VERSION "HNNBNNNYNNNNNNNNNNNNNNNNNNNNNNNNNNNNNNNNNN/4/%%%/4/'%**4NNN///"

NS_ :

BS_:

BU_: BAP_Tester BedienDisp_vo BedienSG_hi CGS DDA Gateway Gateway_PAG GurtMikrofon OTA_FC ZR_High ZR_LIMU ZR_MIB_TOP_ab_Gen3 ZR_Standard

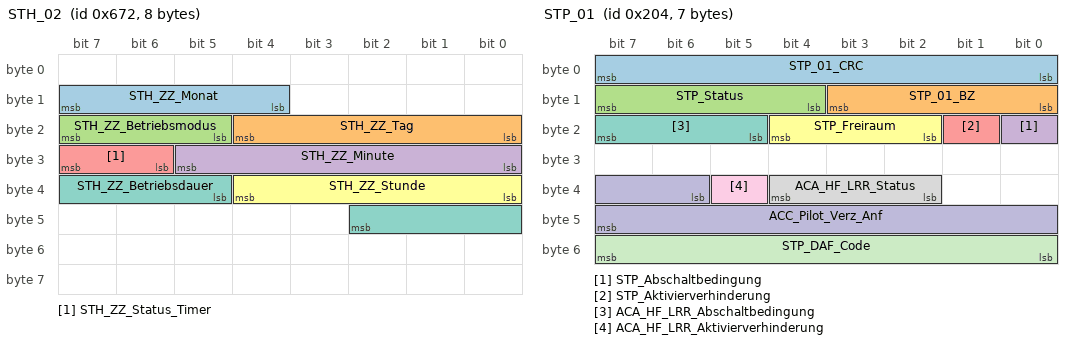
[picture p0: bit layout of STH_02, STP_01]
BO_ 1650 STH_02: 8 Gateway
 SG_ STH_ZZ_Monat : 12|4@1+ (1,0) [1|12] ""  ZR_High
 SG_ STH_ZZ_Tag : 16|5@1+ (1,0) [1|31] "Unit_Day"  ZR_High
 SG_ STH_ZZ_Betriebsmodus : 21|3@1+ (1.0,0.0) [0.0|7] ""  ZR_High
 SG_ STH_ZZ_Minute : 24|6@1+ (1,0) [0|59] ""  ZR_High
 SG_ STH_ZZ_Status_Timer : 30|2@1+ (1.0,0.0) [0.0|3] ""  ZR_High
 SG_ STH_ZZ_Stunde : 32|5@1+ (1,0) [0|23] ""  ZR_High
 SG_ STH_ZZ_Betriebsdauer : 37|6@1+ (1,0) [0|63] "Unit_Minut"  ZR_High

BO_ 516 STP_01: 7 Gateway
 SG_ STP_01_CRC : 0|8@1+ (1,0) [0|255] ""  Vector__XXX
 SG_ STP_01_BZ : 8|4@1+ (1,0) [0|15] ""  Vector__XXX
 SG_ STP_Status : 12|4@1+ (1.0,0.0) [0.0|15] ""  ZR_High,ZR_LIMU,ZR_MIB_TOP_ab_Gen3,ZR_Standard
 SG_ STP_Abschaltbedingung : 16|1@1+ (1.0,0.0) [0.0|1] ""  ZR_High
 SG_ STP_Aktivierverhinderung : 17|1@1+ (1.0,0.0) [0.0|1] ""  Vector__XXX
 SG_ STP_Freiraum : 18|3@1+ (1.0,0.0) [0.0|7] ""  ZR_High
 SG_ ACA_HF_LRR_Abschaltbedingung : 21|3@1+ (1.0,0.0) [0.0|7] ""  Vector__XXX
 SG_ ACA_HF_LRR_Status : 34|3@1+ (1.0,0.0) [0.0|7] ""  Vector__XXX
 SG_ ACA_HF_LRR_Aktivierverhinderung : 37|1@1+ (1.0,0.0) [0.0|1] ""  Vector__XXX
 SG_ ACC_Pilot_Verz_Anf : 38|10@1+ (0.024,-24.528) [-24.528|-0.024] "Unit_MeterPerSeconSquar"  Vector__XXX
 SG_ STP_DAF_Code : 48|8@1+ (1,0) [1|255] ""  Vector__XXX

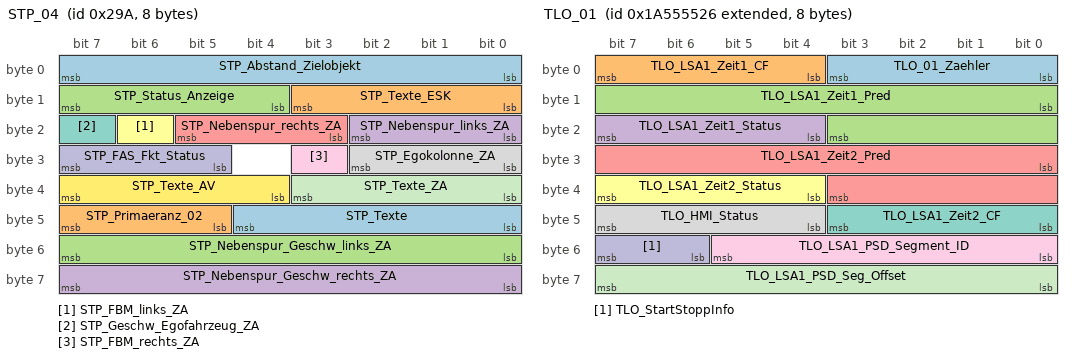
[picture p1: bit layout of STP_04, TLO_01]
BO_ 666 STP_04: 8 Gateway
 SG_ STP_Abstand_Zielobjekt : 0|8@1+ (1,0) [1|250] ""  Vector__XXX
 SG_ STP_Texte_ESK : 8|4@1+ (1.0,0.0) [0.0|15] ""  ZR_High,ZR_LIMU,ZR_MIB_TOP_ab_Gen3
 SG_ STP_Status_Anzeige : 12|4@1+ (1.0,0.0) [0.0|15] ""  ZR_High
 SG_ STP_Nebenspur_links_ZA : 16|3@1+ (1.0,0.0) [0.0|7] ""  ZR_High
 SG_ STP_Nebenspur_rechts_ZA : 19|3@1+ (1.0,0.0) [0.0|7] ""  ZR_High
 SG_ STP_FBM_links_ZA : 22|1@1+ (1.0,0.0) [0.0|1] ""  ZR_High
 SG_ STP_Geschw_Egofahrzeug_ZA : 23|1@1+ (1.0,0.0) [0.0|1] ""  Vector__XXX
 SG_ STP_Egokolonne_ZA : 24|3@1+ (1.0,0.0) [0.0|7] ""  ZR_High
 SG_ STP_FBM_rechts_ZA : 27|1@1+ (1.0,0.0) [0.0|1] ""  ZR_High
 SG_ STP_FAS_Fkt_Status : 29|3@1+ (1.0,0.0) [0.0|7] ""  ZR_High
 SG_ STP_Texte_ZA : 32|4@1+ (1.0,0.0) [0.0|15] ""  ZR_High
 SG_ STP_Texte_AV : 36|4@1+ (1.0,0.0) [0.0|15] ""  ZR_High,ZR_LIMU,ZR_MIB_TOP_ab_Gen3
 SG_ STP_Texte : 40|5@1+ (1.0,0.0) [0.0|31] ""  ZR_High,ZR_LIMU,ZR_MIB_TOP_ab_Gen3
 SG_ STP_Primaeranz_02 : 45|3@1+ (1.0,0.0) [0.0|7] ""  Vector__XXX
 SG_ STP_Nebenspur_Geschw_links_ZA : 48|8@1+ (1,0) [0|250] "Unit_KiloMeterPerHour"  Vector__XXX
 SG_ STP_Nebenspur_Geschw_rechts_ZA : 56|8@1+ (1,0) [0|250] "Unit_KiloMeterPerHour"  Vector__XXX

BO_ 1172 STS_01: 8 Gateway
 SG_ STS_01_CRC : 0|8@1+ (1,0) [0|255] ""  Vector__XXX
 SG_ STS_01_BZ : 8|4@1+ (1,0) [0|15] ""  Vector__XXX
 SG_ STS_Car_not_under_theft : 12|1@1+ (1.0,0.0) [0.0|1] ""  Vector__XXX
 SG_ STS_Car_under_theft : 13|1@1+ (1.0,0.0) [0.0|1] ""  Vector__XXX
 SG_ STS_Door_Lock : 14|1@1+ (1.0,0.0) [0.0|1] ""  ZR_High
 SG_ STS_Anlassersperre : 15|1@1+ (1.0,0.0) [0.0|1] ""  ZR_High
 SG_ STS_Typencodierung : 16|5@1+ (1.0,0.0) [0.0|31] ""  ZR_High
 SG_ STS_Spiegel_Anklappen : 21|1@1+ (1.0,0.0) [0.0|1] ""  ZR_High
 SG_ GW_STS2_Privatsphaere : 22|1@1+ (1.0,0.0) [0.0|1] ""  Vector__XXX
 SG_ STS_LIN_aktiv : 23|1@1+ (1.0,0.0) [0.0|1] ""  Vector__XXX
 SG_ STS_Standlicht : 24|1@1+ (1.0,0.0) [0.0|1] ""  Vector__XXX
 SG_ STS_Fahrlicht : 25|1@1+ (1.0,0.0) [0.0|1] ""  Vector__XXX
 SG_ STS_Alarm_still : 26|1@1+ (1.0,0.0) [0.0|1] ""  Vector__XXX
 SG_ STS_Texte : 27|4@1+ (1.0,0.0) [0.0|15] ""  Vector__XXX
 SG_ STS_Laderelais : 38|1@1+ (1.0,0.0) [0.0|1] ""  Vector__XXX
 SG_ STS_Summer : 48|1@1+ (1.0,0.0) [0.0|1] ""  Vector__XXX
 SG_ STS_Alarm_Blinker : 50|1@1+ (1.0,0.0) [0.0|1] ""  Vector__XXX
 SG_ STS_Notstart : 51|1@1+ (1.0,0.0) [0.0|1] ""  Vector__XXX
 SG_ STS_Signalhorn : 55|1@1+ (1.0,0.0) [0.0|1] ""  Vector__XXX
 SG_ STS_Leerlaufschaltung : 56|1@1+ (1.0,0.0) [0.0|1] ""  Vector__XXX

BO_ 783 SWA_01: 8 Gateway
 SG_ SWA_01_CRC : 0|8@1+ (1,0) [0|255] ""  Vector__XXX
 SG_ SWA_01_BZ : 8|4@1+ (1,0) [0|15] ""  Vector__XXX
 SG_ SWA_Anzeigen : 12|4@1+ (1.0,0.0) [0.0|15] ""  ZR_High
 SG_ SWA_Blindheit_erkannt : 16|1@1+ (1.0,0.0) [0.0|1] ""  Vector__XXX
 SG_ SWA_rel_Nichtverf : 17|1@1+ (1.0,0.0) [0.0|1] ""  Vector__XXX
 SG_ SWA_rel_Fehler : 18|1@1+ (1.0,0.0) [0.0|1] ""  ZR_High
 SG_ SWA_Sta_aktiv : 19|1@1+ (1.0,0.0) [0.0|1] ""  ZR_High
 SG_ SWA_Sta_passiv : 20|1@1+ (1.0,0.0) [0.0|1] ""  ZR_High
 SG_ SWA_FT_RueckLED : 21|1@1+ (1.0,0.0) [0.0|1] ""  ZR_High
 SG_ ASW_Status : 22|2@1+ (1.0,0.0) [0.0|3] ""  ZR_High
 SG_ SWA_Standziele_li : 24|1@1+ (1.0,0.0) [0.0|1] ""  ZR_High
 SG_ SWA_Kolonne_li : 25|1@1+ (1.0,0.0) [0.0|1] ""  Vector__XXX
 SG_ SWA_Infostufe_SWA_li : 26|1@1+ (1.0,0.0) [0.0|1] ""  ZR_High
 SG_ SWA_Warnung_SWA_li : 27|1@1+ (1.0,0.0) [0.0|1] ""  ZR_High
 SG_ ASW_Warnung_FS : 28|1@1+ (1.0,0.0) [0.0|1] ""  ZR_High
 SG_ ASW_Warnung_BFS : 29|1@1+ (1.0,0.0) [0.0|1] ""  ZR_High
 SG_ ASW_Kombitexte : 30|3@1+ (1.0,0.0) [0.0|7] ""  ZR_High
 SG_ SWA_Kolonne_mi : 33|1@1+ (1.0,0.0) [0.0|1] ""  Vector__XXX
 SG_ ASW_Modus : 34|3@1+ (1.0,0.0) [0.0|7] ""  ZR_High
 SG_ SWA_Modus : 37|3@1+ (1.0,0.0) [0.0|7] ""  ZR_High
 SG_ SWA_Standziele_re : 40|1@1+ (1.0,0.0) [0.0|1] ""  Vector__XXX
 SG_ SWA_Kolonne_re : 41|1@1+ (1.0,0.0) [0.0|1] ""  Vector__XXX
 SG_ SWA_Infostufe_SWA_re : 42|1@1+ (1.0,0.0) [0.0|1] ""  ZR_High
 SG_ SWA_Warnung_SWA_re : 43|1@1+ (1.0,0.0) [0.0|1] ""  ZR_High
 SG_ HRE_Anzeigetexte : 44|4@1+ (1.0,0.0) [0.0|15] ""  Vector__XXX
 SG_ SWA_Status_02 : 48|2@1+ (1.0,0.0) [0.0|3] ""  Vector__XXX
 SG_ Heckradar_Kombitexte : 56|5@1+ (1.0,0.0) [0.0|31] ""  ZR_High
 SG_ RCTA_Kombitexte : 61|3@1+ (1.0,0.0) [0.0|7] ""  ZR_High

BO_ 1413 Systeminfo_01: 8 Gateway
 SG_ SI_Sammel_SG_Fehler : 0|6@1+ (1,0) [0|60] ""  ZR_High,ZR_LIMU,ZR_MIB_TOP_ab_Gen3,ZR_Standard
 SG_ SI_Diagnose_Aktiv : 7|1@1+ (1.0,0.0) [0.0|1] ""  ZR_High,ZR_LIMU,ZR_MIB_TOP_ab_Gen3,ZR_Standard
 SG_ SI_QRS_Mode : 8|1@1+ (1.0,0.0) [0.0|1] ""  BedienSG_hi,ZR_High,ZR_LIMU,ZR_MIB_TOP_ab_Gen3,ZR_Standard
 SG_ SI_T_Mode : 9|1@1+ (1.0,0.0) [0.0|1] ""  BedienDisp_vo,BedienSG_hi,DDA,ZR_High,ZR_LIMU,ZR_MIB_TOP_ab_Gen3,ZR_Standard
 SG_ SI_NWDF : 10|1@1+ (1.0,0.0) [0.0|1] ""  BedienDisp_vo,BedienSG_hi,DDA,ZR_High,ZR_LIMU,ZR_MIB_TOP_ab_Gen3,ZR_Standard
 SG_ SI_NWDF_gueltig : 11|1@1+ (1.0,0.0) [0.0|1] ""  BedienDisp_vo,BedienSG_hi,DDA,ZR_High,ZR_LIMU,ZR_MIB_TOP_ab_Gen3,ZR_Standard
 SG_ SI_Sammelfehler : 12|1@1+ (1.0,0.0) [0.0|1] ""  ZR_High,ZR_LIMU,ZR_MIB_TOP_ab_Gen3,ZR_Standard
 SG_ GW_KD_Fehler : 13|1@1+ (1.0,0.0) [0.0|1] ""  ZR_High,ZR_MIB_TOP_ab_Gen3,ZR_Standard
 SG_ SI_T_Schutz : 14|1@1+ (1.0,0.0) [0.0|1] ""  BedienSG_hi,ZR_High,ZR_LIMU,ZR_MIB_TOP_ab_Gen3,ZR_Standard
 SG_ SI_BUS_01 : 16|1@1+ (1.0,0.0) [0.0|1] ""  ZR_High,ZR_LIMU,ZR_MIB_TOP_ab_Gen3,ZR_Standard
 SG_ SI_BUS_02 : 17|1@1+ (1.0,0.0) [0.0|1] ""  ZR_High,ZR_LIMU,ZR_MIB_TOP_ab_Gen3,ZR_Standard
 SG_ SI_BUS_03 : 18|1@1+ (1.0,0.0) [0.0|1] ""  BedienSG_hi,DDA,ZR_High,ZR_LIMU,ZR_MIB_TOP_ab_Gen3,ZR_Standard
 SG_ SI_BUS_04 : 19|1@1+ (1.0,0.0) [0.0|1] ""  BedienSG_hi,ZR_High,ZR_LIMU,ZR_MIB_TOP_ab_Gen3,ZR_Standard
 SG_ SI_BUS_05 : 20|1@1+ (1.0,0.0) [0.0|1] ""  ZR_High,ZR_LIMU,ZR_MIB_TOP_ab_Gen3,ZR_Standard
 SG_ SI_BUS_06 : 21|1@1+ (1.0,0.0) [0.0|1] ""  ZR_High,ZR_LIMU,ZR_MIB_TOP_ab_Gen3,ZR_Standard
 SG_ SI_BUS_07 : 22|1@1+ (1.0,0.0) [0.0|1] ""  ZR_High,ZR_LIMU,ZR_MIB_TOP_ab_Gen3,ZR_Standard
 SG_ SI_BUS_08 : 23|1@1+ (1.0,0.0) [0.0|1] ""  ZR_High,ZR_LIMU,ZR_MIB_TOP_ab_Gen3,ZR_Standard
 SG_ SI_BUS_09 : 24|1@1+ (1.0,0.0) [0.0|1] ""  ZR_High,ZR_LIMU,ZR_MIB_TOP_ab_Gen3,ZR_Standard
 SG_ SI_BUS_10 : 25|1@1+ (1.0,0.0) [0.0|1] ""  BedienSG_hi,DDA,ZR_High,ZR_LIMU,ZR_MIB_TOP_ab_Gen3,ZR_Standard
 SG_ SI_BUS_11 : 26|1@1+ (1.0,0.0) [0.0|1] ""  ZR_High,ZR_LIMU,ZR_MIB_TOP_ab_Gen3,ZR_Standard
 SG_ SI_BUS_12 : 27|1@1+ (1.0,0.0) [0.0|1] ""  DDA,ZR_High,ZR_LIMU,ZR_MIB_TOP_ab_Gen3,ZR_Standard
 SG_ SI_BUS_13 : 28|1@1+ (1.0,0.0) [0.0|1] ""  ZR_High,ZR_LIMU,ZR_MIB_TOP_ab_Gen3,ZR_Standard
 SG_ SI_BUS_14 : 29|1@1+ (1.0,0.0) [0.0|1] ""  ZR_High,ZR_LIMU,ZR_MIB_TOP_ab_Gen3,ZR_Standard
 SG_ SI_BUS_15 : 30|1@1+ (1.0,0.0) [0.0|1] ""  ZR_High,ZR_LIMU,ZR_MIB_TOP_ab_Gen3,ZR_Standard
 SG_ SI_Bus_Identifikation : 32|8@1+ (1.0,0.0) [0.0|255] ""  OTA_FC,ZR_High,ZR_LIMU,ZR_MIB_TOP_ab_Gen3,ZR_Standard
 SG_ SI_CAB : 40|24@1+ (1.0,0.0) [0.0|16777215] ""  BedienSG_hi,OTA_FC,ZR_High,ZR_LIMU,ZR_MIB_TOP_ab_Gen3,ZR_Standard

BO_ 2589283622 TLO_01: 8 ZR_High
 SG_ TLO_01_Zaehler : 0|4@1+ (1,0) [0|15] ""  Gateway,Gateway_PAG
 SG_ TLO_LSA1_Zeit1_CF : 4|4@1+ (1,0) [0|15] "Unit_None"  Gateway,Gateway_PAG
 SG_ TLO_LSA1_Zeit1_Pred : 8|12@1+ (0.1,-0.1) [0.0|409.4] "Unit_Secon"  Gateway,Gateway_PAG
 SG_ TLO_LSA1_Zeit1_Status : 20|4@1+ (1.0,0.0) [0.0|15] ""  Gateway,Gateway_PAG
 SG_ TLO_LSA1_Zeit2_Pred : 24|12@1+ (0.1,-0.1) [0.0|409.4] "Unit_Secon"  Gateway,Gateway_PAG
 SG_ TLO_LSA1_Zeit2_Status : 36|4@1+ (1.0,0.0) [0.0|15] ""  Gateway,Gateway_PAG
 SG_ TLO_LSA1_Zeit2_CF : 40|4@1+ (1,0) [0|15] "Unit_None"  Gateway,Gateway_PAG
 SG_ TLO_HMI_Status : 44|4@1+ (1.0,0.0) [0.0|15] ""  Gateway,Gateway_PAG
 SG_ TLO_LSA1_PSD_Segment_ID : 48|6@1+ (1,0) [2|63] "Unit_None"  Gateway,Gateway_PAG
 SG_ TLO_StartStoppInfo : 54|2@1+ (1.0,0.0) [0.0|3] ""  Gateway,Gateway_PAG
 SG_ TLO_LSA1_PSD_Seg_Offset : 56|8@1+ (1,0) [0|254] "Unit_Meter"  Gateway,Gateway_PAG

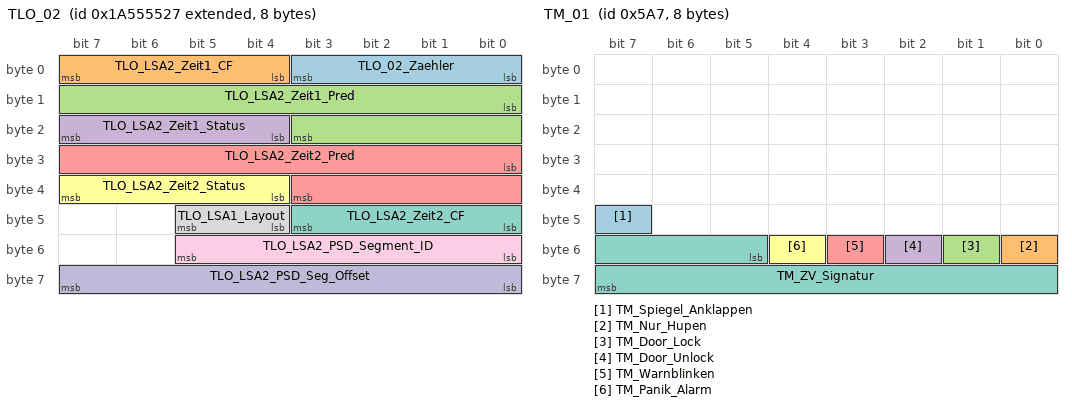
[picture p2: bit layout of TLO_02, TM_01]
BO_ 2589283623 TLO_02: 8 ZR_High
 SG_ TLO_02_Zaehler : 0|4@1+ (1,0) [0|15] ""  Gateway,Gateway_PAG
 SG_ TLO_LSA2_Zeit1_CF : 4|4@1+ (1,0) [0|15] "Unit_None"  Gateway,Gateway_PAG
 SG_ TLO_LSA2_Zeit1_Pred : 8|12@1+ (0.1,-0.1) [0.0|409.4] "Unit_Secon"  Gateway,Gateway_PAG
 SG_ TLO_LSA2_Zeit1_Status : 20|4@1+ (1.0,0.0) [0.0|15] ""  Gateway,Gateway_PAG
 SG_ TLO_LSA2_Zeit2_Pred : 24|12@1+ (0.1,-0.1) [0.0|409.4] "Unit_Secon"  Gateway,Gateway_PAG
 SG_ TLO_LSA2_Zeit2_Status : 36|4@1+ (1.0,0.0) [0.0|15] ""  Gateway,Gateway_PAG
 SG_ TLO_LSA2_Zeit2_CF : 40|4@1+ (1,0) [0|15] "Unit_None"  Gateway,Gateway_PAG
 SG_ TLO_LSA1_Layout : 44|2@1+ (1.0,0.0) [0.0|3] ""  Gateway,Gateway_PAG
 SG_ TLO_LSA2_PSD_Segment_ID : 48|6@1+ (1,0) [2|63] "Unit_None"  Gateway,Gateway_PAG
 SG_ TLO_LSA2_PSD_Seg_Offset : 56|8@1+ (1,0) [0|254] "Unit_Meter"  Gateway,Gateway_PAG

BO_ 1447 TM_01: 8 Gateway
 SG_ TM_Spiegel_Anklappen : 47|1@1+ (1.0,0.0) [0.0|1] ""  ZR_High
 SG_ TM_Nur_Hupen : 48|1@1+ (1.0,0.0) [0.0|1] ""  ZR_High
 SG_ TM_Door_Lock : 49|1@1+ (1.0,0.0) [0.0|1] ""  Vector__XXX
 SG_ TM_Door_Unlock : 50|1@1+ (1.0,0.0) [0.0|1] ""  Vector__XXX
 SG_ TM_Warnblinken : 51|1@1+ (1.0,0.0) [0.0|1] ""  ZR_High
 SG_ TM_Panik_Alarm : 52|1@1+ (1.0,0.0) [0.0|1] ""  ZR_High
 SG_ TM_ZV_Signatur : 53|11@1+ (1,0) [1|2047] "Unit_None"  Vector__XXX

BO_ 977 TSG_BT_01: 8 Gateway
 SG_ BT_Tuer_geoeffnet : 0|1@1+ (1.0,0.0) [0.0|1] ""  OTA_FC,ZR_High,ZR_LIMU,ZR_MIB_TOP_ab_Gen3,ZR_Standard
 SG_ BT_verriegelt : 1|1@1+ (1.0,0.0) [0.0|1] ""  OTA_FC,ZR_High
 SG_ BT_gesafet : 2|1@1+ (1.0,0.0) [0.0|1] ""  ZR_High
 SG_ BT_Schluesselschalter_auf : 3|1@1+ (1.0,0.0) [0.0|1] ""  ZR_High
 SG_ BT_Schluesselschalter_zu : 4|1@1+ (1.0,0.0) [0.0|1] ""  ZR_High
 SG_ BT_Unlock_Taster : 5|1@1+ (1.0,0.0) [0.0|1] ""  ZR_High
 SG_ BT_Lock_Taster : 6|1@1+ (1.0,0.0) [0.0|1] ""  ZR_High
 SG_ BT_Sperrklinke : 7|1@1+ (1.0,0.0) [0.0|1] ""  Vector__XXX
 SG_ BT_TAG_betaetigt : 8|1@1+ (1.0,0.0) [0.0|1] ""  ZR_High
 SG_ BT_TIG_betaetigt : 9|1@1+ (1.0,0.0) [0.0|1] ""  ZR_High
 SG_ BT_EC_Spiegel_Helligkeit : 10|5@1+ (3.125,0) [0.000|96.875] "Unit_PerCent"  OTA_FC,ZR_High
 SG_ BT_Sp_Heizung_Anf : 15|1@1+ (100,0) [0|100] "Unit_PerCent"  ZR_High
 SG_ BT_Tuer_Status : 16|2@1+ (1.0,0.0) [0.0|3] ""  OTA_FC,ZR_High
 SG_ BT_TSG_hinten_verbaut : 18|1@1+ (1.0,0.0) [0.0|1] ""  ZR_High
 SG_ BT_Sp_Blk_def : 19|1@1+ (1.0,0.0) [0.0|1] ""  ZR_High
 SG_ BT_FH_S_ManHoch : 20|1@1+ (1.0,0.0) [0.0|1] ""  ZR_High
 SG_ BT_FH_S_AutoHoch : 21|1@1+ (1.0,0.0) [0.0|1] ""  ZR_High
 SG_ BT_FH_S_ManTief : 22|1@1+ (1.0,0.0) [0.0|1] ""  ZR_High
 SG_ BT_FH_S_AutoTief : 23|1@1+ (1.0,0.0) [0.0|1] ""  ZR_High
 SG_ BT_FH_Oeffnung : 24|8@1+ (0.5,0) [0.0|100.0] "Unit_PerCent"  DDA,OTA_FC,ZR_High,ZR_LIMU,ZR_MIB_TOP_ab_Gen3,ZR_Standard
 SG_ BT_FH_Bew_hoch : 32|1@1+ (1.0,0.0) [0.0|1] ""  ZR_High
 SG_ BT_FH_Bew_tief : 33|1@1+ (1.0,0.0) [0.0|1] ""  ZR_High
 SG_ BT_FH_Fang : 34|1@1+ (1.0,0.0) [0.0|1] ""  ZR_High
 SG_ BT_FH_Block : 35|1@1+ (1.0,0.0) [0.0|1] ""  ZR_High
 SG_ BT_FH_Thermo : 36|1@1+ (1.0,0.0) [0.0|1] ""  ZR_High
 SG_ BT_UEKB_aktiviert : 37|1@1+ (1.0,0.0) [0.0|1] ""  Vector__XXX
 SG_ BT_Kisi_Fehler : 38|1@1+ (1.0,0.0) [0.0|1] ""  ZR_High
 SG_ BT_FH_normiert : 39|1@1+ (1.0,0.0) [0.0|1] ""  Vector__XXX
 SG_ BT_Schliesstaster : 40|1@1+ (1.0,0.0) [0.0|1] ""  ZR_High
 SG_ BT_Zuziehhilfe_aktiv : 41|1@1+ (1.0,0.0) [0.0|1] ""  OTA_FC,ZR_High
 SG_ BT_SP_ausgerastet : 42|1@1+ (1.0,0.0) [0.0|1] ""  ZR_High
 SG_ BT_SP_lr_aktiv : 43|1@1+ (1.0,0.0) [0.0|1] ""  ZR_High
 SG_ BT_SP_ht_aktiv : 44|1@1+ (1.0,0.0) [0.0|1] ""  ZR_High
 SG_ BT_SP_Heizung_aktiv : 45|1@1+ (1.0,0.0) [0.0|1] ""  Vector__XXX
 SG_ BT_Oben_Block_erw : 46|1@1+ (1.0,0.0) [0.0|1] ""  ZR_High
 SG_ BT_Unten_Block_erw : 47|1@1+ (1.0,0.0) [0.0|1] ""  ZR_High
 SG_ BT_Tuer_Status_QBit : 48|1@1+ (1.0,0.0) [0.0|1] ""  Vector__XXX
 SG_ BFS_Status_eTAG : 49|2@1+ (1.0,0.0) [0.0|3] ""  Vector__XXX
 SG_ BT_TCR_Mode_aktiv : 51|1@1+ (1.0,0.0) [0.0|1] ""  Vector__XXX
 SG_ BT_SP_Heizung_Status : 55|1@1+ (1.0,0.0) [0.0|1] ""  OTA_FC,ZR_High
 SG_ ASW_Warnung_aktiv_BFS : 56|1@1+ (1.0,0.0) [0.0|1] ""  ZR_High
 SG_ BT_FH_Pos_oben : 57|1@1+ (1.0,0.0) [0.0|1] ""  OTA_FC,ZR_High
 SG_ BT_Tuerschloss_defekt : 58|1@1+ (1.0,0.0) [0.0|1] ""  ZR_High
 SG_ BT_Tueroeffnen_Warnung : 59|1@1+ (1.0,0.0) [0.0|1] ""  Vector__XXX
 SG_ BT_Lock_Taster_inv : 60|1@1+ (1.0,0.0) [0.0|1] ""  ZR_High
 SG_ BT_Schluesselschalter_zu_inv : 61|1@1+ (1.0,0.0) [0.0|1] ""  ZR_High
 SG_ BT_SWA_HMI_defekt : 62|1@1+ (1.0,0.0) [0.0|1] ""  ZR_High
 SG_ BT_ASW_HMI_defekt : 63|1@1+ (1.0,0.0) [0.0|1] ""  ZR_High

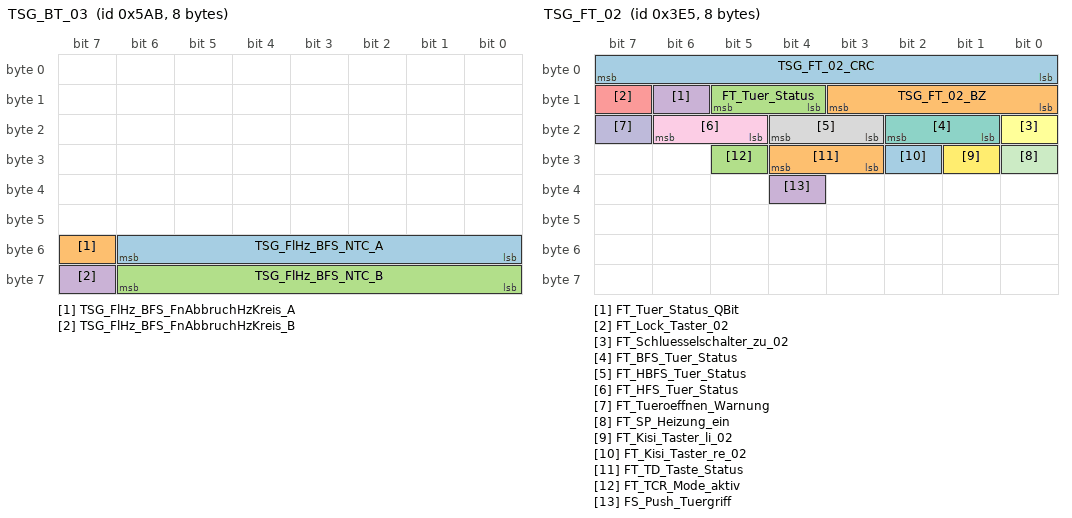
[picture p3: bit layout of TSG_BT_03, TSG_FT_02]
BO_ 1451 TSG_BT_03: 8 Gateway
 SG_ TSG_FlHz_BFS_NTC_A : 48|7@1+ (1,-40) [-40|80] "Unit_DegreCelsi"  ZR_High
 SG_ TSG_FlHz_BFS_FnAbbruchHzKreis_A : 55|1@1+ (1.0,0.0) [0.0|1] ""  ZR_High
 SG_ TSG_FlHz_BFS_NTC_B : 56|7@1+ (1,-40) [-40|80] "Unit_DegreCelsi"  ZR_High
 SG_ TSG_FlHz_BFS_FnAbbruchHzKreis_B : 63|1@1+ (1.0,0.0) [0.0|1] ""  ZR_High

BO_ 976 TSG_FT_01: 8 Gateway
 SG_ FT_Tuer_geoeffnet : 0|1@1+ (1.0,0.0) [0.0|1] ""  BedienDisp_vo,OTA_FC,ZR_High,ZR_LIMU,ZR_MIB_TOP_ab_Gen3,ZR_Standard
 SG_ FT_verriegelt : 1|1@1+ (1.0,0.0) [0.0|1] ""  OTA_FC,ZR_High
 SG_ FT_gesafet : 2|1@1+ (1.0,0.0) [0.0|1] ""  ZR_High
 SG_ FT_Schluesselschalter_auf : 3|1@1+ (1.0,0.0) [0.0|1] ""  ZR_High
 SG_ FT_Schluesselschalter_zu : 4|1@1+ (1.0,0.0) [0.0|1] ""  ZR_High
 SG_ FT_Unlock_Taster : 5|1@1+ (1.0,0.0) [0.0|1] ""  ZR_High
 SG_ FT_Lock_Taster : 6|1@1+ (1.0,0.0) [0.0|1] ""  ZR_High
 SG_ FT_Sperrklinke : 7|1@1+ (1.0,0.0) [0.0|1] ""  ZR_High
 SG_ FT_TAG_betaetigt : 8|1@1+ (1.0,0.0) [0.0|1] ""  ZR_High
 SG_ FT_TIG_betaetigt : 9|1@1+ (1.0,0.0) [0.0|1] ""  ZR_High
 SG_ FT_IRUE_Taste : 10|1@1+ (1.0,0.0) [0.0|1] ""  ZR_High
 SG_ FT_HD_Taste : 11|1@1+ (1.0,0.0) [0.0|1] ""  OTA_FC,ZR_High
 SG_ FT_TD_Taste_Fehler : 12|1@1+ (1.0,0.0) [0.0|1] ""  ZR_High
 SG_ FT_TD_Taste : 13|1@1+ (1.0,0.0) [0.0|1] ""  OTA_FC,ZR_High
 SG_ SSR_Temp_Freigabe : 14|1@1+ (1.0,0.0) [0.0|1] ""  Vector__XXX
 SG_ FT_Sp_Heizung_Anf : 15|1@1+ (100,0) [0|100] "Unit_PerCent"  OTA_FC,ZR_High
 SG_ FT_HD_Taste_2 : 16|1@1+ (1.0,0.0) [0.0|1] ""  ZR_High
 SG_ FT_TSG_hinten_verbaut : 18|1@1+ (1.0,0.0) [0.0|1] ""  ZR_High
 SG_ FT_Sp_Blk_def : 19|1@1+ (1.0,0.0) [0.0|1] ""  ZR_High
 SG_ FT_FH_S_ManHoch : 20|1@1+ (1.0,0.0) [0.0|1] ""  ZR_High
 SG_ FT_FH_S_AutoHoch : 21|1@1+ (1.0,0.0) [0.0|1] ""  ZR_High
 SG_ FT_FH_S_ManTief : 22|1@1+ (1.0,0.0) [0.0|1] ""  ZR_High
 SG_ FT_FH_S_AutoTief : 23|1@1+ (1.0,0.0) [0.0|1] ""  ZR_High
 SG_ FT_FH_Oeffnung : 24|8@1+ (0.5,0) [0.0|100.0] "Unit_PerCent"  DDA,OTA_FC,ZR_High,ZR_LIMU,ZR_MIB_TOP_ab_Gen3,ZR_Standard
 SG_ FT_FH_Bew_hoch : 32|1@1+ (1.0,0.0) [0.0|1] ""  ZR_High
 SG_ FT_FH_Bew_tief : 33|1@1+ (1.0,0.0) [0.0|1] ""  ZR_High
 SG_ FT_FH_Fang : 34|1@1+ (1.0,0.0) [0.0|1] ""  ZR_High
 SG_ FT_FH_Block : 35|1@1+ (1.0,0.0) [0.0|1] ""  ZR_High
 SG_ FT_FH_Thermo : 36|1@1+ (1.0,0.0) [0.0|1] ""  ZR_High
 SG_ FT_UEKB_aktiviert : 37|1@1+ (1.0,0.0) [0.0|1] ""  ZR_High
 SG_ ASW_HMI_defekt : 38|1@1+ (1.0,0.0) [0.0|1] ""  ZR_High
 SG_ FT_FH_normiert : 39|1@1+ (1.0,0.0) [0.0|1] ""  Vector__XXX
 SG_ FT_Schliesstaster : 40|1@1+ (1.0,0.0) [0.0|1] ""  ZR_High
 SG_ FT_Zuziehhilfe_aktiv : 41|1@1+ (1.0,0.0) [0.0|1] ""  OTA_FC,ZR_High
 SG_ FT_SP_ausgerastet : 42|1@1+ (1.0,0.0) [0.0|1] ""  ZR_High
 SG_ FT_SP_lr_aktiv : 43|1@1+ (1.0,0.0) [0.0|1] ""  OTA_FC,ZR_High
 SG_ FT_SP_ht_aktiv : 44|1@1+ (1.0,0.0) [0.0|1] ""  OTA_FC,ZR_High
 SG_ ASW_wakeup : 45|1@1+ (1.0,0.0) [0.0|1] ""  Vector__XXX
 SG_ FT_Oben_Block_erw : 46|1@1+ (1.0,0.0) [0.0|1] ""  ZR_High
 SG_ FT_Unten_Block_erw : 47|1@1+ (1.0,0.0) [0.0|1] ""  ZR_High
 SG_ FT_Kisi_li_aktiv : 48|1@1+ (1.0,0.0) [0.0|1] ""  BedienDisp_vo,BedienSG_hi,ZR_High,ZR_LIMU,ZR_MIB_TOP_ab_Gen3,ZR_Standard
 SG_ FT_Kisi_re_aktiv : 49|1@1+ (1.0,0.0) [0.0|1] ""  BedienDisp_vo,BedienSG_hi,ZR_High,ZR_LIMU,ZR_MIB_TOP_ab_Gen3,ZR_Standard
 SG_ FT_Kisi_Taster_li : 50|1@1+ (1.0,0.0) [0.0|1] ""  ZR_High
 SG_ FT_Kisi_Taster_re : 51|1@1+ (1.0,0.0) [0.0|1] ""  ZR_High
 SG_ FT_BFS_Fond_Freigabe : 52|1@1+ (1.0,0.0) [0.0|1] ""  ZR_High
 SG_ FT_Kisi_Fehler : 53|1@1+ (1.0,0.0) [0.0|1] ""  BedienSG_hi,ZR_High
 SG_ FT_Daemmglas : 54|1@1+ (1.0,0.0) [0.0|1] ""  ZR_High
 SG_ FT_SP_Heizung_Status : 55|1@1+ (1.0,0.0) [0.0|1] ""  OTA_FC,ZR_High
 SG_ ASW_Warnung_aktiv_FS : 56|1@1+ (1.0,0.0) [0.0|1] ""  ZR_High
 SG_ FT_FH_Pos_oben : 57|1@1+ (1.0,0.0) [0.0|1] ""  OTA_FC,ZR_High
 SG_ FT_Tuerschloss_defekt : 58|1@1+ (1.0,0.0) [0.0|1] ""  ZR_High
 SG_ FT_SWA_Taster : 59|1@1+ (1.0,0.0) [0.0|1] ""  ZR_High
 SG_ SWA_HMI_Diagnose : 60|2@1+ (1.0,0.0) [0.0|3] ""  ZR_High
 SG_ FS_Status_eTAG : 62|2@1+ (1.0,0.0) [0.0|3] ""  Vector__XXX

BO_ 997 TSG_FT_02: 8 Gateway
 SG_ TSG_FT_02_CRC : 0|8@1+ (1,0) [0|255] ""  Vector__XXX
 SG_ TSG_FT_02_BZ : 8|4@1+ (1,0) [0|15] ""  Vector__XXX
 SG_ FT_Tuer_Status : 12|2@1+ (1.0,0.0) [0.0|3] ""  OTA_FC,ZR_High
 SG_ FT_Tuer_Status_QBit : 14|1@1+ (1.0,0.0) [0.0|1] ""  ZR_High
 SG_ FT_Lock_Taster_02 : 15|1@1+ (1.0,0.0) [0.0|1] ""  ZR_High
 SG_ FT_Schluesselschalter_zu_02 : 16|1@1+ (1.0,0.0) [0.0|1] ""  ZR_High
 SG_ FT_BFS_Tuer_Status : 17|2@1+ (1.0,0.0) [0.0|3] ""  ZR_High
 SG_ FT_HBFS_Tuer_Status : 19|2@1+ (1.0,0.0) [0.0|3] ""  ZR_High
 SG_ FT_HFS_Tuer_Status : 21|2@1+ (1.0,0.0) [0.0|3] ""  ZR_High
 SG_ FT_Tueroeffnen_Warnung : 23|1@1+ (1.0,0.0) [0.0|1] ""  Vector__XXX
 SG_ FT_SP_Heizung_ein : 24|1@1+ (1.0,0.0) [0.0|1] ""  Vector__XXX
 SG_ FT_Kisi_Taster_li_02 : 25|1@1+ (1.0,0.0) [0.0|1] ""  ZR_High
 SG_ FT_Kisi_Taster_re_02 : 26|1@1+ (1.0,0.0) [0.0|1] ""  ZR_High
 SG_ FT_TD_Taste_Status : 27|2@1+ (1.0,0.0) [0.0|3] ""  ZR_High
 SG_ FT_TCR_Mode_aktiv : 29|1@1+ (1.0,0.0) [0.0|1] ""  Vector__XXX
 SG_ FS_Push_Tuergriff : 36|1@1+ (1.0,0.0) [0.0|1] ""  Vector__XXX

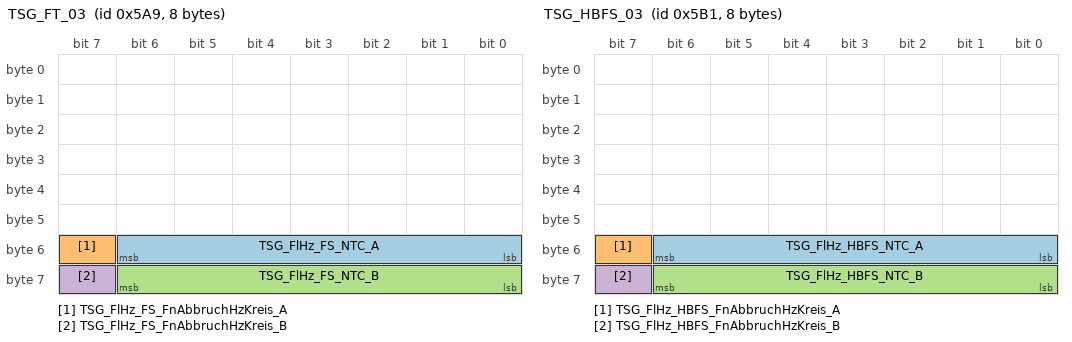
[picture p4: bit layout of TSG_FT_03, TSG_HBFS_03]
BO_ 1449 TSG_FT_03: 8 Gateway
 SG_ TSG_FlHz_FS_NTC_A : 48|7@1+ (1,-40) [-40|80] "Unit_DegreCelsi"  ZR_High
 SG_ TSG_FlHz_FS_FnAbbruchHzKreis_A : 55|1@1+ (1.0,0.0) [0.0|1] ""  ZR_High
 SG_ TSG_FlHz_FS_NTC_B : 56|7@1+ (1,-40) [-40|80] "Unit_DegreCelsi"  ZR_High
 SG_ TSG_FlHz_FS_FnAbbruchHzKreis_B : 63|1@1+ (1.0,0.0) [0.0|1] ""  ZR_High

BO_ 975 TSG_HBFS_01: 8 Gateway
 SG_ HBFS_Tuer_geoeffnet : 0|1@1+ (1.0,0.0) [0.0|1] ""  OTA_FC,ZR_High,ZR_LIMU,ZR_MIB_TOP_ab_Gen3,ZR_Standard
 SG_ HBFS_verriegelt : 1|1@1+ (1.0,0.0) [0.0|1] ""  ZR_High
 SG_ HBFS_gesafet : 2|1@1+ (1.0,0.0) [0.0|1] ""  ZR_High
 SG_ HBFS_Heckrollotaster_betaetigt : 3|1@1+ (1.0,0.0) [0.0|1] ""  ZR_High
 SG_ HBFS_Tuerschloss_defekt : 4|1@1+ (1.0,0.0) [0.0|1] ""  ZR_High
 SG_ HBFS_Unlock_Taster : 5|1@1+ (1.0,0.0) [0.0|1] ""  ZR_High
 SG_ HBFS_Lock_Taster : 6|1@1+ (1.0,0.0) [0.0|1] ""  ZR_High
 SG_ HBFS_Sperrklinke : 7|1@1+ (1.0,0.0) [0.0|1] ""  ZR_High
 SG_ HBFS_TAG_betaetigt : 8|1@1+ (1.0,0.0) [0.0|1] ""  ZR_High
 SG_ HBFS_TIG_betaetigt : 9|1@1+ (1.0,0.0) [0.0|1] ""  ZR_High
 SG_ HBFS_FH_S_HFS_AutoHoch : 10|1@1+ (1.0,0.0) [0.0|1] ""  ZR_High
 SG_ HBFS_FH_S_HFS_AutoTief : 11|1@1+ (1.0,0.0) [0.0|1] ""  ZR_High
 SG_ HBFS_FH_S_HFS_ManHoch : 12|1@1+ (1.0,0.0) [0.0|1] ""  ZR_High
 SG_ HBFS_FH_S_HFS_ManTief : 13|1@1+ (1.0,0.0) [0.0|1] ""  ZR_High
 SG_ HBFS_Tuer_Status : 14|2@1+ (1.0,0.0) [0.0|3] ""  OTA_FC,ZR_High
 SG_ HBFS_SAD_Schalter : 16|4@1+ (1.0,0.0) [0.0|15] ""  ZR_High
 SG_ HBFS_FH_S_ManHoch : 20|1@1+ (1.0,0.0) [0.0|1] ""  ZR_High
 SG_ HBFS_FH_S_AutoHoch : 21|1@1+ (1.0,0.0) [0.0|1] ""  ZR_High
 SG_ HBFS_FH_S_ManTief : 22|1@1+ (1.0,0.0) [0.0|1] ""  ZR_High
 SG_ HBFS_FH_S_AutoTief : 23|1@1+ (1.0,0.0) [0.0|1] ""  ZR_High
 SG_ HBFS_FH_Oeffnung : 24|8@1+ (0.5,0) [0.0|100.0] "Unit_PerCent"  DDA,OTA_FC,ZR_High,ZR_LIMU,ZR_MIB_TOP_ab_Gen3,ZR_Standard
 SG_ HBFS_FH_Bew_hoch : 32|1@1+ (1.0,0.0) [0.0|1] ""  ZR_High
 SG_ HBFS_FH_Bew_tief : 33|1@1+ (1.0,0.0) [0.0|1] ""  ZR_High
 SG_ HBFS_FH_Fang : 34|1@1+ (1.0,0.0) [0.0|1] ""  Vector__XXX
 SG_ HBFS_FH_Block : 35|1@1+ (1.0,0.0) [0.0|1] ""  ZR_High
 SG_ HBFS_FH_Thermo : 36|1@1+ (1.0,0.0) [0.0|1] ""  ZR_High
 SG_ HBFS_UEKB_aktiviert : 37|1@1+ (1.0,0.0) [0.0|1] ""  ZR_High
 SG_ HBFS_Tueroeffnen_Warnung : 38|1@1+ (1.0,0.0) [0.0|1] ""  Vector__XXX
 SG_ HBFS_FH_normiert : 39|1@1+ (1.0,0.0) [0.0|1] ""  BedienSG_hi,ZR_High
 SG_ ASW_Warnung_aktiv_HBFS : 40|1@1+ (1.0,0.0) [0.0|1] ""  ZR_High
 SG_ HBFS_Zuziehhilfe_aktiv : 41|1@1+ (1.0,0.0) [0.0|1] ""  OTA_FC,ZR_High
 SG_ HBFS_Seitenrollo_hoch : 42|1@1+ (1.0,0.0) [0.0|1] ""  BedienSG_hi,ZR_High
 SG_ HBFS_Seitenrollo_tief : 43|1@1+ (1.0,0.0) [0.0|1] ""  BedienSG_hi,ZR_High
 SG_ HBFS_Status_KiSi : 44|1@1+ (1.0,0.0) [0.0|1] ""  BedienSG_hi,ZR_High
 SG_ SSR_HBFS_Pos_Unten : 45|1@1+ (1.0,0.0) [0.0|1] ""  ZR_High
 SG_ HBFS_Oben_Block_erw : 46|1@1+ (1.0,0.0) [0.0|1] ""  ZR_High
 SG_ HBFS_Unten_Block_erw : 47|1@1+ (1.0,0.0) [0.0|1] ""  ZR_High
 SG_ MTHBFS_M_Taste : 48|1@1+ (1.0,0.0) [0.0|1] ""  ZR_High
 SG_ MTHBFS_Pos1 : 49|1@1+ (1.0,0.0) [0.0|1] ""  ZR_High
 SG_ MTHBFS_Pos2 : 50|1@1+ (1.0,0.0) [0.0|1] ""  ZR_High
 SG_ MTHBFS_Pos3 : 51|1@1+ (1.0,0.0) [0.0|1] ""  ZR_High
 SG_ HBFS_MRollo_Schalter : 52|3@1+ (1.0,0.0) [0.0|7] ""  ZR_High
 SG_ HBFS_Lock_Taster_inv : 55|1@1+ (1.0,0.0) [0.0|1] ""  ZR_High
 SG_ HBFS_Status_KiSi_inv : 56|1@1+ (1.0,0.0) [0.0|1] ""  ZR_High
 SG_ HBFS_Status_eTAG : 57|2@1+ (1.0,0.0) [0.0|3] ""  Vector__XXX
 SG_ HBFS_Tuer_Status_QBit : 59|1@1+ (1.0,0.0) [0.0|1] ""  Vector__XXX
 SG_ HBFS_TIG_betaetigt_schliessen : 60|1@1+ (1.0,0.0) [0.0|1] ""  Vector__XXX

BO_ 1457 TSG_HBFS_03: 8 Gateway
 SG_ TSG_FlHz_HBFS_NTC_A : 48|7@1+ (1,-40) [-40|80] "Unit_DegreCelsi"  ZR_High
 SG_ TSG_FlHz_HBFS_FnAbbruchHzKreis_A : 55|1@1+ (1.0,0.0) [0.0|1] ""  ZR_High
 SG_ TSG_FlHz_HBFS_NTC_B : 56|7@1+ (1,-40) [-40|80] "Unit_DegreCelsi"  ZR_High
 SG_ TSG_FlHz_HBFS_FnAbbruchHzKreis_B : 63|1@1+ (1.0,0.0) [0.0|1] ""  ZR_High

BO_ 974 TSG_HFS_01: 8 Gateway
 SG_ HFS_Tuer_geoeffnet : 0|1@1+ (1.0,0.0) [0.0|1] ""  OTA_FC,ZR_High,ZR_LIMU,ZR_MIB_TOP_ab_Gen3,ZR_Standard
 SG_ HFS_verriegelt : 1|1@1+ (1.0,0.0) [0.0|1] ""  ZR_High
 SG_ HFS_gesafet : 2|1@1+ (1.0,0.0) [0.0|1] ""  ZR_High
 SG_ HFS_Heckrollotaster_betaetigt : 3|1@1+ (1.0,0.0) [0.0|1] ""  ZR_High
 SG_ HFS_Tuerschloss_defekt : 4|1@1+ (1.0,0.0) [0.0|1] ""  ZR_High
 SG_ HFS_Unlock_Taster : 5|1@1+ (1.0,0.0) [0.0|1] ""  ZR_High
 SG_ HFS_Lock_Taster : 6|1@1+ (1.0,0.0) [0.0|1] ""  ZR_High
 SG_ HFS_Sperrklinke : 7|1@1+ (1.0,0.0) [0.0|1] ""  ZR_High
 SG_ HFS_TAG_betaetigt : 8|1@1+ (1.0,0.0) [0.0|1] ""  ZR_High
 SG_ HFS_TIG_betaetigt : 9|1@1+ (1.0,0.0) [0.0|1] ""  ZR_High
 SG_ HFS_FH_S_HBFS_AutoHoch : 10|1@1+ (1.0,0.0) [0.0|1] ""  ZR_High
 SG_ HFS_FH_S_HBFS_AutoTief : 11|1@1+ (1.0,0.0) [0.0|1] ""  ZR_High
 SG_ HFS_FH_S_HBFS_ManHoch : 12|1@1+ (1.0,0.0) [0.0|1] ""  ZR_High
 SG_ HFS_FH_S_HBFS_ManTief : 13|1@1+ (1.0,0.0) [0.0|1] ""  ZR_High
 SG_ HFS_Tuer_Status : 14|2@1+ (1.0,0.0) [0.0|3] ""  OTA_FC,ZR_High
 SG_ HFS_SAD_Schalter : 16|4@1+ (1.0,0.0) [0.0|15] ""  ZR_High
 SG_ HFS_FH_S_ManHoch : 20|1@1+ (1.0,0.0) [0.0|1] ""  ZR_High
 SG_ HFS_FH_S_AutoHoch : 21|1@1+ (1.0,0.0) [0.0|1] ""  ZR_High
 SG_ HFS_FH_S_ManTief : 22|1@1+ (1.0,0.0) [0.0|1] ""  ZR_High
 SG_ HFS_FH_S_AutoTief : 23|1@1+ (1.0,0.0) [0.0|1] ""  ZR_High
 SG_ HFS_FH_Oeffnung : 24|8@1+ (0.5,0) [0.0|100.0] "Unit_PerCent"  DDA,OTA_FC,ZR_High,ZR_LIMU,ZR_MIB_TOP_ab_Gen3,ZR_Standard
 SG_ HFS_FH_Bew_hoch : 32|1@1+ (1.0,0.0) [0.0|1] ""  ZR_High
 SG_ HFS_FH_Bew_tief : 33|1@1+ (1.0,0.0) [0.0|1] ""  ZR_High
 SG_ HFS_FH_Fang : 34|1@1+ (1.0,0.0) [0.0|1] ""  ZR_High
 SG_ HFS_FH_Block : 35|1@1+ (1.0,0.0) [0.0|1] ""  ZR_High
 SG_ HFS_FH_Thermo : 36|1@1+ (1.0,0.0) [0.0|1] ""  ZR_High
 SG_ HFS_UEKB_aktiviert : 37|1@1+ (1.0,0.0) [0.0|1] ""  ZR_High
 SG_ HFS_Tueroeffnen_Warnung : 38|1@1+ (1.0,0.0) [0.0|1] ""  Vector__XXX
 SG_ HFS_FH_normiert : 39|1@1+ (1.0,0.0) [0.0|1] ""  BedienSG_hi,ZR_High
 SG_ ASW_Warnung_aktiv_HFS : 40|1@1+ (1.0,0.0) [0.0|1] ""  ZR_High
 SG_ HFS_Zuziehhilfe_aktiv : 41|1@1+ (1.0,0.0) [0.0|1] ""  OTA_FC,ZR_High
 SG_ HFS_Seitenrollo_hoch : 42|1@1+ (1.0,0.0) [0.0|1] ""  BedienSG_hi,ZR_High
 SG_ HFS_Seitenrollo_tief : 43|1@1+ (1.0,0.0) [0.0|1] ""  BedienSG_hi,ZR_High
 SG_ HFS_Status_KiSi : 44|1@1+ (1.0,0.0) [0.0|1] ""  BedienSG_hi,ZR_High
 SG_ SSR_HFS_Pos_Unten : 45|1@1+ (1.0,0.0) [0.0|1] ""  ZR_High
 SG_ HFS_Oben_Block_erw : 46|1@1+ (1.0,0.0) [0.0|1] ""  ZR_High
 SG_ HFS_Unten_Block_erw : 47|1@1+ (1.0,0.0) [0.0|1] ""  ZR_High
 SG_ MTHFS_M_Taste : 48|1@1+ (1.0,0.0) [0.0|1] ""  ZR_High
 SG_ MTHFS_Pos1 : 49|1@1+ (1.0,0.0) [0.0|1] ""  ZR_High
 SG_ MTHFS_Pos2 : 50|1@1+ (1.0,0.0) [0.0|1] ""  ZR_High
 SG_ MTHFS_Pos3 : 51|1@1+ (1.0,0.0) [0.0|1] ""  ZR_High
 SG_ HFS_MRollo_Schalter : 52|3@1+ (1.0,0.0) [0.0|7] ""  ZR_High
 SG_ HFS_Lock_Taster_inv : 55|1@1+ (1.0,0.0) [0.0|1] ""  ZR_High
 SG_ HFS_Status_eTAG : 56|2@1+ (1.0,0.0) [0.0|3] ""  Vector__XXX
 SG_ HFS_Tuer_Status_QBit : 58|1@1+ (1.0,0.0) [0.0|1] ""  Vector__XXX
 SG_ HFS_TCR_Mode_aktiv : 59|1@1+ (1.0,0.0) [0.0|1] ""  Vector__XXX

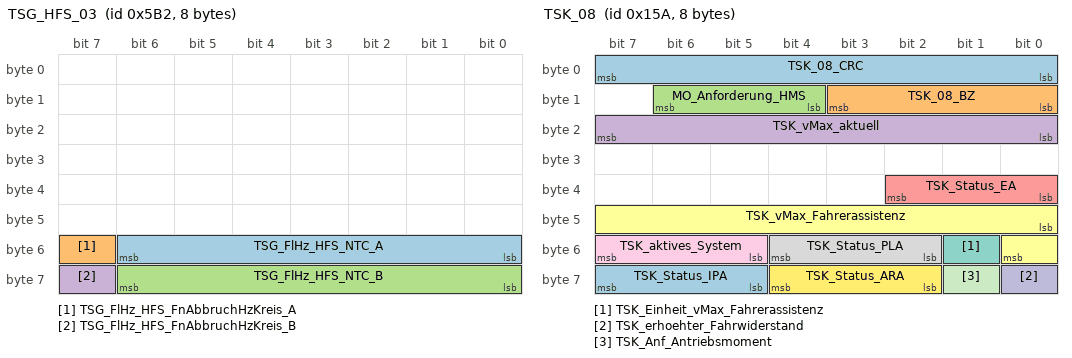
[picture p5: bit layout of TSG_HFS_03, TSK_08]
BO_ 1458 TSG_HFS_03: 8 Gateway
 SG_ TSG_FlHz_HFS_NTC_A : 48|7@1+ (1,-40) [-40|80] "Unit_DegreCelsi"  ZR_High
 SG_ TSG_FlHz_HFS_FnAbbruchHzKreis_A : 55|1@1+ (1.0,0.0) [0.0|1] ""  ZR_High
 SG_ TSG_FlHz_HFS_NTC_B : 56|7@1+ (1,-40) [-40|80] "Unit_DegreCelsi"  ZR_High
 SG_ TSG_FlHz_HFS_FnAbbruchHzKreis_B : 63|1@1+ (1.0,0.0) [0.0|1] ""  ZR_High

BO_ 346 TSK_08: 8 Gateway
 SG_ TSK_08_CRC : 0|8@1+ (1,0) [0|255] ""  Vector__XXX
 SG_ TSK_08_BZ : 8|4@1+ (1,0) [0|15] ""  Vector__XXX
 SG_ MO_Anforderung_HMS : 12|3@1+ (1.0,0.0) [0.0|7] ""  ZR_High
 SG_ TSK_vMax_aktuell : 16|8@1+ (1,0) [0|253] "Unit_KiloMeterPerHour"  OTA_FC
 SG_ TSK_Status_EA : 32|3@1+ (1.0,0.0) [0.0|7] ""  ZR_High
 SG_ TSK_vMax_Fahrerassistenz : 40|9@1+ (1,0) [0|510] ""  ZR_High
 SG_ TSK_Einheit_vMax_Fahrerassistenz : 49|1@1+ (1.0,0.0) [0.0|1] ""  ZR_High
 SG_ TSK_Status_PLA : 50|3@1+ (1.0,0.0) [0.0|7] ""  ZR_High
 SG_ TSK_aktives_System : 53|3@1+ (1.0,0.0) [0.0|7] ""  ZR_High
 SG_ TSK_erhoehter_Fahrwiderstand : 56|1@1+ (1.0,0.0) [0.0|1] ""  ZR_High
 SG_ TSK_Anf_Antriebsmoment : 57|1@1+ (1.0,0.0) [0.0|1] ""  ZR_High
 SG_ TSK_Status_ARA : 58|3@1+ (1.0,0.0) [0.0|7] ""  ZR_High
 SG_ TSK_Status_IPA : 61|3@1+ (1.0,0.0) [0.0|7] ""  ZR_High

BO_ 2589283609 UGDO_02: 8 Gateway
 SG_ UGDO_LED_Code_01 : 0|5@1+ (1.0,0.0) [0.0|31] ""  Vector__XXX
 SG_ UGDO_Function_01 : 5|3@1+ (1.0,0.0) [0.0|7] ""  Vector__XXX
 SG_ UGDO_Failure_Antenne : 8|1@1+ (1.0,0.0) [0.0|1] ""  Vector__XXX
 SG_ UGDO_Failure_Codierung : 9|1@1+ (1.0,0.0) [0.0|1] ""  Vector__XXX
 SG_ UGDO_Failure_Hardware : 10|1@1+ (1.0,0.0) [0.0|1] ""  Vector__XXX
 SG_ UGDO_ResponseError : 16|1@1+ (1.0,0.0) [0.0|1] ""  Vector__XXX
 SG_ UGDO_Channel_1 : 24|1@1+ (1.0,0.0) [0.0|1] ""  DDA
 SG_ UGDO_Channel_2 : 25|1@1+ (1.0,0.0) [0.0|1] ""  DDA
 SG_ UGDO_Channel_3 : 26|1@1+ (1.0,0.0) [0.0|1] ""  DDA
 SG_ UGDO_Channel_4 : 27|1@1+ (1.0,0.0) [0.0|1] ""  DDA
 SG_ UGDO_Channel_5 : 28|1@1+ (1.0,0.0) [0.0|1] ""  DDA
 SG_ UGDO_Channel_6 : 29|1@1+ (1.0,0.0) [0.0|1] ""  DDA
 SG_ UGDO_Channel_7 : 30|1@1+ (1.0,0.0) [0.0|1] ""  DDA
 SG_ UGDO_Channel_8 : 31|1@1+ (1.0,0.0) [0.0|1] ""  DDA
 SG_ UGDO_Channel_9 : 32|1@1+ (1.0,0.0) [0.0|1] ""  DDA
 SG_ UGDO_Channel_10 : 33|1@1+ (1.0,0.0) [0.0|1] ""  DDA
 SG_ UGDO_Channel_11 : 34|1@1+ (1.0,0.0) [0.0|1] ""  DDA
 SG_ UGDO_Channel_12 : 35|1@1+ (1.0,0.0) [0.0|1] ""  DDA
 SG_ UGDO_Channel_13 : 36|1@1+ (1.0,0.0) [0.0|1] ""  DDA
 SG_ UGDO_Channel_14 : 37|1@1+ (1.0,0.0) [0.0|1] ""  DDA
 SG_ UGDO_Channel_15 : 38|1@1+ (1.0,0.0) [0.0|1] ""  DDA
 SG_ UGDO_DoorState : 40|4@1+ (1.0,0.0) [0.0|15] ""  DDA,ZR_High

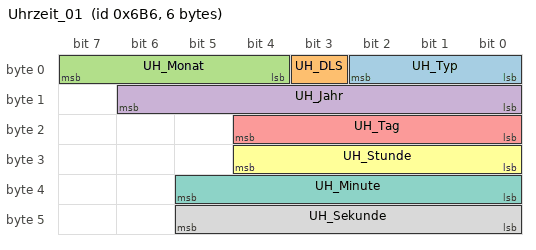
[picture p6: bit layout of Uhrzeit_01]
BO_ 1718 Uhrzeit_01: 6 Gateway
 SG_ UH_Typ : 0|3@1+ (1.0,0.0) [0.0|7] ""  BedienSG_hi,ZR_High
 SG_ UH_DLS : 3|1@1+ (1.0,0.0) [0.0|1] ""  BedienSG_hi,ZR_High
 SG_ UH_Monat : 4|4@1+ (1,0) [1|12] "Unit_Month"  Vector__XXX
 SG_ UH_Jahr : 8|7@1+ (1,2000) [2000|2127] "Unit_Year"  Vector__XXX
 SG_ UH_Tag : 16|5@1+ (1,0) [1|31] "Unit_Day"  Vector__XXX
 SG_ UH_Stunde : 24|5@1+ (1,0) [0|23] "Unit_Hours"  Vector__XXX
 SG_ UH_Minute : 32|6@1+ (1,0) [0|59] "Unit_Minut"  Vector__XXX
 SG_ UH_Sekunde : 40|6@1+ (1,0) [0|59] "Unit_Secon"  Vector__XXX

BO_TX_BU_ 1650 :Gateway,Gateway_PAG;
BO_TX_BU_ 516 :Gateway,Gateway_PAG;
BO_TX_BU_ 666 :Gateway,Gateway_PAG;
BO_TX_BU_ 1172 :Gateway,Gateway_PAG;
BO_TX_BU_ 783 :Gateway,Gateway_PAG;
BO_TX_BU_ 1413 :Gateway,Gateway_PAG;
BO_TX_BU_ 2589283622 :ZR_High,ZR_MIB_TOP_ab_Gen3;
BO_TX_BU_ 2589283623 :ZR_High,ZR_MIB_TOP_ab_Gen3;
BO_TX_BU_ 1447 :Gateway,Gateway_PAG;
BO_TX_BU_ 977 :Gateway,Gateway_PAG;
BO_TX_BU_ 1451 :Gateway,Gateway_PAG;
BO_TX_BU_ 976 :Gateway,Gateway_PAG;
BO_TX_BU_ 997 :Gateway,Gateway_PAG;
BO_TX_BU_ 1449 :Gateway,Gateway_PAG;
BO_TX_BU_ 975 :Gateway,Gateway_PAG;
BO_TX_BU_ 1457 :Gateway,Gateway_PAG;
BO_TX_BU_ 974 :Gateway,Gateway_PAG;
BO_TX_BU_ 1458 :Gateway,Gateway_PAG;
BO_TX_BU_ 346 :Gateway,Gateway_PAG;
BO_TX_BU_ 2589283609 :Gateway,Gateway_PAG;
BO_TX_BU_ 1718 :Gateway,Gateway_PAG;
CM_ BO_ 1650 "Zielzeittimeranzeige im Display des MMI";
CM_ BO_ 783 "ab MQB mit CRC-8";
CM_ BO_ 1413 "MQB, MLBevo";
CM_ BO_ 977 "ab MQB 7.05";
CM_ BO_ 976 "ab MQB 7.05";

CM_ SG_ 1650 STH_ZZ_Betriebsdauer "Betriebsdauer der Standheizung, die über die Funkfernbedienung verändert wurde";
CM_ SG_ 1650 STH_ZZ_Betriebsmodus "Betriebsdauerberechnung anhand Aussentemperaturauswertung mit Faktor 'ZZ_Betriebsmodus'";
CM_ SG_ 1650 STH_ZZ_Minute "Zielzeittimeranzeige im Display des MMI (Minute); Initwert ist der zuletzt gültige Wert";
CM_ SG_ 1650 STH_ZZ_Monat "Zielzeittimeranzeige im Display des MMI (Datum, Monat); Initwert ist der zuletzt gültige Wert";
CM_ SG_ 1650 STH_ZZ_Status_Timer "Zielzeittimeranzeige im Display des MMI (Timer aktiv/n.aktiv)";
CM_ SG_ 1650 STH_ZZ_Stunde "Zielzeittimeranzeige im Display des MMI (Stunde); Initwert ist der zuletzt gültige Wert";
CM_ SG_ 1650 STH_ZZ_Tag "Zielzeittimeranzeige im Display des MMI (Datum, Tag); Initwert ist der zuletzt gültige Wert";

CM_ SG_ 516 ACA_HF_LRR_Abschaltbedingung "Abschaltbedingung des Radar-Steuergeraetes für die ACA HandsFree Funktion";
CM_ SG_ 516 ACA_HF_LRR_Aktivierverhinderung "Aktivierverhinderung des Radar-Steuergeraetes für die ACA HandsFree Funktion";
CM_ SG_ 516 ACA_HF_LRR_Status "Bereitschaftsstatus des Radar-Steuergeraetes für die Umsetzung der ACA HandsFree Funktion";
CM_ SG_ 516 ACC_Pilot_Verz_Anf "Verzögerungsanforderung von STP an VZM";
CM_ SG_ 516 STP_01_BZ "Botschaftszähler
Botschaft asynchron geroutet. Zählerwert kann springen.";
CM_ SG_ 516 STP_01_CRC "End-to-End Absicherung";
CM_ SG_ 516 STP_Abschaltbedingung "Funktionsabschaltbedingungen von der Hauptfunktion";
CM_ SG_ 516 STP_Aktivierverhinderung "Funktionsaktivierverhinderungen von der Hauptfunktion";
CM_ SG_ 516 STP_DAF_Code "Codierter Abschaltgrund der Funktion Staupilot";
CM_ SG_ 516 STP_Freiraum "Aufzeichnung und Trigger für DAF";
CM_ SG_ 516 STP_Status "Zustandsbeschreibung für STP-Master-State-Machine";

CM_ SG_ 666 STP_Abstand_Zielobjekt "Signal dient zur Anzeige des Abstands des STP Zielobjekts im Kombi";
CM_ SG_ 666 STP_Egokolonne_ZA "Ansteuerung einer Anzeige der Fahrzeugkolonne auf der Egospur in der Zusatzanzeige";
CM_ SG_ 666 STP_FAS_Fkt_Status "Dient zur Interaktion mit dem FAS-Profilemaster. ";
CM_ SG_ 666 STP_FBM_links_ZA "Ansteuerung einer Anzeige der linken Fahrbahnmarkierung in der Zusatzanzeige";
CM_ SG_ 666 STP_FBM_rechts_ZA "Ansteuerung einer Anzeige der rechten Fahrbahnmarkierung in der Zusatzanzeige";
CM_ SG_ 666 STP_Geschw_Egofahrzeug_ZA "Zusatzinformation zur Anzeige des Fahrzeugs auf der Egospur in der Zusatzanzeige";
CM_ SG_ 666 STP_Nebenspur_Geschw_links_ZA "Anzeige von Seitenanimationen in der Kombi-Zusatzanzeige";
CM_ SG_ 666 STP_Nebenspur_Geschw_rechts_ZA "Anzeige von Seitenanimationen in der Kombi-Zusatzanzeige";
CM_ SG_ 666 STP_Nebenspur_links_ZA "Ansteuerung einer Anzeige von Objekten auf der linken Nebenspur in der Zusatzanzeige";
CM_ SG_ 666 STP_Nebenspur_rechts_ZA "Ansteuerung einer Anzeige von Objekten auf der rechten Nebenspur in der Zusatzanzeige";
CM_ SG_ 666 STP_Primaeranz_02 "Primaeranzeige des Staupiloten";
CM_ SG_ 666 STP_Status_Anzeige "Status nur zur Defintion von Anzeige im Kombi.";
CM_ SG_ 666 STP_Texte "Signal zur Ansteuerung von Warnungen und Fahrerhinweisen bzgl. des STP im Mitteldisplay";
CM_ SG_ 666 STP_Texte_AV "Grund der Aktivierverhinderung";
CM_ SG_ 666 STP_Texte_ESK "Grund der Eskalation";
CM_ SG_ 666 STP_Texte_ZA "Signal zur Ansteuerung eines Textes für Fahrerhinweise und bzgl. des STP-Systemzustands in der Zusatzanzeige";

CM_ SG_ 1172 GW_STS2_Privatsphaere "Übertraegt den Status der Privatsphaere vom ZR/MIB an das Steuergeraet VTS (STS2).";
CM_ SG_ 1172 STS_01_BZ "4bit Botschaftszähler, wird in jeder Sendebotschaft inkrementiert
";
CM_ SG_ 1172 STS_01_CRC "Für MLB:
'Berechnung siehe Lastenheft 'Kommunikationsabsicherung für FlexRay und CAN''

Ab MQB und MLBevo:
'Berechnung siehe Lastenheft 'End-to-End Kommunikationsabsicherung''

Endwerte siehe Begleitdokument 'S-PDU Kennungsfolgen'";
CM_ SG_ 1172 STS_Alarm_Blinker "Taxialarmblinken, wie DWA ohne Fanfare";
CM_ SG_ 1172 STS_Alarm_still "VTS hat einen Alarm erkannt. Alarm ist aber noch nicht bestätigt.";
CM_ SG_ 1172 STS_Anlassersperre "Wiederstartverhinderung (Anlassersperre)";
CM_ SG_ 1172 STS_Door_Lock "Remote Door lock angefordert: ZV zu/verriegeln";
CM_ SG_ 1172 STS_Fahrlicht "statisch oder auch mit Blink_modi für interm. Fahrlicht";
CM_ SG_ 1172 STS_Laderelais "Signal für die Auswertung zur Anzeige der Batterie-Schwach-Anzeige im Kombi ";
CM_ SG_ 1172 STS_Leerlaufschaltung "Versetzt das Fahrzeug in einen Zustand in dem es nicht mehr auf EGas-Anforderungen reagiert";
CM_ SG_ 1172 STS_LIN_aktiv "Tracking System über LIN";
CM_ SG_ 1172 STS_Notstart "Signal zeigt an, dass ein Notstart erfolgte.";
CM_ SG_ 1172 STS_Signalhorn "Versehrte, Fahrschule oder Taxi (bei Alarm)";
CM_ SG_ 1172 STS_Spiegel_Anklappen "Anklappen der Außenspiegel über Remote MOD Anforderung";
CM_ SG_ 1172 STS_Standlicht "statisch oder auch mit Blink_modi für Taxialarm";
CM_ SG_ 1172 STS_Summer "Warnsummer für Funkhauptschalter und Fahrschulpedal";
CM_ SG_ 1172 STS_Texte "Nummer des Textes die im Kombi angezeigt werden soll.

Signalwert ---- Meldungstext Audi ---- Meldungstext PAG:
0x0, kein_Text ---- kein Text ---- kein Text
0x1, Text_01 ---- kein Text ---- Driver Card nicht erkannt
0x2, Text_02 ---- Ortungsassistent";
CM_ SG_ 1172 STS_Typencodierung "Typcodierung Schnittstelle für Tracking Systeme
";

CM_ SG_ 783 ASW_Kombitexte "ASW_Kombitexte bestimmt welcher Text im Kombi angezeigt wird. Darüber hinaus werden auch Kombi-Akkustik durch dieses Signal ausgelöst.

Dieses Signal ersetzt SWA_Anzeigen für den ASW-Anteil. Der SWA-Anteil des alten Signals findet sich in SWA-Kombitexte";
CM_ SG_ 783 ASW_Modus "gibt die Verfügbarkeit der ASW Modus an";
CM_ SG_ 783 ASW_Status "Funktionsstatus Ausstiegswarnung (ASW)";
CM_ SG_ 783 ASW_Warnung_BFS "Modus Beifahrerseite der Funktion Ausstiegswarnung (ASW)";
CM_ SG_ 783 ASW_Warnung_FS "Modus Beifahrerseite der Funktion Ausstiegswarnung (ASW)";
CM_ SG_ 783 Heckradar_Kombitexte "Heckradar_Kombitexte bestimmt welcher Text im Kombi angezeigt wird. Darüber hinaus werden auch Kombi-Akkustik durch dieses Signal ausgelöst.

Dieses Signal ersetzt SWA_Anzeigen und deckt alle Kombinationsmöglichkeiten der Heckradarfunktionen ab. Die Fun";
CM_ SG_ 783 HRE_Anzeigetexte "HRE-Texte und -Akustik zur Anzeige im Kombiinstrument";
CM_ SG_ 783 RCTA_Kombitexte "RCTA_Kombitexte bestimmt welcher Text im Kombi angezeigt wird. Darüber hinaus werden auch Kombi-Akkustik durch dieses Signal ausgelöst.";
CM_ SG_ 783 SWA_01_BZ "Fehlende Beschreibung (Import)
Botschaft asynchron geroutet. Zählerwert kann springen.";
CM_ SG_ 783 SWA_01_CRC "Für MLB:
'Berechnung siehe Lastenheft 'Kommunikationsabsicherung für FlexRay und CAN''

Ab MQB und MLBevo:
'Berechnung siehe Lastenheft 'End-to-End Kommunikationsabsicherung''

Endwerte siehe Begleitdokument 'S-PDU Kennungsfolgen'";
CM_ SG_ 783 SWA_Anzeigen "SWA- Texte und -Akustik zur Anzeige im Kombiinstrument
0x5-0xF = reserviert
";
CM_ SG_ 783 SWA_Blindheit_erkannt "SWA erkennt selbständig eigene Blindheit durch äußere Einflüsse.";
CM_ SG_ 783 SWA_FT_RueckLED "SWA/ASW Rückmelde-LED. Zeigt den Aktivierungszustand der Funktionen SWA/ASW";
CM_ SG_ 783 SWA_Infostufe_SWA_li "Aktion der SWA-Funktion auf der entsprechenden Fahrzeugseite";
CM_ SG_ 783 SWA_Infostufe_SWA_re "Aktion der SWA-Funktion auf der entsprechenden Fahrzeugseite";
CM_ SG_ 783 SWA_Kolonne_li "Info, dass auf der entspr. Spur mehr als zwei Fahrzeuge zu finden sind. ";
CM_ SG_ 783 SWA_Kolonne_mi "Info, dass auf der entspr. Spur mehr als zwei Fahrzeuge zu finden sind. ";
CM_ SG_ 783 SWA_Kolonne_re "Info, dass auf der entspr. Spur mehr als zwei Fahrzeuge zu finden sind. ";
CM_ SG_ 783 SWA_Modus "gibt die Verfügbarkeit der SWA Modus an";
CM_ SG_ 783 SWA_rel_Fehler "Hinweis: In Zukunft das Signal SWA_Modus anstatt SWA_rel_Fehler verwenden!

SWA erkennt einen Fehler, die Objektdetektion betreffend, mit FSP-Eintrag.";
CM_ SG_ 783 SWA_rel_Nichtverf "Hinweis: In Zukunft das Signal SWA_Modus anstatt SWA_rel_Nichtverf verwenden!

SWA erkennt eine Nichtverfuegbarkeit, die Objektdetektion betreffend, ohne FSP-Eintrag";
CM_ SG_ 783 SWA_Sta_aktiv "SWA Status aktiv; Lampenansteuerung im Kombi";
CM_ SG_ 783 SWA_Sta_passiv "Hinweis: In Zukunft das Signal SWA_Status anstatt SWA_Sta_passiv verwenden!

SWA Status passiv; Lampenansteuerung im Kombi";
CM_ SG_ 783 SWA_Standziele_li "Hinweis: In Zukunft das Signal SWA_StrukturLinks_querAbstand anstatt SWA_Standziele_li verwenden!

Abstand zwischen Fahrzeug und Standziele links geringer als ein applizierbarer Wert.";
CM_ SG_ 783 SWA_Standziele_re "Hinweis: In Zukunft das Signal SWA_StrukturRechts_querAbstand anstatt SWA_Standziele_re verwenden!

Abstand zwischen Fahrzeug und Standziele links geringer als ein applizierbarer Wert.";
CM_ SG_ 783 SWA_Status_02 "gibt die Verfügbarkeit der SWA_Status an";
CM_ SG_ 783 SWA_Warnung_SWA_li "Aktion der SWA-Funktion auf der entsprechenden Fahrzeugseite";
CM_ SG_ 783 SWA_Warnung_SWA_re "Aktion der SWA-Funktion auf der entsprechenden Fahrzeugseite";

CM_ SG_ 1413 GW_KD_Fehler "Kundendienstfehlerbit Gateway zur Anzeige eines im Gateway abgelegten Fehlerspeichereintrages.";
CM_ SG_ 1413 SI_BUS_01 "MQB/MQB_A0/PQ26: ACAN
MQB2020: ACAN(FD)
MLBevo: HCAN
MEB: ACAN(FD)";
CM_ SG_ 1413 SI_BUS_02 "MQB/MQB A0 Standard+, High: FCAN
MQB2020: FCAN(FD)
MLBevo: Frei
MEB: FCAN(FD)";
CM_ SG_ 1413 SI_BUS_03 "MQB/MQB A0/PQ26: KCAN
MQB2020: KCAN
MLBevo: KCAN
MEB: KCAN";
CM_ SG_ 1413 SI_BUS_04 "MQB/MQB A0 Standard+, High: ICAN
MQB2020: ICAN
MLBevo: ICAN
MEB: ABCAN(FD)";
CM_ SG_ 1413 SI_BUS_05 "MQB/MQB A0/PQ26: DiagCAN
MQB2020: DiagCAN(FD)
MLBevo: DiagCAN
MEB: DiagCAN(FD)";
CM_ SG_ 1413 SI_BUS_06 "MQB/MQB A0/PQ26: ECAN
MQB2020: FASCAN(FD)
MLBevo: ECAN
MEB: FASCAN(FD)";
CM_ SG_ 1413 SI_BUS_07 "MQB: LIN1 (Energie)
MQB2020: LIN1 (Energie)
MLBevo: LIN1 (Energie)
MEB: LIN 1";
CM_ SG_ 1413 SI_BUS_08 "MQB: LIN2 (MFL)
MQB2020: LIN2 (MFL)
MLBevo: LIN2 (MFL)
MEB: LIN2";
CM_ SG_ 1413 SI_BUS_09 "MQB: LIN3 (unbelegt)
MQB2020: LIN3 (Uhr/FES)
MLBevo: LIN3 (Energie2)
MEB: LIN3";
CM_ SG_ 1413 SI_BUS_10 "MLBevo: Flexray

MQB2020: MCAN";
CM_ SG_ 1413 SI_BUS_11 "MLBevo: Ethernet
MEB: LIN4";
CM_ SG_ 1413 SI_BUS_12 "MQB: unbelegt
MLBevo: K2CAN
MEB: MFLCAN";
CM_ SG_ 1413 SI_BUS_13 "MQB: unbelegt
MLBevo: DCAN
MEB: CCAN";
CM_ SG_ 1413 SI_BUS_14 "MQB/MQB A0: unbelegt
MQB2020: HCAN
MLBevo: CCAN
MEB: EVCAN(FD)";
CM_ SG_ 1413 SI_BUS_15 "MQB: frei
MQB2020: frei
MLBevo: frei
MEB: AFSCAN";
CM_ SG_ 1413 SI_Bus_Identifikation "Das Signal identifiziert den Bus eindeutig. Das Signal ist konstant auf jedem Bus.
Der Signalwert entspricht dem Wert 'Busnummer' aus der VW80127 Gateway_component_list_databus_identification (0x2A2D) 'Bus-Identifier'.";
CM_ SG_ 1413 SI_CAB "CAB = Clusteraktivbits 
(Verwendung nur für Empfänger die nicht den AutoSar-SSW Stack implementiert haben)";
CM_ SG_ 1413 SI_Diagnose_Aktiv "Gibt an ob Diagnose-Botschaften empfangen werden und somit eine Diagnose aktiv ist.
MQB: Gibt an ob Diagnose-Bus Botschaften empfangen werden und somit eine Diagnose aktiv ist.";
CM_ SG_ 1413 SI_NWDF "Netzwerk-Diagnose Freigebe zur zentralen Aktivierung der Netzwerkdiagnose";
CM_ SG_ 1413 SI_NWDF_gueltig "Gültigkeitsbit zu SI_NWDF gemäß Lastenheft: Zentrale Aktivierung Netzwerkdiagnose";
CM_ SG_ 1413 SI_Sammel_SG_Fehler "Anzahl der gesetzten KD-Fehler direkt angeschlossener Steuergeräte der DK3 und DK4 gemäß 80127.
Hinweis: Ein Subbusmaster stellt nur die gesammelte Information der an ihn angeschlossenen Steuergeräte der DK3 und DK4 zur Verfügung.

Für ServiceKey Auswe";
CM_ SG_ 1413 SI_Sammelfehler "Sammelfehlermeldung zur Anzeige im Kombi - siehe Spez. Sammelfehlermeldung
Hinweis: Einzelne Steuergeräte können zur Anpassung an den Produktionsprozess im Gateway auskodiert werden!";
CM_ SG_ 1413 SI_T_Mode "0x0: Transportmodus nicht aktiv
0x1: Transportmodus aktiv";
CM_ SG_ 1413 SI_T_Schutz "Transportschutz-Signal, das bei Transportmodus und Motorlauf aktiv bleibt
0x0: Transportschutz nicht aktiv
0x1: Transportschutz aktiv";

CM_ SG_ 2589283622 TLO_01_Zaehler "Zaehler wird inkrementiert, wenn sich die Zuordnung zu den Signalgruppen aendert.
z.B. Neuer MPP, Kreuzungsueberfahrt, neuer AIO Pfad";
CM_ SG_ 2589283622 TLO_HMI_Status "Aktueller Anzeigestatus";
CM_ SG_ 2589283622 TLO_LSA1_PSD_Seg_Offset "Offset auf PSD Segment";
CM_ SG_ 2589283622 TLO_LSA1_PSD_Segment_ID "PSD Segment ID auf den die Haltelinie verortet wurde";
CM_ SG_ 2589283622 TLO_LSA1_Zeit1_CF "Güte der prädizierten LSA1 Zeit1";
CM_ SG_ 2589283622 TLO_LSA1_Zeit1_Pred "Prädizierte LSA1 Zeit1";
CM_ SG_ 2589283622 TLO_LSA1_Zeit1_Status "Status der aktuellen LSA1 Zeit1";
CM_ SG_ 2589283622 TLO_LSA1_Zeit2_CF "Güte der prädizierten LSA1 Zeit2";
CM_ SG_ 2589283622 TLO_LSA1_Zeit2_Pred "Prädizierte LSA1 Zeit2";
CM_ SG_ 2589283622 TLO_LSA1_Zeit2_Status "Status der aktuellen LSA1 Zeit2";
CM_ SG_ 2589283622 TLO_StartStoppInfo "Stopp-Freigabe und Start-Anforderung an den Start-Stopp-Koordinator";

CM_ SG_ 2589283623 TLO_02_Zaehler "Zaehler wird inkrementiert, wenn sich die Zuordnung zu den Signalgruppen aendert.
z.B. Neuer MPP, Kreuzungsueberfahrt, neuer AIO Pfad";
CM_ SG_ 2589283623 TLO_LSA1_Layout "Ampelausrichtung für die Ampel, auf die man zufährt (Schaltzeiten in TLO_01).";
CM_ SG_ 2589283623 TLO_LSA2_PSD_Seg_Offset "Offset auf PSD Segment";
CM_ SG_ 2589283623 TLO_LSA2_PSD_Segment_ID "PSD Segment ID auf den die Haltelinie verortet wurde";
CM_ SG_ 2589283623 TLO_LSA2_Zeit1_CF "Güte der prädizierten LSA2 Zeit1";
CM_ SG_ 2589283623 TLO_LSA2_Zeit1_Pred "Prädizierte LSA2 Zeit1";
CM_ SG_ 2589283623 TLO_LSA2_Zeit1_Status "Status der aktuellen LSA2 Zeit1";
CM_ SG_ 2589283623 TLO_LSA2_Zeit2_CF "Güte der prädizierten LSA2 Zeit2";
CM_ SG_ 2589283623 TLO_LSA2_Zeit2_Pred "Prädizierte LSA2 Zeit2";
CM_ SG_ 2589283623 TLO_LSA2_Zeit2_Status "Status der aktuellen LSA2 Zeit2";

CM_ SG_ 1447 TM_Door_Lock "Remote Door lock angefordert: ZV zu/verriegeln";
CM_ SG_ 1447 TM_Door_Unlock "Remote Door unlock angefordert: ZV auf/entriegeln";
CM_ SG_ 1447 TM_Nur_Hupen "Remote Hupen (ohne Blinken) aktiviert";
CM_ SG_ 1447 TM_Panik_Alarm "Remote Hupen und Blinken aktiv";
CM_ SG_ 1447 TM_Spiegel_Anklappen "Anklappen der Außenspiegel über Remote MOD Anforderung";
CM_ SG_ 1447 TM_Warnblinken "Remote Blinken aktiviert";
CM_ SG_ 1447 TM_ZV_Signatur "Gespeicherte Signatur der ZV für Authentifizierung";

CM_ SG_ 977 ASW_Warnung_aktiv_BFS "Abschaltung der Ambientefunktion Beifahrertür bei aktiver ASW Warnung an der Fahrertür";
CM_ SG_ 977 BFS_Status_eTAG "Status des elektrischen Tueraussengriffes Beifahrertuer";
CM_ SG_ 977 BT_ASW_HMI_defekt "Zeigt an, ob die ASW-Anzeige defekt ist.";
CM_ SG_ 977 BT_EC_Spiegel_Helligkeit "Dimmung für den Aussenspiegel in %";
CM_ SG_ 977 BT_FH_Bew_hoch "Fehlende Beschreibung (Import)";
CM_ SG_ 977 BT_FH_Bew_tief "Fehlende Beschreibung (Import)";
CM_ SG_ 977 BT_FH_Block "Fensterscheibe befindet sich im mechanischen Block (oben oder unten)";
CM_ SG_ 977 BT_FH_Fang "Fangbereich ist 4mm von oberer Lippendichtung";
CM_ SG_ 977 BT_FH_Oeffnung "Gibt den Fensteröffnungswert in % an.";
CM_ SG_ 977 BT_FH_S_AutoHoch "Fehlende Beschreibung (Import)";
CM_ SG_ 977 BT_FH_S_AutoTief "Fehlende Beschreibung (Import)";
CM_ SG_ 977 BT_FH_S_ManHoch "Fehlende Beschreibung (Import)";
CM_ SG_ 977 BT_FH_S_ManTief "Fehlende Beschreibung (Import)";
CM_ SG_ 977 BT_FH_Thermo "gibt an ob Fensterheber im Thermoschutz ist";
CM_ SG_ 977 BT_gesafet "Im Zustand Safe wird auch das Signal BT_verriegelt = 1 gesendet";
CM_ SG_ 977 BT_Kisi_Fehler "Fehlerstatus Kindersicherungsfunktion";
CM_ SG_ 977 BT_Lock_Taster "Verriegelungstaster";
CM_ SG_ 977 BT_Lock_Taster_inv "Lock Taster nicht betätigt";
CM_ SG_ 977 BT_Oben_Block_erw "Fehlende Beschreibung (Import)";
CM_ SG_ 977 BT_Schluesselschalter_auf "Fehlende Beschreibung (Import)";
CM_ SG_ 977 BT_Schluesselschalter_zu "Schluesselschalter Richtung zu betaetigt";
CM_ SG_ 977 BT_Schluesselschalter_zu_inv "Schluesselschalter zu nicht betaetigt";
CM_ SG_ 977 BT_SP_ausgerastet "Fehlende Beschreibung (Import)";
CM_ SG_ 977 BT_Sp_Blk_def "Fehlende Beschreibung (Import)";
CM_ SG_ 977 BT_Sp_Heizung_Anf "Kundenanforderung der Außenspiegelheizung Beifahrertür";
CM_ SG_ 977 BT_SP_Heizung_Status "Status der Spiegelheizung";
CM_ SG_ 977 BT_SP_ht_aktiv "Fehlende Beschreibung (Import)";
CM_ SG_ 977 BT_SP_lr_aktiv "Fehlende Beschreibung (Import)";
CM_ SG_ 977 BT_Sperrklinke "Vorraste für Schloß

zwischen Vor- und Hauptraste Signal kurz auf 1, danach wieder auf 0 wenn Tür in Hauptraste (Tür ist sicher zu wenn Sperrklinke und Türkontakt auf 0 sind)";
CM_ SG_ 977 BT_SWA_HMI_defekt "Zeigt an, ob die SWA-Anzeige defekt ist.";
CM_ SG_ 977 BT_TAG_betaetigt "Türaussengriff";
CM_ SG_ 977 BT_TCR_Mode_aktiv "Signal zeigt eine aktive mechanische Redundanz am Türschloss an.";
CM_ SG_ 977 BT_TIG_betaetigt "Türinnengriff";
CM_ SG_ 977 BT_Tuer_geoeffnet "
";
CM_ SG_ 977 BT_Tuer_Status "Türstatus mit Fehler und Initwert";
CM_ SG_ 977 BT_Tuer_Status_QBit "Dieses Bit gibt die Zuverlässigkeit des Türkontakts an.";
CM_ SG_ 977 BT_Tueroeffnen_Warnung "Bit wird gesetzt, wenn Tür während der Fahrt geoeffnet werden soll.";
CM_ SG_ 977 BT_Tuerschloss_defekt "Das Beifahrertürschloss ist nicht mehr funktionsfähig.";
CM_ SG_ 977 BT_UEKB_aktiviert "Überschutzbegrenzungskraft bei Reversieren";
CM_ SG_ 977 BT_Unlock_Taster "Fehlende Beschreibung (Import)";
CM_ SG_ 977 BT_Unten_Block_erw "Fehlende Beschreibung (Import)";
CM_ SG_ 977 BT_verriegelt "Fehlende Beschreibung (Import)";

CM_ SG_ 1451 TSG_FlHz_BFS_FnAbbruchHzKreis_A "Flächenheizung: Status";
CM_ SG_ 1451 TSG_FlHz_BFS_FnAbbruchHzKreis_B "Flächenheizung: Status";
CM_ SG_ 1451 TSG_FlHz_BFS_NTC_A "Flächenheizung: Temperatur und Fehlerwert des Heizaktors";
CM_ SG_ 1451 TSG_FlHz_BFS_NTC_B "Flächenheizung: Temperatur und Fehlerwert des Heizaktors";

CM_ SG_ 976 ASW_HMI_defekt "HMI Status der Funktion AusstiegsWarnung (ASW). HMI wird durch das TSG angesteuert.";
CM_ SG_ 976 ASW_wakeup "Trigger Start Nachlaufzeit t_1 für die Funktion Ausstieswarnung (ASW)";
CM_ SG_ 976 ASW_Warnung_aktiv_FS "Abschaltung der Ambientefunktion Fahrertür bei aktiver ASW Warnung an der Fahrertür";
CM_ SG_ 976 FS_Status_eTAG "Status des elektrischen Tueraussengriffes Fahrertuer";
CM_ SG_ 976 FT_Daemmglas "Fehlende Beschreibung (Import)";
CM_ SG_ 976 FT_FH_Bew_hoch "Fehlende Beschreibung (Import)";
CM_ SG_ 976 FT_FH_Bew_tief "Fehlende Beschreibung (Import)";
CM_ SG_ 976 FT_FH_Block "Fensterscheibe befindet sich im mechanischen Block (oben oder unten)";
CM_ SG_ 976 FT_FH_Fang "Fangbereich ist 4mm von oberer Lippendichtung";
CM_ SG_ 976 FT_FH_Oeffnung "Gibt den Fensteröffnungswert in % an.";
CM_ SG_ 976 FT_FH_S_AutoHoch "Fehlende Beschreibung (Import)";
CM_ SG_ 976 FT_FH_S_AutoTief "Fehlende Beschreibung (Import)";
CM_ SG_ 976 FT_FH_S_ManHoch "Fehlende Beschreibung (Import)";
CM_ SG_ 976 FT_FH_S_ManTief "Fehlende Beschreibung (Import)";
CM_ SG_ 976 FT_FH_Thermo "gibt an ob Fensterheber im Thermoschutz ist";
CM_ SG_ 976 FT_gesafet "Im Zustand Safe wird auch das Signal FT_verriegelt = 1 gesendet";
CM_ SG_ 976 FT_HD_Taste "Fehlende Beschreibung (Import)";
CM_ SG_ 976 FT_HD_Taste_2 "2. HD-Taste im Bedienfeld 
Funktion: Heckdeckel schließen";
CM_ SG_ 976 FT_IRUE_Taste "Betätigung IRUE-Taster (Innenraumüberwachung)
MQB: Bei Verbau eines einzelnen Taster zur Deaktivierung von IRUE und NGS wird dieses Signal als Deaktivierungsanforderung beider DWA-Alarmquellen gesendet.";
CM_ SG_ 976 FT_Kisi_Fehler "Fehlerstatus Kindersicherungsfunktion";
CM_ SG_ 976 FT_Kisi_li_aktiv "Aktivierungsstatus der Kindersicherung links";
CM_ SG_ 976 FT_Kisi_re_aktiv "Aktivierungsstatus der Kindersicherung rechts";
CM_ SG_ 976 FT_Kisi_Taster_li "Linker Kisi Taster betaetigt";
CM_ SG_ 976 FT_Kisi_Taster_re "Rechter Kisi Taster betaetigt";
CM_ SG_ 976 FT_Lock_Taster "Fehlende Beschreibung (Import)";
CM_ SG_ 976 FT_Oben_Block_erw "Fehlende Beschreibung (Import)";
CM_ SG_ 976 FT_Schliesstaster "Vorhalt";
CM_ SG_ 976 FT_Schluesselschalter_auf "Fehlende Beschreibung (Import)";
CM_ SG_ 976 FT_SP_ausgerastet "Fehlende Beschreibung (Import)";
CM_ SG_ 976 FT_Sp_Heizung_Anf "Kundenanforderung der Außenspiegelheizung Fahrertür";
CM_ SG_ 976 FT_SP_Heizung_Status "Status der Spiegelheizung";
CM_ SG_ 976 FT_SP_ht_aktiv "Fehlende Beschreibung (Import)";
CM_ SG_ 976 FT_SP_lr_aktiv "Fehlende Beschreibung (Import)";
CM_ SG_ 976 FT_Sperrklinke "Vorraste für Schloß

zwischen Vor- und Hauptraste Signal kurz auf 1, danach wieder auf 0 wenn Tür in Hauptraste (Tür ist sicher zu wenn Sperrklinke und Türkontakt auf 0 sind)";
CM_ SG_ 976 FT_SWA_Taster "SWA/ASW Taster Fahrertür";
CM_ SG_ 976 FT_TAG_betaetigt "Türaussengriff

wird nicht im MLB-B8 verwendet";
CM_ SG_ 976 FT_TD_Taste_Fehler "Fehlerstatus des Tankdeckelentriegelungstasters. Wird bei Drucktankkonzepten vom MSG zusammen mit dem Signal FT_TD_Taste ausgewertet, um Tankbereitschaft herzustellen.
Der Fehler beschreibt einen hängenden TD_Taster. Ein Kurzschluss oder Leitungsunterbre";
CM_ SG_ 976 FT_TIG_betaetigt "Türinnengriff

wird nicht im MLB-B8 verwendet";
CM_ SG_ 976 FT_Tuer_geoeffnet "Fehlende Beschreibung (Import)";
CM_ SG_ 976 FT_Tuerschloss_defekt "Das Fahrertürschloss ist nicht mehr funktionsfähig.";
CM_ SG_ 976 FT_UEKB_aktiviert "Überschutzbegrenzungskraft bei Reversieren";
CM_ SG_ 976 FT_Unlock_Taster "Fehlende Beschreibung (Import)";
CM_ SG_ 976 FT_Unten_Block_erw "Fehlende Beschreibung (Import)";
CM_ SG_ 976 FT_verriegelt "Fehlende Beschreibung (Import)";
CM_ SG_ 976 FT_Zuziehhilfe_aktiv "Fehlende Beschreibung (Import)";
CM_ SG_ 976 SSR_Temp_Freigabe "Freigabe des Seitenscheibenrollos. Bit wird  für die Deaktivierung des SSR bei Innenraumtemperaturen kleiner -10 Grad verwendet.";
CM_ SG_ 976 SWA_HMI_Diagnose "SWA HMI Diagnose beim TSG";

CM_ SG_ 997 FS_Push_Tuergriff "Push zum Ausfahren der Flush-Tuergriffe";
CM_ SG_ 997 FT_BFS_Tuer_Status "Gesammelte Türstatusbotschaft";
CM_ SG_ 997 FT_HBFS_Tuer_Status "Türstatus mit Fehler und Initwert";
CM_ SG_ 997 FT_HFS_Tuer_Status "Türstatus mit Fehler und Initwert";
CM_ SG_ 997 FT_Kisi_Taster_li_02 "Der Kindersicherungstaster hinten links aktiv.";
CM_ SG_ 997 FT_Kisi_Taster_re_02 "Der Kindersicherungstaster hinten rechts aktiv.";
CM_ SG_ 997 FT_Lock_Taster_02 "Lock-Taster betätigt";
CM_ SG_ 997 FT_Schluesselschalter_zu_02 "Schlüsselschalter für Schließen betätigt";
CM_ SG_ 997 FT_SP_Heizung_ein "Dieses Signal zeigt die tatsächliche Ansteuerung der  Spiegelheizung incl. PWM an. 
Zudem wird aufgrund des Teilnetzbetriebs das Signal zur Ansteuerung der Beifahrer-Spiegelheizung benutzt.

";
CM_ SG_ 997 FT_TCR_Mode_aktiv "Signal zeigt eine aktive mechanische Redundanz am Türschloss an.";
CM_ SG_ 997 FT_TD_Taste_Status "Status Taste für Tankdeckel";
CM_ SG_ 997 FT_Tuer_Status "Tür geöffnet oder Tür geschlossen";
CM_ SG_ 997 FT_Tuer_Status_QBit "Dieses Bit gibt die Zuverlässigkeit des Türkontakts an.";
CM_ SG_ 997 FT_Tueroeffnen_Warnung "Bit wird gesetzt, wenn Tür während der Fahrt geoeffnet werden soll.";
CM_ SG_ 997 TSG_FT_02_BZ "4bit Botschaftszaehler, wird mit jeder Sendebotschaft inkrementiert";
CM_ SG_ 997 TSG_FT_02_CRC "Für MLB:
'Berechnung siehe Lastenheft 'Kommunikationsabsicherung für FlexRay und CAN''

Ab MQB und MLBevo:
'Berechnung siehe Lastenheft 'End-to-End Kommunikationsabsicherung''

Endwerte siehe Begleitdokument 'S-PDU Kennungsfolgen'";

CM_ SG_ 1449 TSG_FlHz_FS_FnAbbruchHzKreis_A "Flächenheizung: Status";
CM_ SG_ 1449 TSG_FlHz_FS_FnAbbruchHzKreis_B "Flächenheizung: Status";
CM_ SG_ 1449 TSG_FlHz_FS_NTC_A "Flächenheizung: Temperatur und Fehlerwert des Heizaktors";
CM_ SG_ 1449 TSG_FlHz_FS_NTC_B "Flächenheizung: Temperatur und Fehlerwert des Heizaktors";

CM_ SG_ 975 ASW_Warnung_aktiv_HBFS "Abschaltung der Ambientefunktion Tür hinten der Beifahrerseite bei aktiver ASW Warnung an der Fahrertür";
CM_ SG_ 975 HBFS_FH_Bew_hoch "HBFS Fenster bewegt sich in Richtung hoch";
CM_ SG_ 975 HBFS_FH_Bew_tief "HFS Fenster bewegt sich in Richtung tief";
CM_ SG_ 975 HBFS_FH_Block "Fensterscheibe befindet sich im mechanischen Block (oben oder unten)";
CM_ SG_ 975 HBFS_FH_Fang "Fangbereich ist 4mm von oberer Lippendichtung";
CM_ SG_ 975 HBFS_FH_Oeffnung "Gibt den Fensteröffnungswert in % an.";
CM_ SG_ 975 HBFS_FH_S_AutoHoch "Betaetigung FH Schalter auto tief ";
CM_ SG_ 975 HBFS_FH_S_AutoTief "Betaetigung FH Schalter auto hoch";
CM_ SG_ 975 HBFS_FH_S_HFS_AutoHoch "Automatisches Hochfahren der Seitenscheibe HFS";
CM_ SG_ 975 HBFS_FH_S_HFS_AutoTief "Automatisches Absenken der Seitenscheibe HFS";
CM_ SG_ 975 HBFS_FH_S_HFS_ManHoch "Manuelles Hochfahren der Seitenscheibe HFS";
CM_ SG_ 975 HBFS_FH_S_HFS_ManTief "Manuelles Absenken der Seitenscheibe HFS";
CM_ SG_ 975 HBFS_FH_S_ManHoch "Betaetigung FH Schalter man hoch ";
CM_ SG_ 975 HBFS_FH_S_ManTief "Betaetigung FH Schalter man tief";
CM_ SG_ 975 HBFS_FH_Thermo "gibt an ob Fensterheber im Thermoschutz ist";
CM_ SG_ 975 HBFS_gesafet "HBFS Tuer gesafet.
Im Zustand Safe wird auch das Signal HBFS_verriegelt = 1 gesendet.";
CM_ SG_ 975 HBFS_Heckrollotaster_betaetigt "Verfahren des Heckrollos in Richtung Hoch

Bei Einfachtaster wird Bit als Togglebit verwendet (Heckrollo hoch, tief)";
CM_ SG_ 975 HBFS_Lock_Taster "Betaetigung Lock-Taster";
CM_ SG_ 975 HBFS_Lock_Taster_inv "Lock Taster nicht betätigt";
CM_ SG_ 975 HBFS_MRollo_Schalter "  | MRollo2
-----------------------------
0 | nicht_betaetigt
1 | (m) Zu
2 | (a) Zu
3 | (m) Auf
4 | (a) Auf
5 | Schalter nicht verfuegbar
6 | Init
7 | Fehlerfall";
CM_ SG_ 975 HBFS_Oben_Block_erw "Fensterheber in Blockerwartung oben";
CM_ SG_ 975 HBFS_SAD_Schalter "  |   Ausstelldach MD3
-----------------------------
0 | nicht_betaetigt
1 |
2 |
3 |
4 |
5 | (m) Auf
6 | (a) Auf
7 | (m) Zu
8 | (a) Zu
13| Schalter nicht verfuegbar
14| Init
15| Fehlerfall";
CM_ SG_ 975 HBFS_Sperrklinke "Vorraste für Schloß

zwischen Vor- und Hauptraste Signal kurz auf 1, danach wieder auf 0 wenn Tür in Hauptraste (Tür ist sicher zu wenn Sperrklinke und Türkontakt auf 0 sind)";
CM_ SG_ 975 HBFS_Status_eTAG "Status des elektrischen Tueraussengriffes Tuer Beifahrerseite hinten";
CM_ SG_ 975 HBFS_Status_KiSi "Status Kindersicherung HBFS
";
CM_ SG_ 975 HBFS_Status_KiSi_inv "Inverser Status der elektrischen Kindersicherung Beifahrerseite hinten";
CM_ SG_ 975 HBFS_TAG_betaetigt "Betaetigung Türaussengriff";
CM_ SG_ 975 HBFS_TIG_betaetigt "Betaetigung Tuerinnengriff";
CM_ SG_ 975 HBFS_TIG_betaetigt_schliessen "Türinnenbetätigung, Taster Tür schließen.";
CM_ SG_ 975 HBFS_Tuer_geoeffnet "HBFS Tuer geoeffnet";
CM_ SG_ 975 HBFS_Tuer_Status "Türstatus mit Fehler und Initwert";
CM_ SG_ 975 HBFS_Tuer_Status_QBit "Dieses Bit gibt die Zuverlässigkeit des Türkontakts an.";
CM_ SG_ 975 HBFS_Tueroeffnen_Warnung "Bit wird gesetzt, wenn Tür während der Fahrt geoeffnet werden soll.";
CM_ SG_ 975 HBFS_Tuerschloss_defekt "Das hintere Tuerschloss auf der Beifahrerseite ist nicht mehr funktionsfähig.";
CM_ SG_ 975 HBFS_UEKB_aktiviert "Überschutzbegrenzungskraft bei Reversieren";
CM_ SG_ 975 HBFS_Unlock_Taster "Betaetigung Unlock Taster";
CM_ SG_ 975 HBFS_Unten_Block_erw "Fensterheber in Blockerwartung unten";
CM_ SG_ 975 HBFS_verriegelt "Verriegelungsstatus Tür";
CM_ SG_ 975 HBFS_Zuziehhilfe_aktiv "Fehlende Beschreibung (Import)";
CM_ SG_ 975 MTHBFS_M_Taste "Betätigung M-Taste HBFS";
CM_ SG_ 975 MTHBFS_Pos1 "Betätigung Postionstaste 1 HBFS";
CM_ SG_ 975 MTHBFS_Pos2 "Betätigung Postionstaste 2 HBFS
";
CM_ SG_ 975 MTHBFS_Pos3 "Betätigung Postionstaste 3 HBFS";
CM_ SG_ 975 SSR_HBFS_Pos_Unten "Signal für die 'Global Close'. Über dieses Bit wissen die anderen TSGs, ob der SSR oder der FH verfahren werden darf.";

CM_ SG_ 1457 TSG_FlHz_HBFS_FnAbbruchHzKreis_A "Flächenheizung: Status";
CM_ SG_ 1457 TSG_FlHz_HBFS_FnAbbruchHzKreis_B "Flächenheizung: Status";
CM_ SG_ 1457 TSG_FlHz_HBFS_NTC_A "Flächenheizung: Temperatur und Fehlerwert des Heizaktors";
CM_ SG_ 1457 TSG_FlHz_HBFS_NTC_B "Flächenheizung: Temperatur und Fehlerwert des Heizaktors";

CM_ SG_ 974 ASW_Warnung_aktiv_HFS "Abschaltung der Ambientefunktion Tür hinten der Fahrerseite bei aktiver ASW Warnung an der Fahrertür";
CM_ SG_ 974 HFS_FH_Bew_hoch "HFS Fenster bewegt sich in Richtung hoch";
CM_ SG_ 974 HFS_FH_Bew_tief "HFS Fenster bewegt sich in Richtung tief";
CM_ SG_ 974 HFS_FH_Block "Fensterscheibe befindet sich im mechanischen Block (oben oder unten)";
CM_ SG_ 974 HFS_FH_Fang "Fangbereich ist 4mm von oberer Lippendichtung";
CM_ SG_ 974 HFS_FH_Oeffnung "Gibt den Fensteröffnungswert in % an.";
CM_ SG_ 974 HFS_FH_S_AutoHoch "Betaetigung FH Schalter auto hoch";
CM_ SG_ 974 HFS_FH_S_AutoTief "Betaetigung FH Schalter auto tief ";
CM_ SG_ 974 HFS_FH_S_HBFS_AutoHoch "Automatisches Hochfahren der Seitenscheibe HBFS";
CM_ SG_ 974 HFS_FH_S_HBFS_AutoTief "Automatisches Absenken der Seitenscheibe HBFS";
CM_ SG_ 974 HFS_FH_S_HBFS_ManHoch "Manuelles Hochfahren der Seitenscheibe HBFS";
CM_ SG_ 974 HFS_FH_S_HBFS_ManTief "Manuelles Absenken der Seitenscheibe HBFS";
CM_ SG_ 974 HFS_FH_S_ManHoch "Betaetigung FH Schalter man hoch ";
CM_ SG_ 974 HFS_FH_S_ManTief "Betaetigung FH Schalter man tief";
CM_ SG_ 974 HFS_FH_Thermo "gibt an ob Fensterheber im Thermoschutz ist";
CM_ SG_ 974 HFS_gesafet "HFS Tuer gesafet.
Im Zustand Safe wird auch das Signal HFS_verriegelt = 1 gesendet.";
CM_ SG_ 974 HFS_Heckrollotaster_betaetigt "Verfahren des Heckrollos in Richtung Hoch

Bei Einfachtaster wird Bit als Togglebit verwendet (Heckrollo hoch, tief)";
CM_ SG_ 974 HFS_Lock_Taster "Betätigung Lock-Taster";
CM_ SG_ 974 HFS_Lock_Taster_inv "Lock Taster nicht betätigt";
CM_ SG_ 974 HFS_MRollo_Schalter "  | MRollo2
-----------------------------
0 | nicht_betaetigt
1 | (m) Zu
2 | (a) Zu
3 | (m) Auf
4 | (a) Auf
5 | Schalter nicht verfuegbar
6 | Init
7 | Fehlerfall";
CM_ SG_ 974 HFS_Oben_Block_erw "Fensterheber in Blockerwartung oben";
CM_ SG_ 974 HFS_SAD_Schalter "  |   Ausstelldach MD3
-----------------------------
0 | nicht_betaetigt
1 |
2 |
3 |
4 |
5 | (m) Auf
6 | (a) Auf
7 | (m) Zu
8 | (a) Zu
13| Schalter nicht verfuegbar
14| Init
15| Fehlerfall";
CM_ SG_ 974 HFS_Sperrklinke "Vorraste für Schloß

zwischen Vor- und Hauptraste Signal kurz auf 1, danach wieder auf 0 wenn Tür in Hauptraste (Tür ist sicher zu wenn Sperrklinke und Türkontakt auf 0 sind)";
CM_ SG_ 974 HFS_Status_eTAG "Status des elektrischen Tueraussengriffes Tuer Fahrerseite hinten";
CM_ SG_ 974 HFS_Status_KiSi "Status Kindersicherung hinten Fahrerseite";
CM_ SG_ 974 HFS_TAG_betaetigt "Betaetigung Türaussengriff";
CM_ SG_ 974 HFS_TCR_Mode_aktiv "Signal zeigt eine aktive mechanische Redundanz am Türschloss an.";
CM_ SG_ 974 HFS_TIG_betaetigt "Betaetigung Türinnengriff";
CM_ SG_ 974 HFS_Tuer_geoeffnet "HFS Tuer geoeffnet";
CM_ SG_ 974 HFS_Tuer_Status "Türstatus mit Fehler und Initwert";
CM_ SG_ 974 HFS_Tuer_Status_QBit "Dieses Bit gibt die Zuverlässigkeit des Türkontakts an.";
CM_ SG_ 974 HFS_Tueroeffnen_Warnung "Bit wird gesetzt, wenn Tür während der Fahrt geoeffnet werden soll.";
CM_ SG_ 974 HFS_Tuerschloss_defekt "Das hintere Tuerschloss auf der Fahrerseite ist nicht mehr funktionsfähig.";
CM_ SG_ 974 HFS_UEKB_aktiviert "Überschutzbegrenzungskraft bei Reversieren";
CM_ SG_ 974 HFS_Unlock_Taster "Betaetigung Unlock Taster";
CM_ SG_ 974 HFS_Unten_Block_erw "Fensterheber in Blockerwartung unten";
CM_ SG_ 974 HFS_verriegelt "HFS Tuer verriegelt";
CM_ SG_ 974 HFS_Zuziehhilfe_aktiv "Fehlende Beschreibung (Import)";
CM_ SG_ 974 MTHFS_M_Taste "Betätigung M-Taste HFS";
CM_ SG_ 974 MTHFS_Pos1 "Betätigung Postionstaste 1 HFS";
CM_ SG_ 974 MTHFS_Pos2 "Betätigung Postionstaste 2 HFS
";
CM_ SG_ 974 MTHFS_Pos3 "Betätigung Postionstaste 3 HFS";
CM_ SG_ 974 SSR_HFS_Pos_Unten "Signal für die 'Global Close'. Über dieses Bit wissen die anderen TSGs, ob der SSR oder der FH verfahren werden darf.";

CM_ SG_ 1458 TSG_FlHz_HFS_FnAbbruchHzKreis_A "Flächenheizung: Status";
CM_ SG_ 1458 TSG_FlHz_HFS_FnAbbruchHzKreis_B "Flächenheizung: Status";
CM_ SG_ 1458 TSG_FlHz_HFS_NTC_A "Flächenheizung: Temperatur und Fehlerwert des Heizaktors";
CM_ SG_ 1458 TSG_FlHz_HFS_NTC_B "Flächenheizung: Temperatur und Fehlerwert des Heizaktors";

CM_ SG_ 346 MO_Anforderung_HMS "Halteanforderung vom Motor an HMS";
CM_ SG_ 346 TSK_08_CRC "Für MLB:
'Berechnung siehe Lastenheft 'Kommunikationsabsicherung für FlexRay und CAN''

Ab MQB und MLBevo:
'Berechnung siehe Lastenheft 'End-to-End Kommunikationsabsicherung''

Endwerte siehe Begleitdokument 'S-PDU Kennungsfolgen'";
CM_ SG_ 346 TSK_aktives_System "Anzeige der in der TSK-Längsführung aktiven Funktion";
CM_ SG_ 346 TSK_Anf_Antriebsmoment "Das Signal zeigt an, ob die TSK-Laengsregelung aktuell Antriebsmoment anfordert, zur Verwendung in der ASR/EDS-Funktion";
CM_ SG_ 346 TSK_Einheit_vMax_Fahrerassistenz "Einheit zu Signal TSK_vMax_Fahrerassistenz";
CM_ SG_ 346 TSK_erhoehter_Fahrwiderstand "Rueckmeldung vom Triebstrangkoordinator, dass eine große Reglerdifferenz detektiert wurde. Soll ermoeglichen, einen ggfs. unbekannten Fahrwiderstand am Boden zu erkennen.";
CM_ SG_ 346 TSK_Status_ARA "Funktionsstatus des Triebstrangkoordinators für den Anhängerrangierassistenten";
CM_ SG_ 346 TSK_Status_EA "Funktionsstatus des Triebstrangkoordinators für den Anforderer Emergency Assist";
CM_ SG_ 346 TSK_Status_IPA "Funktionsstatus des Triebstrangkoordinators für die Längsführung des Einparkassistenten";
CM_ SG_ 346 TSK_Status_PLA "Funktionsstatus des Triebstrangkoordinators für den Speedlimiter des Parkassistenten";
CM_ SG_ 346 TSK_vMax_aktuell "Im aktuellen Betriebszustand global gültige Geschwindigkeitslimitierung.";
CM_ SG_ 346 TSK_vMax_Fahrerassistenz "maximale Sollgeschwindigkeit für GRA/ACC/Limiter
Hinweis: Signal ist mit Signal TSK_Einheit_vMax_Fahrerassistenz zu interpretieren.  Das Signal wird abwechselnd in km/h und mph gesendet.";

CM_ SG_ 2589283609 UGDO_Channel_1 "Anlernstatus Kanal X für pilotiertes Parken.";
CM_ SG_ 2589283609 UGDO_Channel_10 "Anlernstatus Kanal X für pilotiertes Parken.";
CM_ SG_ 2589283609 UGDO_Channel_11 "Anlernstatus Kanal X für pilotiertes Parken.";
CM_ SG_ 2589283609 UGDO_Channel_12 "Anlernstatus Kanal X für pilotiertes Parken.";
CM_ SG_ 2589283609 UGDO_Channel_13 "Anlernstatus Kanal X für pilotiertes Parken.";
CM_ SG_ 2589283609 UGDO_Channel_14 "Anlernstatus Kanal X für pilotiertes Parken.";
CM_ SG_ 2589283609 UGDO_Channel_15 "Anlernstatus Kanal X für pilotiertes Parken.";
CM_ SG_ 2589283609 UGDO_Channel_2 "Anlernstatus Kanal X für pilotiertes Parken.";
CM_ SG_ 2589283609 UGDO_Channel_3 "Anlernstatus Kanal X für pilotiertes Parken.";
CM_ SG_ 2589283609 UGDO_Channel_4 "Anlernstatus Kanal X für pilotiertes Parken.";
CM_ SG_ 2589283609 UGDO_Channel_5 "Anlernstatus Kanal X für pilotiertes Parken.";
CM_ SG_ 2589283609 UGDO_Channel_6 "Anlernstatus Kanal X für pilotiertes Parken.";
CM_ SG_ 2589283609 UGDO_Channel_7 "Anlernstatus Kanal X für pilotiertes Parken.";
CM_ SG_ 2589283609 UGDO_Channel_8 "Anlernstatus Kanal X für pilotiertes Parken.";
CM_ SG_ 2589283609 UGDO_Channel_9 "Anlernstatus Kanal X für pilotiertes Parken.";
CM_ SG_ 2589283609 UGDO_DoorState "Ausgabe des Garagentorstatus für pilotiertes Parken.";
CM_ SG_ 2589283609 UGDO_Failure_Antenne "UGDO = LIN-Slave am BCM1.
UGDO-Sender meldet Fehlerstatus ans BCM1.";
CM_ SG_ 2589283609 UGDO_Failure_Codierung "UGDO = LIN-Slave am BCM1.
UGDO-Sender meldet Fehlerstatus ans BCM1.";
CM_ SG_ 2589283609 UGDO_Failure_Hardware "UGDO = LIN-Slave am BCM1.
UGDO-Sender meldet Fehlerstatus ans BCM1.";
CM_ SG_ 2589283609 UGDO_Function_01 "UGDO_Sender = LIN-Slave BCM1
bei Kl.15 AUS wird für 4s noch der letzte Wert gesendet, danach wird der Wert 7 (= Fehler gesendet)";
CM_ SG_ 2589283609 UGDO_LED_Code_01 "UGDO_Sender = LIN-Slave BCM1
Signal wird bei Kl.15 AUS mit dem letzten empfangenen Wert gesendet";
CM_ SG_ 2589283609 UGDO_ResponseError "siehe LIN2.0-Specification
(Darf nicht über ein Fehlergueltigkeitsbit abgesichtert werden!)";

CM_ SG_ 1718 UH_Minute "0x3C- 0x3f = Werte ungültig";
CM_ SG_ 1718 UH_Monat "0x0D, 0xF =  Werte ungültig
0x0E = Relatives Datum (nur VW)";
CM_ SG_ 1718 UH_Sekunde "0x3C- 0x3f = Werte ungültig";
CM_ SG_ 1718 UH_Stunde "0x18 - 0x1F = Werte ungültig";
CM_ SG_ 1718 UH_Tag "0x0: reserviert bei VW";
CM_ SG_ 1718 UH_Typ "0x4 - 0x7 = tbd. ";
BA_DEF_REL_ BU_SG_REL_  "GenSigTimeoutTime" INT 0 65535;
BA_DEF_ BO_  "DiagRequest" ENUM "No", "Yes";
BA_DEF_ BO_  "DiagResponse" ENUM "No", "Yes";
BA_DEF_ BO_  "DiagState" ENUM "No", "Yes";
BA_DEF_ BO_  "GenMsgChkConstant" HEX 0 4095;
BA_DEF_ BO_  "GenMsgCycleTime" INT 0 65535;
BA_DEF_ BO_  "GenMsgCycleTimeFast" INT 0 65535;
BA_DEF_ BO_  "GenMsgDelayTime" INT 0 100000;
BA_DEF_ BO_  "GenMsgILSupport" ENUM "No", "Yes";
BA_DEF_ BO_  "GenMsgNrOfRepetition" INT 0 100;
BA_DEF_ BO_  "GenMsgPDUConstants" STRING;
BA_DEF_ BO_  "GenMsgSendType" ENUM "Cyclic", "not_used", "not_used", "not_used", "not_used", "not_used", "not_used", "IfActive", "NoMsgSendType";
BA_DEF_ BO_  "GenMsgStartDelayTime" INT 0 100000;
BA_DEF_ BO_  "NmMessage" ENUM "No", "Yes";
BA_DEF_ BO_  "NmhMessage" ENUM "No", "Yes";
BA_DEF_ BO_  "MsgType" ENUM "Application", "NM ", "NMH", "TP2.0", "ISO-TP ", "BAP", "EID", "KS", "XCP_PRE_CONFIGURED", "XCP_RUNTIME_CONFIGURED";
BA_DEF_ BO_  "VAGTP20_API" HEX 0 255;
BA_DEF_ BO_  "VAGTP20_DynConnection" ENUM "No", "Yes";
BA_DEF_ BO_  "VAGTP20_DynSetup" ENUM "No", "Yes";
BA_DEF_ BO_  "VAGTP20_StatConnection" ENUM "No", "Yes";
BA_DEF_ SG_  "GenSigActiveRepetitions" INT -2147483648 2147483647;
BA_DEF_ SG_  "GenSigInactiveValue" INT -2147483648 2147483647;
BA_DEF_ SG_  "GenSigSendType" ENUM "Cyclic", "OnWrite", "OnWriteWithRepetition", "OnChange", "OnChangeWithRepetition", "IfActive", "IfActiveWithRepetition", "NoSigSendType", "OnChangeAndIfActive", "OnChangeAndIfActiveWithRepetition";
BA_DEF_ SG_  "GenSigStartValue" INT -2147483648 2147483647;
BA_DEF_ SG_  "NWM-WakeupAllowed" ENUM "No", "Yes";
BA_DEF_ SG_  "GenSigFuncType" ENUM "NoFunction", "MsgCounter", "CRC-8", "XOR", "XOR-2", "DatedBit", "SW-Kl15", "CHK", "Constant", "Protocol", "CRC-8-SAE_J1850", "CRC-32", "DataLength", "DataID", "MsgCounter16", "SOK-Signatur", "Cluster";
BA_DEF_ SG_  "GenSigSwitchedByIgnition" ENUM "No", "Yes";
BA_DEF_ SG_  "Fehlerwert" HEX 0 2147483647;
BA_DEF_ SG_  "GenSigMissingSourceValue" HEX 0 2147483647;
BA_DEF_DEF_REL_  "GenSigTimeoutTime" 0;
BA_DEF_DEF_  "DiagRequest" "No";
BA_DEF_DEF_  "DiagResponse" "No";
BA_DEF_DEF_  "DiagState" "No";
BA_DEF_DEF_  "GenMsgChkConstant" 0;
BA_DEF_DEF_  "GenMsgCycleTime" 0;
BA_DEF_DEF_  "GenMsgCycleTimeFast" 0;
BA_DEF_DEF_  "GenMsgDelayTime" 0;
BA_DEF_DEF_  "GenMsgILSupport" "No";
BA_DEF_DEF_  "GenMsgNrOfRepetition" 0;
BA_DEF_DEF_  "GenMsgPDUConstants" "";
BA_DEF_DEF_  "GenMsgSendType" "NoMsgSendType";
BA_DEF_DEF_  "GenMsgStartDelayTime" 0;
BA_DEF_DEF_  "NmMessage" "No";
BA_DEF_DEF_  "NmhMessage" "No";
BA_DEF_DEF_  "MsgType" "Application";
BA_DEF_DEF_  "VAGTP20_API" 0;
BA_DEF_DEF_  "VAGTP20_DynConnection" "No";
BA_DEF_DEF_  "VAGTP20_DynSetup" "No";
BA_DEF_DEF_  "VAGTP20_StatConnection" "No";
BA_DEF_DEF_  "GenSigActiveRepetitions" 0;
BA_DEF_DEF_  "GenSigInactiveValue" 0;
BA_DEF_DEF_  "GenSigSendType" "NoSigSendType";
BA_DEF_DEF_  "GenSigStartValue" 0;
BA_DEF_DEF_  "NWM-WakeupAllowed" "No";
BA_DEF_DEF_  "GenSigFuncType" "NoFunction";
BA_DEF_DEF_  "GenSigSwitchedByIgnition" "Yes";
BA_DEF_DEF_  "Fehlerwert" 0;
BA_DEF_DEF_  "GenSigMissingSourceValue" 0;
BA_ "GenMsgCycleTime" BO_ 1650 500;
BA_ "GenMsgDelayTime" BO_ 1650 50;
BA_ "GenMsgILSupport" BO_ 1650 1;
BA_ "GenMsgSendType" BO_ 1650 0;
BA_ "GenMsgCycleTime" BO_ 516 1000;
BA_ "GenMsgDelayTime" BO_ 516 20;
BA_ "GenMsgILSupport" BO_ 516 1;
BA_ "GenMsgPDUConstants" BO_ 516 "0x69,0xdc,0xf9,0x64,0x6a,0xce,0x55,0x2c,0xc4,0x38,0x8f,0xd1,0xc6,0x43,0xb4,0xb1";
BA_ "GenMsgSendType" BO_ 516 0;
BA_ "GenMsgCycleTime" BO_ 666 400;
BA_ "GenMsgDelayTime" BO_ 666 40;
BA_ "GenMsgILSupport" BO_ 666 1;
BA_ "GenMsgSendType" BO_ 666 0;
BA_ "GenMsgChkConstant" BO_ 1172 144;
BA_ "GenMsgCycleTime" BO_ 1172 200;
BA_ "GenMsgDelayTime" BO_ 1172 20;
BA_ "GenMsgILSupport" BO_ 1172 1;
BA_ "GenMsgPDUConstants" BO_ 1172 "0x90,0x90,0x90,0x90,0x90,0x90,0x90,0x90,0x90,0x90,0x90,0x90,0x90,0x90,0x90,0x90";
BA_ "GenMsgSendType" BO_ 1172 0;
BA_ "GenMsgChkConstant" BO_ 783 12;
BA_ "GenMsgCycleTime" BO_ 783 200;
BA_ "GenMsgDelayTime" BO_ 783 50;
BA_ "GenMsgILSupport" BO_ 783 1;
BA_ "GenMsgPDUConstants" BO_ 783 "0x0c,0x0c,0x0c,0x0c,0x0c,0x0c,0x0c,0x0c,0x0c,0x0c,0x0c,0x0c,0x0c,0x0c,0x0c,0x0c";
BA_ "GenMsgSendType" BO_ 783 0;
BA_ "GenMsgStartDelayTime" BO_ 783 45;
BA_ "GenMsgCycleTime" BO_ 1413 1000;
BA_ "GenMsgILSupport" BO_ 1413 1;
BA_ "GenMsgSendType" BO_ 1413 0;
BA_ "GenMsgStartDelayTime" BO_ 1413 85;
BA_ "GenMsgCycleTime" BO_ 2589283622 1000;
BA_ "GenMsgDelayTime" BO_ 2589283622 200;
BA_ "GenMsgILSupport" BO_ 2589283622 1;
BA_ "GenMsgSendType" BO_ 2589283622 0;
BA_ "GenMsgCycleTime" BO_ 2589283623 1000;
BA_ "GenMsgDelayTime" BO_ 2589283623 200;
BA_ "GenMsgILSupport" BO_ 2589283623 1;
BA_ "GenMsgSendType" BO_ 2589283623 0;
BA_ "GenMsgCycleTime" BO_ 1447 1000;
BA_ "GenMsgCycleTimeFast" BO_ 1447 100;
BA_ "GenMsgILSupport" BO_ 1447 1;
BA_ "GenMsgSendType" BO_ 1447 0;
BA_ "GenMsgStartDelayTime" BO_ 1447 95;
BA_ "GenMsgCycleTime" BO_ 977 500;
BA_ "GenMsgDelayTime" BO_ 977 100;
BA_ "GenMsgILSupport" BO_ 977 1;
BA_ "GenMsgSendType" BO_ 977 0;
BA_ "GenMsgStartDelayTime" BO_ 977 90;
BA_ "GenMsgCycleTime" BO_ 1451 1000;
BA_ "GenMsgDelayTime" BO_ 1451 100;
BA_ "GenMsgILSupport" BO_ 1451 1;
BA_ "GenMsgSendType" BO_ 1451 0;
BA_ "GenMsgCycleTime" BO_ 976 100;
BA_ "GenMsgDelayTime" BO_ 976 20;
BA_ "GenMsgILSupport" BO_ 976 1;
BA_ "GenMsgSendType" BO_ 976 0;
BA_ "GenMsgCycleTime" BO_ 997 100;
BA_ "GenMsgDelayTime" BO_ 997 20;
BA_ "GenMsgILSupport" BO_ 997 1;
BA_ "GenMsgPDUConstants" BO_ 997 "0xc4,0x6a,0x69,0x30,0xcf,0x61,0x58,0x51,0x1b,0x86,0x99,0xd3,0xf6,0x1d,0x9a,0x37";
BA_ "GenMsgSendType" BO_ 997 0;
BA_ "GenMsgCycleTime" BO_ 1449 1000;
BA_ "GenMsgDelayTime" BO_ 1449 100;
BA_ "GenMsgILSupport" BO_ 1449 1;
BA_ "GenMsgSendType" BO_ 1449 0;
BA_ "GenMsgCycleTime" BO_ 975 500;
BA_ "GenMsgDelayTime" BO_ 975 100;
BA_ "GenMsgILSupport" BO_ 975 1;
BA_ "GenMsgSendType" BO_ 975 0;
BA_ "GenMsgStartDelayTime" BO_ 975 90;
BA_ "GenMsgCycleTime" BO_ 1457 1000;
BA_ "GenMsgDelayTime" BO_ 1457 100;
BA_ "GenMsgILSupport" BO_ 1457 1;
BA_ "GenMsgSendType" BO_ 1457 0;
BA_ "GenMsgCycleTime" BO_ 974 500;
BA_ "GenMsgDelayTime" BO_ 974 100;
BA_ "GenMsgILSupport" BO_ 974 1;
BA_ "GenMsgSendType" BO_ 974 0;
BA_ "GenMsgStartDelayTime" BO_ 974 90;
BA_ "GenMsgCycleTime" BO_ 1458 1000;
BA_ "GenMsgDelayTime" BO_ 1458 100;
BA_ "GenMsgILSupport" BO_ 1458 1;
BA_ "GenMsgSendType" BO_ 1458 0;
BA_ "GenMsgCycleTime" BO_ 346 100;
BA_ "GenMsgDelayTime" BO_ 346 20;
BA_ "GenMsgILSupport" BO_ 346 1;
BA_ "GenMsgPDUConstants" BO_ 346 "0xcf,0x1a,0x84,0x28,0x05,0xcb,0xb3,0x98,0x82,0x53,0xbe,0xa1,0x4a,0x6d,0x41,0xae";
BA_ "GenMsgSendType" BO_ 346 0;
BA_ "GenMsgCycleTime" BO_ 2589283609 500;
BA_ "GenMsgDelayTime" BO_ 2589283609 80;
BA_ "GenMsgILSupport" BO_ 2589283609 1;
BA_ "GenMsgSendType" BO_ 2589283609 0;
BA_ "GenMsgCycleTime" BO_ 1718 1000;
BA_ "GenMsgILSupport" BO_ 1718 1;
BA_ "GenMsgSendType" BO_ 1718 0;
BA_ "GenSigSendType" SG_ 1650 STH_ZZ_Betriebsdauer 3;
BA_ "GenSigSwitchedByIgnition" SG_ 1650 STH_ZZ_Betriebsdauer 0;
BA_ "GenSigSendType" SG_ 1650 STH_ZZ_Betriebsmodus 3;
BA_ "GenSigSwitchedByIgnition" SG_ 1650 STH_ZZ_Betriebsmodus 0;
BA_ "GenSigSendType" SG_ 1650 STH_ZZ_Minute 3;
BA_ "GenSigSwitchedByIgnition" SG_ 1650 STH_ZZ_Minute 0;
BA_ "GenSigSendType" SG_ 1650 STH_ZZ_Monat 3;
BA_ "GenSigSwitchedByIgnition" SG_ 1650 STH_ZZ_Monat 0;
BA_ "GenSigSendType" SG_ 1650 STH_ZZ_Status_Timer 3;
BA_ "GenSigSwitchedByIgnition" SG_ 1650 STH_ZZ_Status_Timer 0;
BA_ "GenSigSendType" SG_ 1650 STH_ZZ_Stunde 3;
BA_ "GenSigSwitchedByIgnition" SG_ 1650 STH_ZZ_Stunde 0;
BA_ "GenSigSendType" SG_ 1650 STH_ZZ_Tag 3;
BA_ "GenSigSwitchedByIgnition" SG_ 1650 STH_ZZ_Tag 0;
BA_ "GenSigSendType" SG_ 516 ACA_HF_LRR_Abschaltbedingung 0;
BA_ "GenSigStartValue" SG_ 516 ACA_HF_LRR_Abschaltbedingung 7;
BA_ "GenSigSendType" SG_ 516 ACA_HF_LRR_Aktivierverhinderung 0;
BA_ "GenSigStartValue" SG_ 516 ACA_HF_LRR_Aktivierverhinderung 1;
BA_ "GenSigSendType" SG_ 516 ACA_HF_LRR_Status 0;
BA_ "GenSigSendType" SG_ 516 ACC_Pilot_Verz_Anf 0;
BA_ "GenSigStartValue" SG_ 516 ACC_Pilot_Verz_Anf 1023;
BA_ "GenSigSendType" SG_ 516 STP_01_BZ 0;
BA_ "GenSigFuncType" SG_ 516 STP_01_BZ 1;
BA_ "GenSigSendType" SG_ 516 STP_01_CRC 0;
BA_ "GenSigFuncType" SG_ 516 STP_01_CRC 2;
BA_ "GenSigSendType" SG_ 516 STP_Abschaltbedingung 3;
BA_ "GenSigStartValue" SG_ 516 STP_Abschaltbedingung 1;
BA_ "GenSigSendType" SG_ 516 STP_Aktivierverhinderung 3;
BA_ "GenSigSendType" SG_ 516 STP_DAF_Code 0;
BA_ "GenSigSendType" SG_ 516 STP_Freiraum 3;
BA_ "GenSigSendType" SG_ 516 STP_Status 3;
BA_ "GenSigSendType" SG_ 666 STP_Abstand_Zielobjekt 3;
BA_ "GenSigSendType" SG_ 666 STP_Egokolonne_ZA 3;
BA_ "GenSigSendType" SG_ 666 STP_FAS_Fkt_Status 3;
BA_ "Fehlerwert" SG_ 666 STP_FAS_Fkt_Status 3;
BA_ "GenSigSendType" SG_ 666 STP_FBM_links_ZA 3;
BA_ "GenSigSendType" SG_ 666 STP_FBM_rechts_ZA 3;
BA_ "GenSigSendType" SG_ 666 STP_Geschw_Egofahrzeug_ZA 3;
BA_ "GenSigSendType" SG_ 666 STP_Nebenspur_Geschw_links_ZA 3;
BA_ "GenSigStartValue" SG_ 666 STP_Nebenspur_Geschw_links_ZA 255;
BA_ "GenSigSendType" SG_ 666 STP_Nebenspur_Geschw_rechts_ZA 3;
BA_ "GenSigStartValue" SG_ 666 STP_Nebenspur_Geschw_rechts_ZA 255;
BA_ "GenSigSendType" SG_ 666 STP_Nebenspur_links_ZA 3;
BA_ "GenSigSendType" SG_ 666 STP_Nebenspur_rechts_ZA 3;
BA_ "GenSigSendType" SG_ 666 STP_Primaeranz_02 3;
BA_ "GenSigSendType" SG_ 666 STP_Status_Anzeige 3;
BA_ "GenSigSendType" SG_ 666 STP_Texte 3;
BA_ "GenSigSendType" SG_ 666 STP_Texte_AV 3;
BA_ "GenSigSendType" SG_ 666 STP_Texte_ESK 3;
BA_ "GenSigSendType" SG_ 666 STP_Texte_ZA 3;
BA_ "GenSigSendType" SG_ 1172 GW_STS2_Privatsphaere 0;
BA_ "GenSigSwitchedByIgnition" SG_ 1172 GW_STS2_Privatsphaere 0;
BA_ "GenSigSendType" SG_ 1172 STS_01_BZ 0;
BA_ "GenSigFuncType" SG_ 1172 STS_01_BZ 1;
BA_ "GenSigSwitchedByIgnition" SG_ 1172 STS_01_BZ 0;
BA_ "GenSigSendType" SG_ 1172 STS_01_CRC 0;
BA_ "GenSigFuncType" SG_ 1172 STS_01_CRC 2;
BA_ "GenSigSwitchedByIgnition" SG_ 1172 STS_01_CRC 0;
BA_ "GenSigSendType" SG_ 1172 STS_Alarm_Blinker 3;
BA_ "GenSigSwitchedByIgnition" SG_ 1172 STS_Alarm_Blinker 0;
BA_ "GenSigSendType" SG_ 1172 STS_Alarm_still 0;
BA_ "GenSigSwitchedByIgnition" SG_ 1172 STS_Alarm_still 0;
BA_ "GenSigSendType" SG_ 1172 STS_Anlassersperre 0;
BA_ "GenSigSwitchedByIgnition" SG_ 1172 STS_Anlassersperre 0;
BA_ "GenSigSendType" SG_ 1172 STS_Car_not_under_theft 0;
BA_ "GenSigStartValue" SG_ 1172 STS_Car_not_under_theft 1;
BA_ "GenSigSwitchedByIgnition" SG_ 1172 STS_Car_not_under_theft 0;
BA_ "GenSigSendType" SG_ 1172 STS_Car_under_theft 0;
BA_ "GenSigSwitchedByIgnition" SG_ 1172 STS_Car_under_theft 0;
BA_ "GenSigSendType" SG_ 1172 STS_Door_Lock 3;
BA_ "GenSigSwitchedByIgnition" SG_ 1172 STS_Door_Lock 0;
BA_ "GenSigSendType" SG_ 1172 STS_Fahrlicht 3;
BA_ "GenSigSwitchedByIgnition" SG_ 1172 STS_Fahrlicht 0;
BA_ "GenSigSendType" SG_ 1172 STS_Laderelais 3;
BA_ "GenSigSwitchedByIgnition" SG_ 1172 STS_Laderelais 0;
BA_ "GenSigSendType" SG_ 1172 STS_Leerlaufschaltung 0;
BA_ "GenSigSwitchedByIgnition" SG_ 1172 STS_Leerlaufschaltung 0;
BA_ "GenSigSendType" SG_ 1172 STS_LIN_aktiv 0;
BA_ "GenSigSwitchedByIgnition" SG_ 1172 STS_LIN_aktiv 0;
BA_ "GenSigSendType" SG_ 1172 STS_Notstart 3;
BA_ "GenSigSwitchedByIgnition" SG_ 1172 STS_Notstart 0;
BA_ "GenSigSendType" SG_ 1172 STS_Signalhorn 3;
BA_ "GenSigSwitchedByIgnition" SG_ 1172 STS_Signalhorn 0;
BA_ "GenSigSendType" SG_ 1172 STS_Spiegel_Anklappen 3;
BA_ "GenSigSwitchedByIgnition" SG_ 1172 STS_Spiegel_Anklappen 0;
BA_ "GenSigSendType" SG_ 1172 STS_Standlicht 3;
BA_ "GenSigSwitchedByIgnition" SG_ 1172 STS_Standlicht 0;
BA_ "GenSigSendType" SG_ 1172 STS_Summer 3;
BA_ "GenSigSwitchedByIgnition" SG_ 1172 STS_Summer 0;
BA_ "GenSigSendType" SG_ 1172 STS_Texte 0;
BA_ "GenSigStartValue" SG_ 1172 STS_Texte 14;
BA_ "GenSigSwitchedByIgnition" SG_ 1172 STS_Texte 0;
BA_ "Fehlerwert" SG_ 1172 STS_Texte 15;
BA_ "GenSigSendType" SG_ 1172 STS_Typencodierung 0;
BA_ "GenSigSwitchedByIgnition" SG_ 1172 STS_Typencodierung 0;
BA_ "GenSigSendType" SG_ 783 ASW_Kombitexte 3;
BA_ "GenSigSwitchedByIgnition" SG_ 783 ASW_Kombitexte 0;
BA_ "GenSigSendType" SG_ 783 ASW_Modus 0;
BA_ "GenSigStartValue" SG_ 783 ASW_Modus 4;
BA_ "GenSigSendType" SG_ 783 ASW_Status 3;
BA_ "GenSigSwitchedByIgnition" SG_ 783 ASW_Status 0;
BA_ "Fehlerwert" SG_ 783 ASW_Status 2;
BA_ "GenSigSendType" SG_ 783 ASW_Warnung_BFS 3;
BA_ "GenSigSwitchedByIgnition" SG_ 783 ASW_Warnung_BFS 0;
BA_ "GenSigSendType" SG_ 783 ASW_Warnung_FS 3;
BA_ "GenSigSwitchedByIgnition" SG_ 783 ASW_Warnung_FS 0;
BA_ "GenSigSendType" SG_ 783 Heckradar_Kombitexte 3;
BA_ "GenSigSwitchedByIgnition" SG_ 783 Heckradar_Kombitexte 0;
BA_ "GenSigSendType" SG_ 783 HRE_Anzeigetexte 0;
BA_ "GenSigSwitchedByIgnition" SG_ 783 HRE_Anzeigetexte 0;
BA_ "GenSigSendType" SG_ 783 RCTA_Kombitexte 3;
BA_ "GenSigSwitchedByIgnition" SG_ 783 RCTA_Kombitexte 0;
BA_ "GenSigSendType" SG_ 783 SWA_01_BZ 0;
BA_ "GenSigFuncType" SG_ 783 SWA_01_BZ 1;
BA_ "GenSigSwitchedByIgnition" SG_ 783 SWA_01_BZ 0;
BA_ "GenSigSendType" SG_ 783 SWA_01_CRC 0;
BA_ "GenSigFuncType" SG_ 783 SWA_01_CRC 2;
BA_ "GenSigSwitchedByIgnition" SG_ 783 SWA_01_CRC 0;
BA_ "GenSigSendType" SG_ 783 SWA_Anzeigen 3;
BA_ "GenSigSwitchedByIgnition" SG_ 783 SWA_Anzeigen 0;
BA_ "GenSigSendType" SG_ 783 SWA_Blindheit_erkannt 0;
BA_ "GenSigSendType" SG_ 783 SWA_FT_RueckLED 3;
BA_ "GenSigSwitchedByIgnition" SG_ 783 SWA_FT_RueckLED 0;
BA_ "GenSigSendType" SG_ 783 SWA_Infostufe_SWA_li 0;
BA_ "GenSigSendType" SG_ 783 SWA_Infostufe_SWA_re 0;
BA_ "GenSigSendType" SG_ 783 SWA_Kolonne_li 0;
BA_ "GenSigSendType" SG_ 783 SWA_Kolonne_mi 0;
BA_ "GenSigSendType" SG_ 783 SWA_Kolonne_re 0;
BA_ "GenSigSendType" SG_ 783 SWA_Modus 0;
BA_ "GenSigSendType" SG_ 783 SWA_rel_Fehler 0;
BA_ "Fehlerwert" SG_ 783 SWA_rel_Fehler 1;
BA_ "GenSigSendType" SG_ 783 SWA_rel_Nichtverf 0;
BA_ "GenSigSendType" SG_ 783 SWA_Sta_aktiv 0;
BA_ "GenSigSendType" SG_ 783 SWA_Sta_passiv 0;
BA_ "GenSigSendType" SG_ 783 SWA_Standziele_li 0;
BA_ "GenSigSendType" SG_ 783 SWA_Standziele_re 0;
BA_ "GenSigSendType" SG_ 783 SWA_Status_02 0;
BA_ "Fehlerwert" SG_ 783 SWA_Status_02 3;
BA_ "GenSigSendType" SG_ 783 SWA_Warnung_SWA_li 0;
BA_ "GenSigSendType" SG_ 783 SWA_Warnung_SWA_re 0;
BA_ "GenSigSendType" SG_ 1413 GW_KD_Fehler 3;
BA_ "GenSigSendType" SG_ 1413 SI_BUS_01 3;
BA_ "GenSigStartValue" SG_ 1413 SI_BUS_01 1;
BA_ "GenSigSwitchedByIgnition" SG_ 1413 SI_BUS_01 0;
BA_ "GenSigSendType" SG_ 1413 SI_BUS_02 3;
BA_ "GenSigStartValue" SG_ 1413 SI_BUS_02 1;
BA_ "GenSigSwitchedByIgnition" SG_ 1413 SI_BUS_02 0;
BA_ "GenSigSendType" SG_ 1413 SI_BUS_03 3;
BA_ "GenSigStartValue" SG_ 1413 SI_BUS_03 1;
BA_ "GenSigSwitchedByIgnition" SG_ 1413 SI_BUS_03 0;
BA_ "GenSigSendType" SG_ 1413 SI_BUS_04 3;
BA_ "GenSigStartValue" SG_ 1413 SI_BUS_04 1;
BA_ "GenSigSwitchedByIgnition" SG_ 1413 SI_BUS_04 0;
BA_ "GenSigSendType" SG_ 1413 SI_BUS_05 3;
BA_ "GenSigStartValue" SG_ 1413 SI_BUS_05 1;
BA_ "GenSigSwitchedByIgnition" SG_ 1413 SI_BUS_05 0;
BA_ "GenSigSendType" SG_ 1413 SI_BUS_06 3;
BA_ "GenSigStartValue" SG_ 1413 SI_BUS_06 1;
BA_ "GenSigSwitchedByIgnition" SG_ 1413 SI_BUS_06 0;
BA_ "GenSigSendType" SG_ 1413 SI_BUS_07 3;
BA_ "GenSigStartValue" SG_ 1413 SI_BUS_07 1;
BA_ "GenSigSwitchedByIgnition" SG_ 1413 SI_BUS_07 0;
BA_ "GenSigSendType" SG_ 1413 SI_BUS_08 3;
BA_ "GenSigStartValue" SG_ 1413 SI_BUS_08 1;
BA_ "GenSigSwitchedByIgnition" SG_ 1413 SI_BUS_08 0;
BA_ "GenSigSendType" SG_ 1413 SI_BUS_09 3;
BA_ "GenSigStartValue" SG_ 1413 SI_BUS_09 1;
BA_ "GenSigSwitchedByIgnition" SG_ 1413 SI_BUS_09 0;
BA_ "GenSigSendType" SG_ 1413 SI_BUS_10 3;
BA_ "GenSigStartValue" SG_ 1413 SI_BUS_10 1;
BA_ "GenSigSwitchedByIgnition" SG_ 1413 SI_BUS_10 0;
BA_ "GenSigSendType" SG_ 1413 SI_BUS_11 3;
BA_ "GenSigStartValue" SG_ 1413 SI_BUS_11 1;
BA_ "GenSigSwitchedByIgnition" SG_ 1413 SI_BUS_11 0;
BA_ "GenSigSendType" SG_ 1413 SI_BUS_12 3;
BA_ "GenSigStartValue" SG_ 1413 SI_BUS_12 1;
BA_ "GenSigSwitchedByIgnition" SG_ 1413 SI_BUS_12 0;
BA_ "GenSigSendType" SG_ 1413 SI_BUS_13 3;
BA_ "GenSigStartValue" SG_ 1413 SI_BUS_13 1;
BA_ "GenSigSwitchedByIgnition" SG_ 1413 SI_BUS_13 0;
BA_ "GenSigSendType" SG_ 1413 SI_BUS_14 3;
BA_ "GenSigStartValue" SG_ 1413 SI_BUS_14 1;
BA_ "GenSigSwitchedByIgnition" SG_ 1413 SI_BUS_14 0;
BA_ "GenSigSendType" SG_ 1413 SI_BUS_15 3;
BA_ "GenSigStartValue" SG_ 1413 SI_BUS_15 1;
BA_ "GenSigSwitchedByIgnition" SG_ 1413 SI_BUS_15 0;
BA_ "GenSigSendType" SG_ 1413 SI_Bus_Identifikation 0;
BA_ "GenSigSwitchedByIgnition" SG_ 1413 SI_Bus_Identifikation 0;
BA_ "GenSigSendType" SG_ 1413 SI_CAB 3;
BA_ "GenSigFuncType" SG_ 1413 SI_CAB 16;
BA_ "GenSigSwitchedByIgnition" SG_ 1413 SI_CAB 0;
BA_ "GenSigSendType" SG_ 1413 SI_Diagnose_Aktiv 3;
BA_ "GenSigSwitchedByIgnition" SG_ 1413 SI_Diagnose_Aktiv 0;
BA_ "GenSigSendType" SG_ 1413 SI_NWDF 3;
BA_ "GenSigSwitchedByIgnition" SG_ 1413 SI_NWDF 0;
BA_ "GenSigSendType" SG_ 1413 SI_NWDF_gueltig 3;
BA_ "GenSigFuncType" SG_ 1413 SI_NWDF_gueltig 8;
BA_ "GenSigSwitchedByIgnition" SG_ 1413 SI_NWDF_gueltig 0;
BA_ "GenSigSendType" SG_ 1413 SI_QRS_Mode 3;
BA_ "GenSigSwitchedByIgnition" SG_ 1413 SI_QRS_Mode 0;
BA_ "GenSigSendType" SG_ 1413 SI_Sammel_SG_Fehler 0;
BA_ "GenSigStartValue" SG_ 1413 SI_Sammel_SG_Fehler 63;
BA_ "GenSigSwitchedByIgnition" SG_ 1413 SI_Sammel_SG_Fehler 0;
BA_ "GenSigSendType" SG_ 1413 SI_Sammelfehler 3;
BA_ "GenSigSwitchedByIgnition" SG_ 1413 SI_Sammelfehler 0;
BA_ "GenSigSendType" SG_ 1413 SI_T_Mode 3;
BA_ "GenSigSwitchedByIgnition" SG_ 1413 SI_T_Mode 0;
BA_ "GenSigSendType" SG_ 1413 SI_T_Schutz 3;
BA_ "GenSigSwitchedByIgnition" SG_ 1413 SI_T_Schutz 0;
BA_ "GenSigSendType" SG_ 2589283622 TLO_01_Zaehler 3;
BA_ "GenSigSwitchedByIgnition" SG_ 2589283622 TLO_01_Zaehler 0;
BA_ "GenSigSendType" SG_ 2589283622 TLO_HMI_Status 3;
BA_ "GenSigSwitchedByIgnition" SG_ 2589283622 TLO_HMI_Status 0;
BA_ "GenSigSendType" SG_ 2589283622 TLO_LSA1_PSD_Seg_Offset 3;
BA_ "GenSigStartValue" SG_ 2589283622 TLO_LSA1_PSD_Seg_Offset 255;
BA_ "GenSigSwitchedByIgnition" SG_ 2589283622 TLO_LSA1_PSD_Seg_Offset 0;
BA_ "GenSigSendType" SG_ 2589283622 TLO_LSA1_PSD_Segment_ID 3;
BA_ "GenSigSwitchedByIgnition" SG_ 2589283622 TLO_LSA1_PSD_Segment_ID 0;
BA_ "GenSigSendType" SG_ 2589283622 TLO_LSA1_Zeit1_CF 3;
BA_ "GenSigSwitchedByIgnition" SG_ 2589283622 TLO_LSA1_Zeit1_CF 0;
BA_ "GenSigSendType" SG_ 2589283622 TLO_LSA1_Zeit1_Pred 3;
BA_ "GenSigSwitchedByIgnition" SG_ 2589283622 TLO_LSA1_Zeit1_Pred 0;
BA_ "GenSigSendType" SG_ 2589283622 TLO_LSA1_Zeit1_Status 3;
BA_ "GenSigSwitchedByIgnition" SG_ 2589283622 TLO_LSA1_Zeit1_Status 0;
BA_ "GenSigSendType" SG_ 2589283622 TLO_LSA1_Zeit2_CF 3;
BA_ "GenSigSwitchedByIgnition" SG_ 2589283622 TLO_LSA1_Zeit2_CF 0;
BA_ "GenSigSendType" SG_ 2589283622 TLO_LSA1_Zeit2_Pred 3;
BA_ "GenSigSwitchedByIgnition" SG_ 2589283622 TLO_LSA1_Zeit2_Pred 0;
BA_ "GenSigSendType" SG_ 2589283622 TLO_LSA1_Zeit2_Status 3;
BA_ "GenSigSwitchedByIgnition" SG_ 2589283622 TLO_LSA1_Zeit2_Status 0;
BA_ "GenSigSendType" SG_ 2589283622 TLO_StartStoppInfo 3;
BA_ "GenSigSwitchedByIgnition" SG_ 2589283622 TLO_StartStoppInfo 0;
BA_ "GenSigSendType" SG_ 2589283623 TLO_02_Zaehler 3;
BA_ "GenSigSwitchedByIgnition" SG_ 2589283623 TLO_02_Zaehler 0;
BA_ "GenSigSendType" SG_ 2589283623 TLO_LSA1_Layout 3;
BA_ "GenSigSwitchedByIgnition" SG_ 2589283623 TLO_LSA1_Layout 0;
BA_ "GenSigSendType" SG_ 2589283623 TLO_LSA2_PSD_Seg_Offset 3;
BA_ "GenSigStartValue" SG_ 2589283623 TLO_LSA2_PSD_Seg_Offset 255;
BA_ "GenSigSwitchedByIgnition" SG_ 2589283623 TLO_LSA2_PSD_Seg_Offset 0;
BA_ "GenSigSendType" SG_ 2589283623 TLO_LSA2_PSD_Segment_ID 3;
BA_ "GenSigSwitchedByIgnition" SG_ 2589283623 TLO_LSA2_PSD_Segment_ID 0;
BA_ "GenSigSendType" SG_ 2589283623 TLO_LSA2_Zeit1_CF 3;
BA_ "GenSigSwitchedByIgnition" SG_ 2589283623 TLO_LSA2_Zeit1_CF 0;
BA_ "GenSigSendType" SG_ 2589283623 TLO_LSA2_Zeit1_Pred 3;
BA_ "GenSigSwitchedByIgnition" SG_ 2589283623 TLO_LSA2_Zeit1_Pred 0;
BA_ "GenSigSendType" SG_ 2589283623 TLO_LSA2_Zeit1_Status 3;
BA_ "GenSigSwitchedByIgnition" SG_ 2589283623 TLO_LSA2_Zeit1_Status 0;
BA_ "GenSigSendType" SG_ 2589283623 TLO_LSA2_Zeit2_CF 3;
BA_ "GenSigSwitchedByIgnition" SG_ 2589283623 TLO_LSA2_Zeit2_CF 0;
BA_ "GenSigSendType" SG_ 2589283623 TLO_LSA2_Zeit2_Pred 3;
BA_ "GenSigSwitchedByIgnition" SG_ 2589283623 TLO_LSA2_Zeit2_Pred 0;
BA_ "GenSigSendType" SG_ 2589283623 TLO_LSA2_Zeit2_Status 3;
BA_ "GenSigSwitchedByIgnition" SG_ 2589283623 TLO_LSA2_Zeit2_Status 0;
BA_ "GenSigSendType" SG_ 1447 TM_Door_Lock 5;
BA_ "GenSigSwitchedByIgnition" SG_ 1447 TM_Door_Lock 0;
BA_ "GenSigSendType" SG_ 1447 TM_Door_Unlock 5;
BA_ "GenSigSwitchedByIgnition" SG_ 1447 TM_Door_Unlock 0;
BA_ "GenSigSendType" SG_ 1447 TM_Nur_Hupen 5;
BA_ "GenSigSwitchedByIgnition" SG_ 1447 TM_Nur_Hupen 0;
BA_ "GenSigSendType" SG_ 1447 TM_Panik_Alarm 5;
BA_ "GenSigSwitchedByIgnition" SG_ 1447 TM_Panik_Alarm 0;
BA_ "GenSigSendType" SG_ 1447 TM_Spiegel_Anklappen 5;
BA_ "GenSigSwitchedByIgnition" SG_ 1447 TM_Spiegel_Anklappen 0;
BA_ "GenSigSendType" SG_ 1447 TM_Warnblinken 5;
BA_ "GenSigSwitchedByIgnition" SG_ 1447 TM_Warnblinken 0;
BA_ "GenSigSendType" SG_ 1447 TM_ZV_Signatur 0;
BA_ "GenSigSwitchedByIgnition" SG_ 1447 TM_ZV_Signatur 0;
BA_ "GenSigSendType" SG_ 977 ASW_Warnung_aktiv_BFS 0;
BA_ "GenSigSwitchedByIgnition" SG_ 977 ASW_Warnung_aktiv_BFS 0;
BA_ "GenSigSendType" SG_ 977 BFS_Status_eTAG 0;
BA_ "GenSigSwitchedByIgnition" SG_ 977 BFS_Status_eTAG 0;
BA_ "Fehlerwert" SG_ 977 BFS_Status_eTAG 3;
BA_ "GenSigSendType" SG_ 977 BT_ASW_HMI_defekt 0;
BA_ "GenSigSwitchedByIgnition" SG_ 977 BT_ASW_HMI_defekt 0;
BA_ "GenSigSendType" SG_ 977 BT_EC_Spiegel_Helligkeit 0;
BA_ "GenSigSwitchedByIgnition" SG_ 977 BT_EC_Spiegel_Helligkeit 0;
BA_ "GenSigSendType" SG_ 977 BT_FH_Bew_hoch 0;
BA_ "GenSigSwitchedByIgnition" SG_ 977 BT_FH_Bew_hoch 0;
BA_ "GenSigSendType" SG_ 977 BT_FH_Bew_tief 0;
BA_ "GenSigSwitchedByIgnition" SG_ 977 BT_FH_Bew_tief 0;
BA_ "GenSigSendType" SG_ 977 BT_FH_Block 0;
BA_ "GenSigSwitchedByIgnition" SG_ 977 BT_FH_Block 0;
BA_ "GenSigSendType" SG_ 977 BT_FH_Fang 0;
BA_ "GenSigSwitchedByIgnition" SG_ 977 BT_FH_Fang 0;
BA_ "GenSigSendType" SG_ 977 BT_FH_normiert 0;
BA_ "GenSigSwitchedByIgnition" SG_ 977 BT_FH_normiert 0;
BA_ "GenSigSendType" SG_ 977 BT_FH_Oeffnung 3;
BA_ "GenSigSwitchedByIgnition" SG_ 977 BT_FH_Oeffnung 0;
BA_ "GenSigSendType" SG_ 977 BT_FH_Pos_oben 0;
BA_ "GenSigSwitchedByIgnition" SG_ 977 BT_FH_Pos_oben 0;
BA_ "GenSigSendType" SG_ 977 BT_FH_S_AutoHoch 0;
BA_ "GenSigSwitchedByIgnition" SG_ 977 BT_FH_S_AutoHoch 0;
BA_ "GenSigSendType" SG_ 977 BT_FH_S_AutoTief 0;
BA_ "GenSigSwitchedByIgnition" SG_ 977 BT_FH_S_AutoTief 0;
BA_ "GenSigSendType" SG_ 977 BT_FH_S_ManHoch 0;
BA_ "GenSigSwitchedByIgnition" SG_ 977 BT_FH_S_ManHoch 0;
BA_ "GenSigSendType" SG_ 977 BT_FH_S_ManTief 0;
BA_ "GenSigSwitchedByIgnition" SG_ 977 BT_FH_S_ManTief 0;
BA_ "GenSigSendType" SG_ 977 BT_FH_Thermo 0;
BA_ "GenSigSwitchedByIgnition" SG_ 977 BT_FH_Thermo 0;
BA_ "GenSigSendType" SG_ 977 BT_gesafet 0;
BA_ "GenSigSwitchedByIgnition" SG_ 977 BT_gesafet 0;
BA_ "GenSigSendType" SG_ 977 BT_Kisi_Fehler 0;
BA_ "GenSigSwitchedByIgnition" SG_ 977 BT_Kisi_Fehler 0;
BA_ "Fehlerwert" SG_ 977 BT_Kisi_Fehler 1;
BA_ "GenSigSendType" SG_ 977 BT_Lock_Taster 0;
BA_ "GenSigSwitchedByIgnition" SG_ 977 BT_Lock_Taster 0;
BA_ "GenSigSendType" SG_ 977 BT_Lock_Taster_inv 0;
BA_ "GenSigSwitchedByIgnition" SG_ 977 BT_Lock_Taster_inv 0;
BA_ "GenSigSendType" SG_ 977 BT_Oben_Block_erw 0;
BA_ "GenSigSwitchedByIgnition" SG_ 977 BT_Oben_Block_erw 0;
BA_ "GenSigSendType" SG_ 977 BT_Schliesstaster 0;
BA_ "GenSigSwitchedByIgnition" SG_ 977 BT_Schliesstaster 0;
BA_ "GenSigSendType" SG_ 977 BT_Schluesselschalter_auf 0;
BA_ "GenSigSwitchedByIgnition" SG_ 977 BT_Schluesselschalter_auf 0;
BA_ "GenSigSendType" SG_ 977 BT_Schluesselschalter_zu 0;
BA_ "GenSigSwitchedByIgnition" SG_ 977 BT_Schluesselschalter_zu 0;
BA_ "GenSigSendType" SG_ 977 BT_Schluesselschalter_zu_inv 0;
BA_ "GenSigSwitchedByIgnition" SG_ 977 BT_Schluesselschalter_zu_inv 0;
BA_ "GenSigSendType" SG_ 977 BT_SP_ausgerastet 0;
BA_ "GenSigSwitchedByIgnition" SG_ 977 BT_SP_ausgerastet 0;
BA_ "GenSigSendType" SG_ 977 BT_Sp_Blk_def 0;
BA_ "GenSigSwitchedByIgnition" SG_ 977 BT_Sp_Blk_def 0;
BA_ "GenSigSendType" SG_ 977 BT_SP_Heizung_aktiv 0;
BA_ "GenSigSwitchedByIgnition" SG_ 977 BT_SP_Heizung_aktiv 0;
BA_ "GenSigSendType" SG_ 977 BT_Sp_Heizung_Anf 0;
BA_ "GenSigSwitchedByIgnition" SG_ 977 BT_Sp_Heizung_Anf 0;
BA_ "GenSigSendType" SG_ 977 BT_SP_Heizung_Status 0;
BA_ "GenSigSwitchedByIgnition" SG_ 977 BT_SP_Heizung_Status 0;
BA_ "GenSigSendType" SG_ 977 BT_SP_ht_aktiv 0;
BA_ "GenSigSwitchedByIgnition" SG_ 977 BT_SP_ht_aktiv 0;
BA_ "GenSigSendType" SG_ 977 BT_SP_lr_aktiv 0;
BA_ "GenSigSwitchedByIgnition" SG_ 977 BT_SP_lr_aktiv 0;
BA_ "GenSigSendType" SG_ 977 BT_Sperrklinke 0;
BA_ "GenSigSwitchedByIgnition" SG_ 977 BT_Sperrklinke 0;
BA_ "GenSigSendType" SG_ 977 BT_SWA_HMI_defekt 0;
BA_ "GenSigSwitchedByIgnition" SG_ 977 BT_SWA_HMI_defekt 0;
BA_ "GenSigSendType" SG_ 977 BT_TAG_betaetigt 0;
BA_ "GenSigSwitchedByIgnition" SG_ 977 BT_TAG_betaetigt 0;
BA_ "GenSigSendType" SG_ 977 BT_TCR_Mode_aktiv 0;
BA_ "GenSigSwitchedByIgnition" SG_ 977 BT_TCR_Mode_aktiv 0;
BA_ "GenSigSendType" SG_ 977 BT_TIG_betaetigt 0;
BA_ "GenSigSwitchedByIgnition" SG_ 977 BT_TIG_betaetigt 0;
BA_ "GenSigSendType" SG_ 977 BT_TSG_hinten_verbaut 0;
BA_ "GenSigSwitchedByIgnition" SG_ 977 BT_TSG_hinten_verbaut 0;
BA_ "GenSigSendType" SG_ 977 BT_Tuer_geoeffnet 3;
BA_ "GenSigSwitchedByIgnition" SG_ 977 BT_Tuer_geoeffnet 0;
BA_ "GenSigSendType" SG_ 977 BT_Tuer_Status 0;
BA_ "GenSigSwitchedByIgnition" SG_ 977 BT_Tuer_Status 0;
BA_ "Fehlerwert" SG_ 977 BT_Tuer_Status 3;
BA_ "GenSigSendType" SG_ 977 BT_Tuer_Status_QBit 0;
BA_ "GenSigSwitchedByIgnition" SG_ 977 BT_Tuer_Status_QBit 0;
BA_ "GenSigSendType" SG_ 977 BT_Tueroeffnen_Warnung 3;
BA_ "GenSigSwitchedByIgnition" SG_ 977 BT_Tueroeffnen_Warnung 0;
BA_ "GenSigSendType" SG_ 977 BT_Tuerschloss_defekt 3;
BA_ "GenSigSwitchedByIgnition" SG_ 977 BT_Tuerschloss_defekt 0;
BA_ "GenSigSendType" SG_ 977 BT_UEKB_aktiviert 0;
BA_ "GenSigSwitchedByIgnition" SG_ 977 BT_UEKB_aktiviert 0;
BA_ "GenSigSendType" SG_ 977 BT_Unlock_Taster 0;
BA_ "GenSigSwitchedByIgnition" SG_ 977 BT_Unlock_Taster 0;
BA_ "GenSigSendType" SG_ 977 BT_Unten_Block_erw 0;
BA_ "GenSigSwitchedByIgnition" SG_ 977 BT_Unten_Block_erw 0;
BA_ "GenSigSendType" SG_ 977 BT_verriegelt 0;
BA_ "GenSigSwitchedByIgnition" SG_ 977 BT_verriegelt 0;
BA_ "GenSigSendType" SG_ 977 BT_Zuziehhilfe_aktiv 0;
BA_ "GenSigSwitchedByIgnition" SG_ 977 BT_Zuziehhilfe_aktiv 0;
BA_ "GenSigSendType" SG_ 1451 TSG_FlHz_BFS_FnAbbruchHzKreis_A 3;
BA_ "GenSigSwitchedByIgnition" SG_ 1451 TSG_FlHz_BFS_FnAbbruchHzKreis_A 0;
BA_ "GenSigSendType" SG_ 1451 TSG_FlHz_BFS_FnAbbruchHzKreis_B 3;
BA_ "GenSigSwitchedByIgnition" SG_ 1451 TSG_FlHz_BFS_FnAbbruchHzKreis_B 0;
BA_ "GenSigSendType" SG_ 1451 TSG_FlHz_BFS_NTC_A 3;
BA_ "GenSigStartValue" SG_ 1451 TSG_FlHz_BFS_NTC_A 127;
BA_ "GenSigSwitchedByIgnition" SG_ 1451 TSG_FlHz_BFS_NTC_A 0;
BA_ "GenSigSendType" SG_ 1451 TSG_FlHz_BFS_NTC_B 3;
BA_ "GenSigStartValue" SG_ 1451 TSG_FlHz_BFS_NTC_B 127;
BA_ "GenSigSwitchedByIgnition" SG_ 1451 TSG_FlHz_BFS_NTC_B 0;
BA_ "GenSigSendType" SG_ 976 ASW_HMI_defekt 0;
BA_ "GenSigSwitchedByIgnition" SG_ 976 ASW_HMI_defekt 0;
BA_ "GenSigSendType" SG_ 976 ASW_wakeup 0;
BA_ "GenSigSwitchedByIgnition" SG_ 976 ASW_wakeup 0;
BA_ "GenSigSendType" SG_ 976 ASW_Warnung_aktiv_FS 0;
BA_ "GenSigSwitchedByIgnition" SG_ 976 ASW_Warnung_aktiv_FS 0;
BA_ "GenSigSendType" SG_ 976 FS_Status_eTAG 0;
BA_ "GenSigSwitchedByIgnition" SG_ 976 FS_Status_eTAG 0;
BA_ "Fehlerwert" SG_ 976 FS_Status_eTAG 3;
BA_ "GenSigSendType" SG_ 976 FT_BFS_Fond_Freigabe 0;
BA_ "GenSigSwitchedByIgnition" SG_ 976 FT_BFS_Fond_Freigabe 0;
BA_ "GenSigSendType" SG_ 976 FT_Daemmglas 0;
BA_ "GenSigSwitchedByIgnition" SG_ 976 FT_Daemmglas 0;
BA_ "GenSigSendType" SG_ 976 FT_FH_Bew_hoch 0;
BA_ "GenSigSwitchedByIgnition" SG_ 976 FT_FH_Bew_hoch 0;
BA_ "GenSigSendType" SG_ 976 FT_FH_Bew_tief 0;
BA_ "GenSigSwitchedByIgnition" SG_ 976 FT_FH_Bew_tief 0;
BA_ "GenSigSendType" SG_ 976 FT_FH_Block 0;
BA_ "GenSigSwitchedByIgnition" SG_ 976 FT_FH_Block 0;
BA_ "GenSigSendType" SG_ 976 FT_FH_Fang 0;
BA_ "GenSigSwitchedByIgnition" SG_ 976 FT_FH_Fang 0;
BA_ "GenSigSendType" SG_ 976 FT_FH_normiert 0;
BA_ "GenSigSwitchedByIgnition" SG_ 976 FT_FH_normiert 0;
BA_ "GenSigSendType" SG_ 976 FT_FH_Oeffnung 3;
BA_ "GenSigSwitchedByIgnition" SG_ 976 FT_FH_Oeffnung 0;
BA_ "GenSigSendType" SG_ 976 FT_FH_Pos_oben 0;
BA_ "GenSigSwitchedByIgnition" SG_ 976 FT_FH_Pos_oben 0;
BA_ "GenSigSendType" SG_ 976 FT_FH_S_AutoHoch 0;
BA_ "GenSigSwitchedByIgnition" SG_ 976 FT_FH_S_AutoHoch 0;
BA_ "GenSigSendType" SG_ 976 FT_FH_S_AutoTief 0;
BA_ "GenSigSwitchedByIgnition" SG_ 976 FT_FH_S_AutoTief 0;
BA_ "GenSigSendType" SG_ 976 FT_FH_S_ManHoch 0;
BA_ "GenSigSwitchedByIgnition" SG_ 976 FT_FH_S_ManHoch 0;
BA_ "GenSigSendType" SG_ 976 FT_FH_S_ManTief 0;
BA_ "GenSigSwitchedByIgnition" SG_ 976 FT_FH_S_ManTief 0;
BA_ "GenSigSendType" SG_ 976 FT_FH_Thermo 0;
BA_ "GenSigSwitchedByIgnition" SG_ 976 FT_FH_Thermo 0;
BA_ "GenSigSendType" SG_ 976 FT_gesafet 0;
BA_ "GenSigSwitchedByIgnition" SG_ 976 FT_gesafet 0;
BA_ "GenSigSendType" SG_ 976 FT_HD_Taste 0;
BA_ "GenSigSwitchedByIgnition" SG_ 976 FT_HD_Taste 0;
BA_ "GenSigSendType" SG_ 976 FT_HD_Taste_2 3;
BA_ "GenSigSwitchedByIgnition" SG_ 976 FT_HD_Taste_2 0;
BA_ "GenSigSendType" SG_ 976 FT_IRUE_Taste 0;
BA_ "GenSigSwitchedByIgnition" SG_ 976 FT_IRUE_Taste 0;
BA_ "GenSigSendType" SG_ 976 FT_Kisi_Fehler 3;
BA_ "GenSigSwitchedByIgnition" SG_ 976 FT_Kisi_Fehler 0;
BA_ "Fehlerwert" SG_ 976 FT_Kisi_Fehler 1;
BA_ "GenSigSendType" SG_ 976 FT_Kisi_li_aktiv 0;
BA_ "GenSigSwitchedByIgnition" SG_ 976 FT_Kisi_li_aktiv 0;
BA_ "GenSigSendType" SG_ 976 FT_Kisi_re_aktiv 0;
BA_ "GenSigSwitchedByIgnition" SG_ 976 FT_Kisi_re_aktiv 0;
BA_ "GenSigSendType" SG_ 976 FT_Kisi_Taster_li 0;
BA_ "GenSigSwitchedByIgnition" SG_ 976 FT_Kisi_Taster_li 0;
BA_ "GenSigSendType" SG_ 976 FT_Kisi_Taster_re 0;
BA_ "GenSigSwitchedByIgnition" SG_ 976 FT_Kisi_Taster_re 0;
BA_ "GenSigSendType" SG_ 976 FT_Lock_Taster 0;
BA_ "GenSigSwitchedByIgnition" SG_ 976 FT_Lock_Taster 0;
BA_ "GenSigSendType" SG_ 976 FT_Oben_Block_erw 0;
BA_ "GenSigSwitchedByIgnition" SG_ 976 FT_Oben_Block_erw 0;
BA_ "GenSigSendType" SG_ 976 FT_Schliesstaster 0;
BA_ "GenSigSwitchedByIgnition" SG_ 976 FT_Schliesstaster 0;
BA_ "GenSigSendType" SG_ 976 FT_Schluesselschalter_auf 0;
BA_ "GenSigSwitchedByIgnition" SG_ 976 FT_Schluesselschalter_auf 0;
BA_ "GenSigSendType" SG_ 976 FT_Schluesselschalter_zu 0;
BA_ "GenSigSwitchedByIgnition" SG_ 976 FT_Schluesselschalter_zu 0;
BA_ "GenSigSendType" SG_ 976 FT_SP_ausgerastet 0;
BA_ "GenSigSwitchedByIgnition" SG_ 976 FT_SP_ausgerastet 0;
BA_ "GenSigSendType" SG_ 976 FT_Sp_Blk_def 0;
BA_ "GenSigSwitchedByIgnition" SG_ 976 FT_Sp_Blk_def 0;
BA_ "GenSigSendType" SG_ 976 FT_Sp_Heizung_Anf 0;
BA_ "GenSigSwitchedByIgnition" SG_ 976 FT_Sp_Heizung_Anf 0;
BA_ "GenSigSendType" SG_ 976 FT_SP_Heizung_Status 0;
BA_ "GenSigSwitchedByIgnition" SG_ 976 FT_SP_Heizung_Status 0;
BA_ "GenSigSendType" SG_ 976 FT_SP_ht_aktiv 0;
BA_ "GenSigSwitchedByIgnition" SG_ 976 FT_SP_ht_aktiv 0;
BA_ "GenSigSendType" SG_ 976 FT_SP_lr_aktiv 0;
BA_ "GenSigSwitchedByIgnition" SG_ 976 FT_SP_lr_aktiv 0;
BA_ "GenSigSendType" SG_ 976 FT_Sperrklinke 0;
BA_ "GenSigSwitchedByIgnition" SG_ 976 FT_Sperrklinke 0;
BA_ "GenSigSendType" SG_ 976 FT_SWA_Taster 0;
BA_ "GenSigSwitchedByIgnition" SG_ 976 FT_SWA_Taster 0;
BA_ "GenSigSendType" SG_ 976 FT_TAG_betaetigt 0;
BA_ "GenSigSwitchedByIgnition" SG_ 976 FT_TAG_betaetigt 0;
BA_ "GenSigSendType" SG_ 976 FT_TD_Taste 0;
BA_ "GenSigSwitchedByIgnition" SG_ 976 FT_TD_Taste 0;
BA_ "GenSigSendType" SG_ 976 FT_TD_Taste_Fehler 0;
BA_ "GenSigSwitchedByIgnition" SG_ 976 FT_TD_Taste_Fehler 0;
BA_ "GenSigSendType" SG_ 976 FT_TIG_betaetigt 0;
BA_ "GenSigSwitchedByIgnition" SG_ 976 FT_TIG_betaetigt 0;
BA_ "GenSigSendType" SG_ 976 FT_TSG_hinten_verbaut 0;
BA_ "GenSigSwitchedByIgnition" SG_ 976 FT_TSG_hinten_verbaut 0;
BA_ "GenSigSendType" SG_ 976 FT_Tuer_geoeffnet 3;
BA_ "GenSigSwitchedByIgnition" SG_ 976 FT_Tuer_geoeffnet 0;
BA_ "GenSigSendType" SG_ 976 FT_Tuerschloss_defekt 3;
BA_ "GenSigSwitchedByIgnition" SG_ 976 FT_Tuerschloss_defekt 0;
BA_ "GenSigSendType" SG_ 976 FT_UEKB_aktiviert 0;
BA_ "GenSigSwitchedByIgnition" SG_ 976 FT_UEKB_aktiviert 0;
BA_ "GenSigSendType" SG_ 976 FT_Unlock_Taster 0;
BA_ "GenSigSwitchedByIgnition" SG_ 976 FT_Unlock_Taster 0;
BA_ "GenSigSendType" SG_ 976 FT_Unten_Block_erw 0;
BA_ "GenSigSwitchedByIgnition" SG_ 976 FT_Unten_Block_erw 0;
BA_ "GenSigSendType" SG_ 976 FT_verriegelt 0;
BA_ "GenSigSwitchedByIgnition" SG_ 976 FT_verriegelt 0;
BA_ "GenSigSendType" SG_ 976 FT_Zuziehhilfe_aktiv 0;
BA_ "GenSigSwitchedByIgnition" SG_ 976 FT_Zuziehhilfe_aktiv 0;
BA_ "GenSigSendType" SG_ 976 SSR_Temp_Freigabe 0;
BA_ "GenSigSwitchedByIgnition" SG_ 976 SSR_Temp_Freigabe 0;
BA_ "GenSigSendType" SG_ 976 SWA_HMI_Diagnose 0;
BA_ "GenSigSwitchedByIgnition" SG_ 976 SWA_HMI_Diagnose 0;
BA_ "GenSigSendType" SG_ 997 FS_Push_Tuergriff 3;
BA_ "GenSigSwitchedByIgnition" SG_ 997 FS_Push_Tuergriff 0;
BA_ "GenSigSendType" SG_ 997 FT_BFS_Tuer_Status 3;
BA_ "GenSigSwitchedByIgnition" SG_ 997 FT_BFS_Tuer_Status 0;
BA_ "Fehlerwert" SG_ 997 FT_BFS_Tuer_Status 3;
BA_ "GenSigSendType" SG_ 997 FT_HBFS_Tuer_Status 3;
BA_ "GenSigSwitchedByIgnition" SG_ 997 FT_HBFS_Tuer_Status 0;
BA_ "Fehlerwert" SG_ 997 FT_HBFS_Tuer_Status 3;
BA_ "GenSigSendType" SG_ 997 FT_HFS_Tuer_Status 3;
BA_ "GenSigSwitchedByIgnition" SG_ 997 FT_HFS_Tuer_Status 0;
BA_ "Fehlerwert" SG_ 997 FT_HFS_Tuer_Status 3;
BA_ "GenSigSendType" SG_ 997 FT_Kisi_Taster_li_02 3;
BA_ "GenSigSwitchedByIgnition" SG_ 997 FT_Kisi_Taster_li_02 0;
BA_ "GenSigSendType" SG_ 997 FT_Kisi_Taster_re_02 3;
BA_ "GenSigSwitchedByIgnition" SG_ 997 FT_Kisi_Taster_re_02 0;
BA_ "GenSigSendType" SG_ 997 FT_Lock_Taster_02 3;
BA_ "GenSigSwitchedByIgnition" SG_ 997 FT_Lock_Taster_02 0;
BA_ "GenSigSendType" SG_ 997 FT_Schluesselschalter_zu_02 3;
BA_ "GenSigSwitchedByIgnition" SG_ 997 FT_Schluesselschalter_zu_02 0;
BA_ "GenSigSendType" SG_ 997 FT_SP_Heizung_ein 3;
BA_ "GenSigSwitchedByIgnition" SG_ 997 FT_SP_Heizung_ein 0;
BA_ "GenSigSendType" SG_ 997 FT_TCR_Mode_aktiv 3;
BA_ "GenSigSwitchedByIgnition" SG_ 997 FT_TCR_Mode_aktiv 0;
BA_ "GenSigSendType" SG_ 997 FT_TD_Taste_Status 3;
BA_ "GenSigSwitchedByIgnition" SG_ 997 FT_TD_Taste_Status 0;
BA_ "GenSigSendType" SG_ 997 FT_Tuer_Status 3;
BA_ "GenSigSwitchedByIgnition" SG_ 997 FT_Tuer_Status 0;
BA_ "Fehlerwert" SG_ 997 FT_Tuer_Status 3;
BA_ "GenSigSendType" SG_ 997 FT_Tuer_Status_QBit 3;
BA_ "GenSigSwitchedByIgnition" SG_ 997 FT_Tuer_Status_QBit 0;
BA_ "GenSigSendType" SG_ 997 FT_Tueroeffnen_Warnung 3;
BA_ "GenSigSwitchedByIgnition" SG_ 997 FT_Tueroeffnen_Warnung 0;
BA_ "GenSigSendType" SG_ 997 TSG_FT_02_BZ 0;
BA_ "GenSigFuncType" SG_ 997 TSG_FT_02_BZ 1;
BA_ "GenSigSwitchedByIgnition" SG_ 997 TSG_FT_02_BZ 0;
BA_ "GenSigSendType" SG_ 997 TSG_FT_02_CRC 0;
BA_ "GenSigFuncType" SG_ 997 TSG_FT_02_CRC 2;
BA_ "GenSigSwitchedByIgnition" SG_ 997 TSG_FT_02_CRC 0;
BA_ "GenSigSendType" SG_ 1449 TSG_FlHz_FS_FnAbbruchHzKreis_A 3;
BA_ "GenSigSwitchedByIgnition" SG_ 1449 TSG_FlHz_FS_FnAbbruchHzKreis_A 0;
BA_ "GenSigSendType" SG_ 1449 TSG_FlHz_FS_FnAbbruchHzKreis_B 3;
BA_ "GenSigSwitchedByIgnition" SG_ 1449 TSG_FlHz_FS_FnAbbruchHzKreis_B 0;
BA_ "GenSigSendType" SG_ 1449 TSG_FlHz_FS_NTC_A 3;
BA_ "GenSigStartValue" SG_ 1449 TSG_FlHz_FS_NTC_A 127;
BA_ "GenSigSwitchedByIgnition" SG_ 1449 TSG_FlHz_FS_NTC_A 0;
BA_ "GenSigSendType" SG_ 1449 TSG_FlHz_FS_NTC_B 3;
BA_ "GenSigStartValue" SG_ 1449 TSG_FlHz_FS_NTC_B 127;
BA_ "GenSigSwitchedByIgnition" SG_ 1449 TSG_FlHz_FS_NTC_B 0;
BA_ "GenSigSendType" SG_ 975 ASW_Warnung_aktiv_HBFS 0;
BA_ "GenSigSwitchedByIgnition" SG_ 975 ASW_Warnung_aktiv_HBFS 0;
BA_ "GenSigSendType" SG_ 975 HBFS_FH_Bew_hoch 0;
BA_ "GenSigSwitchedByIgnition" SG_ 975 HBFS_FH_Bew_hoch 0;
BA_ "GenSigSendType" SG_ 975 HBFS_FH_Bew_tief 0;
BA_ "GenSigSwitchedByIgnition" SG_ 975 HBFS_FH_Bew_tief 0;
BA_ "GenSigSendType" SG_ 975 HBFS_FH_Block 0;
BA_ "GenSigSwitchedByIgnition" SG_ 975 HBFS_FH_Block 0;
BA_ "GenSigSendType" SG_ 975 HBFS_FH_Fang 0;
BA_ "GenSigSwitchedByIgnition" SG_ 975 HBFS_FH_Fang 0;
BA_ "GenSigSendType" SG_ 975 HBFS_FH_normiert 0;
BA_ "GenSigSwitchedByIgnition" SG_ 975 HBFS_FH_normiert 0;
BA_ "GenSigSendType" SG_ 975 HBFS_FH_Oeffnung 3;
BA_ "GenSigSwitchedByIgnition" SG_ 975 HBFS_FH_Oeffnung 0;
BA_ "GenSigSendType" SG_ 975 HBFS_FH_S_AutoHoch 0;
BA_ "GenSigSwitchedByIgnition" SG_ 975 HBFS_FH_S_AutoHoch 0;
BA_ "GenSigSendType" SG_ 975 HBFS_FH_S_AutoTief 0;
BA_ "GenSigSwitchedByIgnition" SG_ 975 HBFS_FH_S_AutoTief 0;
BA_ "GenSigSendType" SG_ 975 HBFS_FH_S_HFS_AutoHoch 0;
BA_ "GenSigSwitchedByIgnition" SG_ 975 HBFS_FH_S_HFS_AutoHoch 0;
BA_ "GenSigSendType" SG_ 975 HBFS_FH_S_HFS_AutoTief 0;
BA_ "GenSigSwitchedByIgnition" SG_ 975 HBFS_FH_S_HFS_AutoTief 0;
BA_ "GenSigSendType" SG_ 975 HBFS_FH_S_HFS_ManHoch 0;
BA_ "GenSigSwitchedByIgnition" SG_ 975 HBFS_FH_S_HFS_ManHoch 0;
BA_ "GenSigSendType" SG_ 975 HBFS_FH_S_HFS_ManTief 0;
BA_ "GenSigSwitchedByIgnition" SG_ 975 HBFS_FH_S_HFS_ManTief 0;
BA_ "GenSigSendType" SG_ 975 HBFS_FH_S_ManHoch 0;
BA_ "GenSigSwitchedByIgnition" SG_ 975 HBFS_FH_S_ManHoch 0;
BA_ "GenSigSendType" SG_ 975 HBFS_FH_S_ManTief 0;
BA_ "GenSigSwitchedByIgnition" SG_ 975 HBFS_FH_S_ManTief 0;
BA_ "GenSigSendType" SG_ 975 HBFS_FH_Thermo 0;
BA_ "GenSigSwitchedByIgnition" SG_ 975 HBFS_FH_Thermo 0;
BA_ "GenSigSendType" SG_ 975 HBFS_gesafet 0;
BA_ "GenSigSwitchedByIgnition" SG_ 975 HBFS_gesafet 0;
BA_ "GenSigSendType" SG_ 975 HBFS_Heckrollotaster_betaetigt 0;
BA_ "GenSigSwitchedByIgnition" SG_ 975 HBFS_Heckrollotaster_betaetigt 0;
BA_ "GenSigSendType" SG_ 975 HBFS_Lock_Taster 0;
BA_ "GenSigSwitchedByIgnition" SG_ 975 HBFS_Lock_Taster 0;
BA_ "GenSigSendType" SG_ 975 HBFS_Lock_Taster_inv 0;
BA_ "GenSigSwitchedByIgnition" SG_ 975 HBFS_Lock_Taster_inv 0;
BA_ "GenSigSendType" SG_ 975 HBFS_MRollo_Schalter 0;
BA_ "GenSigStartValue" SG_ 975 HBFS_MRollo_Schalter 6;
BA_ "GenSigSwitchedByIgnition" SG_ 975 HBFS_MRollo_Schalter 0;
BA_ "Fehlerwert" SG_ 975 HBFS_MRollo_Schalter 7;
BA_ "GenSigSendType" SG_ 975 HBFS_Oben_Block_erw 0;
BA_ "GenSigSwitchedByIgnition" SG_ 975 HBFS_Oben_Block_erw 0;
BA_ "GenSigSendType" SG_ 975 HBFS_SAD_Schalter 0;
BA_ "GenSigStartValue" SG_ 975 HBFS_SAD_Schalter 14;
BA_ "GenSigSwitchedByIgnition" SG_ 975 HBFS_SAD_Schalter 0;
BA_ "Fehlerwert" SG_ 975 HBFS_SAD_Schalter 15;
BA_ "GenSigSendType" SG_ 975 HBFS_Seitenrollo_hoch 0;
BA_ "GenSigSwitchedByIgnition" SG_ 975 HBFS_Seitenrollo_hoch 0;
BA_ "GenSigSendType" SG_ 975 HBFS_Seitenrollo_tief 0;
BA_ "GenSigSwitchedByIgnition" SG_ 975 HBFS_Seitenrollo_tief 0;
BA_ "GenSigSendType" SG_ 975 HBFS_Sperrklinke 0;
BA_ "GenSigSwitchedByIgnition" SG_ 975 HBFS_Sperrklinke 0;
BA_ "GenSigSendType" SG_ 975 HBFS_Status_eTAG 0;
BA_ "GenSigSwitchedByIgnition" SG_ 975 HBFS_Status_eTAG 0;
BA_ "Fehlerwert" SG_ 975 HBFS_Status_eTAG 3;
BA_ "GenSigSendType" SG_ 975 HBFS_Status_KiSi 0;
BA_ "GenSigSwitchedByIgnition" SG_ 975 HBFS_Status_KiSi 0;
BA_ "GenSigSendType" SG_ 975 HBFS_Status_KiSi_inv 0;
BA_ "GenSigStartValue" SG_ 975 HBFS_Status_KiSi_inv 1;
BA_ "GenSigSwitchedByIgnition" SG_ 975 HBFS_Status_KiSi_inv 0;
BA_ "GenSigSendType" SG_ 975 HBFS_TAG_betaetigt 0;
BA_ "GenSigSwitchedByIgnition" SG_ 975 HBFS_TAG_betaetigt 0;
BA_ "GenSigSendType" SG_ 975 HBFS_TIG_betaetigt 0;
BA_ "GenSigSwitchedByIgnition" SG_ 975 HBFS_TIG_betaetigt 0;
BA_ "GenSigSendType" SG_ 975 HBFS_TIG_betaetigt_schliessen 3;
BA_ "GenSigSwitchedByIgnition" SG_ 975 HBFS_TIG_betaetigt_schliessen 0;
BA_ "GenSigSendType" SG_ 975 HBFS_Tuer_geoeffnet 3;
BA_ "GenSigSwitchedByIgnition" SG_ 975 HBFS_Tuer_geoeffnet 0;
BA_ "GenSigSendType" SG_ 975 HBFS_Tuer_Status 0;
BA_ "GenSigSwitchedByIgnition" SG_ 975 HBFS_Tuer_Status 0;
BA_ "Fehlerwert" SG_ 975 HBFS_Tuer_Status 3;
BA_ "GenSigSendType" SG_ 975 HBFS_Tuer_Status_QBit 0;
BA_ "GenSigSwitchedByIgnition" SG_ 975 HBFS_Tuer_Status_QBit 0;
BA_ "GenSigSendType" SG_ 975 HBFS_Tueroeffnen_Warnung 3;
BA_ "GenSigSwitchedByIgnition" SG_ 975 HBFS_Tueroeffnen_Warnung 0;
BA_ "GenSigSendType" SG_ 975 HBFS_Tuerschloss_defekt 3;
BA_ "GenSigSwitchedByIgnition" SG_ 975 HBFS_Tuerschloss_defekt 0;
BA_ "GenSigSendType" SG_ 975 HBFS_UEKB_aktiviert 0;
BA_ "GenSigSwitchedByIgnition" SG_ 975 HBFS_UEKB_aktiviert 0;
BA_ "GenSigSendType" SG_ 975 HBFS_Unlock_Taster 0;
BA_ "GenSigSwitchedByIgnition" SG_ 975 HBFS_Unlock_Taster 0;
BA_ "GenSigSendType" SG_ 975 HBFS_Unten_Block_erw 0;
BA_ "GenSigSwitchedByIgnition" SG_ 975 HBFS_Unten_Block_erw 0;
BA_ "GenSigSendType" SG_ 975 HBFS_verriegelt 0;
BA_ "GenSigSwitchedByIgnition" SG_ 975 HBFS_verriegelt 0;
BA_ "GenSigSendType" SG_ 975 HBFS_Zuziehhilfe_aktiv 0;
BA_ "GenSigSwitchedByIgnition" SG_ 975 HBFS_Zuziehhilfe_aktiv 0;
BA_ "GenSigSendType" SG_ 975 MTHBFS_M_Taste 0;
BA_ "GenSigSwitchedByIgnition" SG_ 975 MTHBFS_M_Taste 0;
BA_ "GenSigSendType" SG_ 975 MTHBFS_Pos1 0;
BA_ "GenSigSwitchedByIgnition" SG_ 975 MTHBFS_Pos1 0;
BA_ "GenSigSendType" SG_ 975 MTHBFS_Pos2 0;
BA_ "GenSigSwitchedByIgnition" SG_ 975 MTHBFS_Pos2 0;
BA_ "GenSigSendType" SG_ 975 MTHBFS_Pos3 0;
BA_ "GenSigSwitchedByIgnition" SG_ 975 MTHBFS_Pos3 0;
BA_ "GenSigSendType" SG_ 975 SSR_HBFS_Pos_Unten 0;
BA_ "GenSigSwitchedByIgnition" SG_ 975 SSR_HBFS_Pos_Unten 0;
BA_ "GenSigSendType" SG_ 1457 TSG_FlHz_HBFS_FnAbbruchHzKreis_A 3;
BA_ "GenSigSwitchedByIgnition" SG_ 1457 TSG_FlHz_HBFS_FnAbbruchHzKreis_A 0;
BA_ "GenSigSendType" SG_ 1457 TSG_FlHz_HBFS_FnAbbruchHzKreis_B 3;
BA_ "GenSigSwitchedByIgnition" SG_ 1457 TSG_FlHz_HBFS_FnAbbruchHzKreis_B 0;
BA_ "GenSigSendType" SG_ 1457 TSG_FlHz_HBFS_NTC_A 3;
BA_ "GenSigStartValue" SG_ 1457 TSG_FlHz_HBFS_NTC_A 127;
BA_ "GenSigSwitchedByIgnition" SG_ 1457 TSG_FlHz_HBFS_NTC_A 0;
BA_ "GenSigSendType" SG_ 1457 TSG_FlHz_HBFS_NTC_B 3;
BA_ "GenSigStartValue" SG_ 1457 TSG_FlHz_HBFS_NTC_B 127;
BA_ "GenSigSwitchedByIgnition" SG_ 1457 TSG_FlHz_HBFS_NTC_B 0;
BA_ "GenSigSendType" SG_ 974 ASW_Warnung_aktiv_HFS 0;
BA_ "GenSigSwitchedByIgnition" SG_ 974 ASW_Warnung_aktiv_HFS 0;
BA_ "GenSigSendType" SG_ 974 HFS_FH_Bew_hoch 0;
BA_ "GenSigSwitchedByIgnition" SG_ 974 HFS_FH_Bew_hoch 0;
BA_ "GenSigSendType" SG_ 974 HFS_FH_Bew_tief 0;
BA_ "GenSigSwitchedByIgnition" SG_ 974 HFS_FH_Bew_tief 0;
BA_ "GenSigSendType" SG_ 974 HFS_FH_Block 0;
BA_ "GenSigSwitchedByIgnition" SG_ 974 HFS_FH_Block 0;
BA_ "GenSigSendType" SG_ 974 HFS_FH_Fang 0;
BA_ "GenSigSwitchedByIgnition" SG_ 974 HFS_FH_Fang 0;
BA_ "GenSigSendType" SG_ 974 HFS_FH_normiert 0;
BA_ "GenSigSwitchedByIgnition" SG_ 974 HFS_FH_normiert 0;
BA_ "GenSigSendType" SG_ 974 HFS_FH_Oeffnung 3;
BA_ "GenSigSwitchedByIgnition" SG_ 974 HFS_FH_Oeffnung 0;
BA_ "GenSigSendType" SG_ 974 HFS_FH_S_AutoHoch 0;
BA_ "GenSigSwitchedByIgnition" SG_ 974 HFS_FH_S_AutoHoch 0;
BA_ "GenSigSendType" SG_ 974 HFS_FH_S_AutoTief 0;
BA_ "GenSigSwitchedByIgnition" SG_ 974 HFS_FH_S_AutoTief 0;
BA_ "GenSigSendType" SG_ 974 HFS_FH_S_HBFS_AutoHoch 0;
BA_ "GenSigSwitchedByIgnition" SG_ 974 HFS_FH_S_HBFS_AutoHoch 0;
BA_ "GenSigSendType" SG_ 974 HFS_FH_S_HBFS_AutoTief 0;
BA_ "GenSigSwitchedByIgnition" SG_ 974 HFS_FH_S_HBFS_AutoTief 0;
BA_ "GenSigSendType" SG_ 974 HFS_FH_S_HBFS_ManHoch 0;
BA_ "GenSigSwitchedByIgnition" SG_ 974 HFS_FH_S_HBFS_ManHoch 0;
BA_ "GenSigSendType" SG_ 974 HFS_FH_S_HBFS_ManTief 0;
BA_ "GenSigSwitchedByIgnition" SG_ 974 HFS_FH_S_HBFS_ManTief 0;
BA_ "GenSigSendType" SG_ 974 HFS_FH_S_ManHoch 0;
BA_ "GenSigSwitchedByIgnition" SG_ 974 HFS_FH_S_ManHoch 0;
BA_ "GenSigSendType" SG_ 974 HFS_FH_S_ManTief 0;
BA_ "GenSigSwitchedByIgnition" SG_ 974 HFS_FH_S_ManTief 0;
BA_ "GenSigSendType" SG_ 974 HFS_FH_Thermo 0;
BA_ "GenSigSwitchedByIgnition" SG_ 974 HFS_FH_Thermo 0;
BA_ "GenSigSendType" SG_ 974 HFS_gesafet 0;
BA_ "GenSigSwitchedByIgnition" SG_ 974 HFS_gesafet 0;
BA_ "GenSigSendType" SG_ 974 HFS_Heckrollotaster_betaetigt 0;
BA_ "GenSigSwitchedByIgnition" SG_ 974 HFS_Heckrollotaster_betaetigt 0;
BA_ "GenSigSendType" SG_ 974 HFS_Lock_Taster 0;
BA_ "GenSigSwitchedByIgnition" SG_ 974 HFS_Lock_Taster 0;
BA_ "GenSigSendType" SG_ 974 HFS_Lock_Taster_inv 0;
BA_ "GenSigSwitchedByIgnition" SG_ 974 HFS_Lock_Taster_inv 0;
BA_ "GenSigSendType" SG_ 974 HFS_MRollo_Schalter 0;
BA_ "GenSigStartValue" SG_ 974 HFS_MRollo_Schalter 6;
BA_ "GenSigSwitchedByIgnition" SG_ 974 HFS_MRollo_Schalter 0;
BA_ "Fehlerwert" SG_ 974 HFS_MRollo_Schalter 7;
BA_ "GenSigSendType" SG_ 974 HFS_Oben_Block_erw 0;
BA_ "GenSigSwitchedByIgnition" SG_ 974 HFS_Oben_Block_erw 0;
BA_ "GenSigSendType" SG_ 974 HFS_SAD_Schalter 0;
BA_ "GenSigStartValue" SG_ 974 HFS_SAD_Schalter 14;
BA_ "GenSigSwitchedByIgnition" SG_ 974 HFS_SAD_Schalter 0;
BA_ "Fehlerwert" SG_ 974 HFS_SAD_Schalter 15;
BA_ "GenSigSendType" SG_ 974 HFS_Seitenrollo_hoch 0;
BA_ "GenSigSwitchedByIgnition" SG_ 974 HFS_Seitenrollo_hoch 0;
BA_ "GenSigSendType" SG_ 974 HFS_Seitenrollo_tief 0;
BA_ "GenSigSwitchedByIgnition" SG_ 974 HFS_Seitenrollo_tief 0;
BA_ "GenSigSendType" SG_ 974 HFS_Sperrklinke 0;
BA_ "GenSigSwitchedByIgnition" SG_ 974 HFS_Sperrklinke 0;
BA_ "GenSigSendType" SG_ 974 HFS_Status_eTAG 0;
BA_ "GenSigSwitchedByIgnition" SG_ 974 HFS_Status_eTAG 0;
BA_ "Fehlerwert" SG_ 974 HFS_Status_eTAG 3;
BA_ "GenSigSendType" SG_ 974 HFS_Status_KiSi 0;
BA_ "GenSigSwitchedByIgnition" SG_ 974 HFS_Status_KiSi 0;
BA_ "GenSigSendType" SG_ 974 HFS_TAG_betaetigt 0;
BA_ "GenSigSwitchedByIgnition" SG_ 974 HFS_TAG_betaetigt 0;
BA_ "GenSigSendType" SG_ 974 HFS_TCR_Mode_aktiv 0;
BA_ "GenSigSwitchedByIgnition" SG_ 974 HFS_TCR_Mode_aktiv 0;
BA_ "GenSigSendType" SG_ 974 HFS_TIG_betaetigt 0;
BA_ "GenSigSwitchedByIgnition" SG_ 974 HFS_TIG_betaetigt 0;
BA_ "GenSigSendType" SG_ 974 HFS_Tuer_geoeffnet 3;
BA_ "GenSigSwitchedByIgnition" SG_ 974 HFS_Tuer_geoeffnet 0;
BA_ "GenSigSendType" SG_ 974 HFS_Tuer_Status 0;
BA_ "GenSigSwitchedByIgnition" SG_ 974 HFS_Tuer_Status 0;
BA_ "Fehlerwert" SG_ 974 HFS_Tuer_Status 3;
BA_ "GenSigSendType" SG_ 974 HFS_Tuer_Status_QBit 0;
BA_ "GenSigSwitchedByIgnition" SG_ 974 HFS_Tuer_Status_QBit 0;
BA_ "GenSigSendType" SG_ 974 HFS_Tueroeffnen_Warnung 3;
BA_ "GenSigSwitchedByIgnition" SG_ 974 HFS_Tueroeffnen_Warnung 0;
BA_ "GenSigSendType" SG_ 974 HFS_Tuerschloss_defekt 3;
BA_ "GenSigSwitchedByIgnition" SG_ 974 HFS_Tuerschloss_defekt 0;
BA_ "GenSigSendType" SG_ 974 HFS_UEKB_aktiviert 0;
BA_ "GenSigSwitchedByIgnition" SG_ 974 HFS_UEKB_aktiviert 0;
BA_ "GenSigSendType" SG_ 974 HFS_Unlock_Taster 0;
BA_ "GenSigSwitchedByIgnition" SG_ 974 HFS_Unlock_Taster 0;
BA_ "GenSigSendType" SG_ 974 HFS_Unten_Block_erw 0;
BA_ "GenSigSwitchedByIgnition" SG_ 974 HFS_Unten_Block_erw 0;
BA_ "GenSigSendType" SG_ 974 HFS_verriegelt 0;
BA_ "GenSigSwitchedByIgnition" SG_ 974 HFS_verriegelt 0;
BA_ "GenSigSendType" SG_ 974 HFS_Zuziehhilfe_aktiv 0;
BA_ "GenSigSwitchedByIgnition" SG_ 974 HFS_Zuziehhilfe_aktiv 0;
BA_ "GenSigSendType" SG_ 974 MTHFS_M_Taste 0;
BA_ "GenSigSwitchedByIgnition" SG_ 974 MTHFS_M_Taste 0;
BA_ "GenSigSendType" SG_ 974 MTHFS_Pos1 0;
BA_ "GenSigSwitchedByIgnition" SG_ 974 MTHFS_Pos1 0;
BA_ "GenSigSendType" SG_ 974 MTHFS_Pos2 0;
BA_ "GenSigSwitchedByIgnition" SG_ 974 MTHFS_Pos2 0;
BA_ "GenSigSendType" SG_ 974 MTHFS_Pos3 0;
BA_ "GenSigSwitchedByIgnition" SG_ 974 MTHFS_Pos3 0;
BA_ "GenSigSendType" SG_ 974 SSR_HFS_Pos_Unten 0;
BA_ "GenSigSwitchedByIgnition" SG_ 974 SSR_HFS_Pos_Unten 0;
BA_ "GenSigSendType" SG_ 1458 TSG_FlHz_HFS_FnAbbruchHzKreis_A 3;
BA_ "GenSigSwitchedByIgnition" SG_ 1458 TSG_FlHz_HFS_FnAbbruchHzKreis_A 0;
BA_ "GenSigSendType" SG_ 1458 TSG_FlHz_HFS_FnAbbruchHzKreis_B 3;
BA_ "GenSigSwitchedByIgnition" SG_ 1458 TSG_FlHz_HFS_FnAbbruchHzKreis_B 0;
BA_ "GenSigSendType" SG_ 1458 TSG_FlHz_HFS_NTC_A 3;
BA_ "GenSigStartValue" SG_ 1458 TSG_FlHz_HFS_NTC_A 127;
BA_ "GenSigSwitchedByIgnition" SG_ 1458 TSG_FlHz_HFS_NTC_A 0;
BA_ "GenSigSendType" SG_ 1458 TSG_FlHz_HFS_NTC_B 3;
BA_ "GenSigStartValue" SG_ 1458 TSG_FlHz_HFS_NTC_B 127;
BA_ "GenSigSwitchedByIgnition" SG_ 1458 TSG_FlHz_HFS_NTC_B 0;
BA_ "GenSigSendType" SG_ 346 MO_Anforderung_HMS 3;
BA_ "GenSigSwitchedByIgnition" SG_ 346 MO_Anforderung_HMS 0;
BA_ "GenSigSendType" SG_ 346 TSK_08_BZ 0;
BA_ "GenSigFuncType" SG_ 346 TSK_08_BZ 1;
BA_ "GenSigSwitchedByIgnition" SG_ 346 TSK_08_BZ 0;
BA_ "GenSigSendType" SG_ 346 TSK_08_CRC 0;
BA_ "GenSigFuncType" SG_ 346 TSK_08_CRC 2;
BA_ "GenSigSwitchedByIgnition" SG_ 346 TSK_08_CRC 0;
BA_ "GenSigSendType" SG_ 346 TSK_aktives_System 3;
BA_ "GenSigSwitchedByIgnition" SG_ 346 TSK_aktives_System 0;
BA_ "GenSigSendType" SG_ 346 TSK_Anf_Antriebsmoment 3;
BA_ "GenSigSwitchedByIgnition" SG_ 346 TSK_Anf_Antriebsmoment 0;
BA_ "GenSigSendType" SG_ 346 TSK_Einheit_vMax_Fahrerassistenz 0;
BA_ "GenSigSwitchedByIgnition" SG_ 346 TSK_Einheit_vMax_Fahrerassistenz 0;
BA_ "GenSigSendType" SG_ 346 TSK_erhoehter_Fahrwiderstand 3;
BA_ "GenSigSwitchedByIgnition" SG_ 346 TSK_erhoehter_Fahrwiderstand 0;
BA_ "GenSigSendType" SG_ 346 TSK_Status_ARA 3;
BA_ "GenSigStartValue" SG_ 346 TSK_Status_ARA 1;
BA_ "GenSigSwitchedByIgnition" SG_ 346 TSK_Status_ARA 0;
BA_ "Fehlerwert" SG_ 346 TSK_Status_ARA 7;
BA_ "GenSigSendType" SG_ 346 TSK_Status_EA 3;
BA_ "GenSigStartValue" SG_ 346 TSK_Status_EA 1;
BA_ "GenSigSwitchedByIgnition" SG_ 346 TSK_Status_EA 0;
BA_ "Fehlerwert" SG_ 346 TSK_Status_EA 7;
BA_ "GenSigSendType" SG_ 346 TSK_Status_IPA 3;
BA_ "GenSigStartValue" SG_ 346 TSK_Status_IPA 1;
BA_ "GenSigSwitchedByIgnition" SG_ 346 TSK_Status_IPA 0;
BA_ "Fehlerwert" SG_ 346 TSK_Status_IPA 7;
BA_ "GenSigSendType" SG_ 346 TSK_Status_PLA 3;
BA_ "GenSigStartValue" SG_ 346 TSK_Status_PLA 1;
BA_ "GenSigSwitchedByIgnition" SG_ 346 TSK_Status_PLA 0;
BA_ "Fehlerwert" SG_ 346 TSK_Status_PLA 7;
BA_ "GenSigSendType" SG_ 346 TSK_vMax_aktuell 0;
BA_ "GenSigStartValue" SG_ 346 TSK_vMax_aktuell 255;
BA_ "GenSigSendType" SG_ 346 TSK_vMax_Fahrerassistenz 0;
BA_ "GenSigStartValue" SG_ 346 TSK_vMax_Fahrerassistenz 511;
BA_ "GenSigSwitchedByIgnition" SG_ 346 TSK_vMax_Fahrerassistenz 0;
BA_ "GenSigSendType" SG_ 2589283609 UGDO_Channel_1 3;
BA_ "GenSigSwitchedByIgnition" SG_ 2589283609 UGDO_Channel_1 0;
BA_ "GenSigSendType" SG_ 2589283609 UGDO_Channel_10 3;
BA_ "GenSigSwitchedByIgnition" SG_ 2589283609 UGDO_Channel_10 0;
BA_ "GenSigSendType" SG_ 2589283609 UGDO_Channel_11 3;
BA_ "GenSigSwitchedByIgnition" SG_ 2589283609 UGDO_Channel_11 0;
BA_ "GenSigSendType" SG_ 2589283609 UGDO_Channel_12 3;
BA_ "GenSigSwitchedByIgnition" SG_ 2589283609 UGDO_Channel_12 0;
BA_ "GenSigSendType" SG_ 2589283609 UGDO_Channel_13 3;
BA_ "GenSigSwitchedByIgnition" SG_ 2589283609 UGDO_Channel_13 0;
BA_ "GenSigSendType" SG_ 2589283609 UGDO_Channel_14 3;
BA_ "GenSigSwitchedByIgnition" SG_ 2589283609 UGDO_Channel_14 0;
BA_ "GenSigSendType" SG_ 2589283609 UGDO_Channel_15 3;
BA_ "GenSigSwitchedByIgnition" SG_ 2589283609 UGDO_Channel_15 0;
BA_ "GenSigSendType" SG_ 2589283609 UGDO_Channel_2 3;
BA_ "GenSigSwitchedByIgnition" SG_ 2589283609 UGDO_Channel_2 0;
BA_ "GenSigSendType" SG_ 2589283609 UGDO_Channel_3 3;
BA_ "GenSigSwitchedByIgnition" SG_ 2589283609 UGDO_Channel_3 0;
BA_ "GenSigSendType" SG_ 2589283609 UGDO_Channel_4 3;
BA_ "GenSigSwitchedByIgnition" SG_ 2589283609 UGDO_Channel_4 0;
BA_ "GenSigSendType" SG_ 2589283609 UGDO_Channel_5 3;
BA_ "GenSigSwitchedByIgnition" SG_ 2589283609 UGDO_Channel_5 0;
BA_ "GenSigSendType" SG_ 2589283609 UGDO_Channel_6 3;
BA_ "GenSigSwitchedByIgnition" SG_ 2589283609 UGDO_Channel_6 0;
BA_ "GenSigSendType" SG_ 2589283609 UGDO_Channel_7 3;
BA_ "GenSigSwitchedByIgnition" SG_ 2589283609 UGDO_Channel_7 0;
BA_ "GenSigSendType" SG_ 2589283609 UGDO_Channel_8 3;
BA_ "GenSigSwitchedByIgnition" SG_ 2589283609 UGDO_Channel_8 0;
BA_ "GenSigSendType" SG_ 2589283609 UGDO_Channel_9 3;
BA_ "GenSigSwitchedByIgnition" SG_ 2589283609 UGDO_Channel_9 0;
BA_ "GenSigSendType" SG_ 2589283609 UGDO_DoorState 3;
BA_ "GenSigSwitchedByIgnition" SG_ 2589283609 UGDO_DoorState 0;
BA_ "GenSigSendType" SG_ 2589283609 UGDO_Failure_Antenne 0;
BA_ "Fehlerwert" SG_ 2589283609 UGDO_Failure_Antenne 1;
BA_ "GenSigSendType" SG_ 2589283609 UGDO_Failure_Codierung 0;
BA_ "Fehlerwert" SG_ 2589283609 UGDO_Failure_Codierung 1;
BA_ "GenSigSendType" SG_ 2589283609 UGDO_Failure_Hardware 0;
BA_ "Fehlerwert" SG_ 2589283609 UGDO_Failure_Hardware 1;
BA_ "GenSigSendType" SG_ 2589283609 UGDO_Function_01 0;
BA_ "Fehlerwert" SG_ 2589283609 UGDO_Function_01 7;
BA_ "GenSigSendType" SG_ 2589283609 UGDO_LED_Code_01 0;
BA_ "GenSigSendType" SG_ 2589283609 UGDO_ResponseError 0;
BA_ "Fehlerwert" SG_ 2589283609 UGDO_ResponseError 1;
BA_ "GenSigSendType" SG_ 1718 UH_DLS 0;
BA_ "GenSigSwitchedByIgnition" SG_ 1718 UH_DLS 0;
BA_ "GenSigSendType" SG_ 1718 UH_Jahr 0;
BA_ "GenSigSwitchedByIgnition" SG_ 1718 UH_Jahr 0;
BA_ "GenSigSendType" SG_ 1718 UH_Minute 0;
BA_ "GenSigSwitchedByIgnition" SG_ 1718 UH_Minute 0;
BA_ "GenSigSendType" SG_ 1718 UH_Monat 0;
BA_ "GenSigSwitchedByIgnition" SG_ 1718 UH_Monat 0;
BA_ "Fehlerwert" SG_ 1718 UH_Monat 15;
BA_ "GenSigSendType" SG_ 1718 UH_Sekunde 0;
BA_ "GenSigSwitchedByIgnition" SG_ 1718 UH_Sekunde 0;
BA_ "GenSigSendType" SG_ 1718 UH_Stunde 0;
BA_ "GenSigSwitchedByIgnition" SG_ 1718 UH_Stunde 0;
BA_ "GenSigSendType" SG_ 1718 UH_Tag 0;
BA_ "GenSigSwitchedByIgnition" SG_ 1718 UH_Tag 0;
BA_ "GenSigSendType" SG_ 1718 UH_Typ 0;
BA_ "GenSigFuncType" SG_ 1718 UH_Typ 8;
BA_ "GenSigSwitchedByIgnition" SG_ 1718 UH_Typ 0;
BA_REL_ "GenSigTimeoutTime" BU_SG_REL_ BedienDisp_vo SG_ 1413 SI_T_Mode 5000;
BA_REL_ "GenSigTimeoutTime" BU_SG_REL_ BedienDisp_vo SG_ 1413 SI_NWDF 5000;
BA_REL_ "GenSigTimeoutTime" BU_SG_REL_ BedienDisp_vo SG_ 1413 SI_NWDF_gueltig 5000;
BA_REL_ "GenSigTimeoutTime" BU_SG_REL_ BedienDisp_vo SG_ 976 FT_Tuer_geoeffnet 1000;
BA_REL_ "GenSigTimeoutTime" BU_SG_REL_ BedienSG_hi SG_ 1413 SI_QRS_Mode 5000;
BA_REL_ "GenSigTimeoutTime" BU_SG_REL_ BedienSG_hi SG_ 1413 SI_T_Mode 5000;
BA_REL_ "GenSigTimeoutTime" BU_SG_REL_ BedienSG_hi SG_ 1413 SI_NWDF 5000;
BA_REL_ "GenSigTimeoutTime" BU_SG_REL_ BedienSG_hi SG_ 1413 SI_NWDF_gueltig 5000;
BA_REL_ "GenSigTimeoutTime" BU_SG_REL_ BedienSG_hi SG_ 1413 SI_T_Schutz 5000;
BA_REL_ "GenSigTimeoutTime" BU_SG_REL_ BedienSG_hi SG_ 1413 SI_BUS_03 5000;
BA_REL_ "GenSigTimeoutTime" BU_SG_REL_ BedienSG_hi SG_ 1413 SI_BUS_04 5000;
BA_REL_ "GenSigTimeoutTime" BU_SG_REL_ BedienSG_hi SG_ 1413 SI_BUS_10 5000;
BA_REL_ "GenSigTimeoutTime" BU_SG_REL_ BedienSG_hi SG_ 1413 SI_CAB 5000;
BA_REL_ "GenSigTimeoutTime" BU_SG_REL_ BedienSG_hi SG_ 976 FT_Kisi_li_aktiv 1000;
BA_REL_ "GenSigTimeoutTime" BU_SG_REL_ BedienSG_hi SG_ 976 FT_Kisi_re_aktiv 1000;
BA_REL_ "GenSigTimeoutTime" BU_SG_REL_ BedienSG_hi SG_ 976 FT_Kisi_Fehler 1000;
BA_REL_ "GenSigTimeoutTime" BU_SG_REL_ BedienSG_hi SG_ 975 HBFS_FH_normiert 5000;
BA_REL_ "GenSigTimeoutTime" BU_SG_REL_ BedienSG_hi SG_ 975 HBFS_Seitenrollo_hoch 5000;
BA_REL_ "GenSigTimeoutTime" BU_SG_REL_ BedienSG_hi SG_ 975 HBFS_Seitenrollo_tief 5000;
BA_REL_ "GenSigTimeoutTime" BU_SG_REL_ BedienSG_hi SG_ 975 HBFS_Status_KiSi 5000;
BA_REL_ "GenSigTimeoutTime" BU_SG_REL_ BedienSG_hi SG_ 974 HFS_FH_normiert 5000;
BA_REL_ "GenSigTimeoutTime" BU_SG_REL_ BedienSG_hi SG_ 974 HFS_Seitenrollo_hoch 5000;
BA_REL_ "GenSigTimeoutTime" BU_SG_REL_ BedienSG_hi SG_ 974 HFS_Seitenrollo_tief 5000;
BA_REL_ "GenSigTimeoutTime" BU_SG_REL_ BedienSG_hi SG_ 974 HFS_Status_KiSi 5000;
BA_REL_ "GenSigTimeoutTime" BU_SG_REL_ BedienSG_hi SG_ 1718 UH_Typ 5000;
BA_REL_ "GenSigTimeoutTime" BU_SG_REL_ BedienSG_hi SG_ 1718 UH_DLS 5000;
BA_REL_ "GenSigTimeoutTime" BU_SG_REL_ DDA SG_ 1413 SI_T_Mode 5000;
BA_REL_ "GenSigTimeoutTime" BU_SG_REL_ DDA SG_ 1413 SI_NWDF 5000;
BA_REL_ "GenSigTimeoutTime" BU_SG_REL_ DDA SG_ 1413 SI_NWDF_gueltig 5000;
BA_REL_ "GenSigTimeoutTime" BU_SG_REL_ DDA SG_ 1413 SI_BUS_03 5000;
BA_REL_ "GenSigTimeoutTime" BU_SG_REL_ DDA SG_ 1413 SI_BUS_10 5000;
BA_REL_ "GenSigTimeoutTime" BU_SG_REL_ DDA SG_ 1413 SI_BUS_12 5000;
BA_REL_ "GenSigTimeoutTime" BU_SG_REL_ DDA SG_ 977 BT_FH_Oeffnung 5000;
BA_REL_ "GenSigTimeoutTime" BU_SG_REL_ DDA SG_ 976 FT_FH_Oeffnung 1000;
BA_REL_ "GenSigTimeoutTime" BU_SG_REL_ DDA SG_ 975 HBFS_FH_Oeffnung 5000;
BA_REL_ "GenSigTimeoutTime" BU_SG_REL_ DDA SG_ 974 HFS_FH_Oeffnung 5000;
BA_REL_ "GenSigTimeoutTime" BU_SG_REL_ DDA SG_ 2589283609 UGDO_Channel_1 5000;
BA_REL_ "GenSigTimeoutTime" BU_SG_REL_ DDA SG_ 2589283609 UGDO_Channel_2 5000;
BA_REL_ "GenSigTimeoutTime" BU_SG_REL_ DDA SG_ 2589283609 UGDO_Channel_3 5000;
BA_REL_ "GenSigTimeoutTime" BU_SG_REL_ DDA SG_ 2589283609 UGDO_Channel_4 5000;
BA_REL_ "GenSigTimeoutTime" BU_SG_REL_ DDA SG_ 2589283609 UGDO_Channel_5 5000;
BA_REL_ "GenSigTimeoutTime" BU_SG_REL_ DDA SG_ 2589283609 UGDO_Channel_6 5000;
BA_REL_ "GenSigTimeoutTime" BU_SG_REL_ DDA SG_ 2589283609 UGDO_Channel_7 5000;
BA_REL_ "GenSigTimeoutTime" BU_SG_REL_ DDA SG_ 2589283609 UGDO_Channel_8 5000;
BA_REL_ "GenSigTimeoutTime" BU_SG_REL_ DDA SG_ 2589283609 UGDO_Channel_9 5000;
BA_REL_ "GenSigTimeoutTime" BU_SG_REL_ DDA SG_ 2589283609 UGDO_Channel_10 5000;
BA_REL_ "GenSigTimeoutTime" BU_SG_REL_ DDA SG_ 2589283609 UGDO_Channel_11 5000;
BA_REL_ "GenSigTimeoutTime" BU_SG_REL_ DDA SG_ 2589283609 UGDO_Channel_12 5000;
BA_REL_ "GenSigTimeoutTime" BU_SG_REL_ DDA SG_ 2589283609 UGDO_Channel_13 5000;
BA_REL_ "GenSigTimeoutTime" BU_SG_REL_ DDA SG_ 2589283609 UGDO_Channel_14 5000;
BA_REL_ "GenSigTimeoutTime" BU_SG_REL_ DDA SG_ 2589283609 UGDO_Channel_15 5000;
BA_REL_ "GenSigTimeoutTime" BU_SG_REL_ DDA SG_ 2589283609 UGDO_DoorState 5000;
BA_REL_ "GenSigTimeoutTime" BU_SG_REL_ OTA_FC SG_ 1413 SI_Bus_Identifikation 5000;
BA_REL_ "GenSigTimeoutTime" BU_SG_REL_ OTA_FC SG_ 1413 SI_CAB 5000;
BA_REL_ "GenSigTimeoutTime" BU_SG_REL_ OTA_FC SG_ 977 BT_Tuer_geoeffnet 5000;
BA_REL_ "GenSigTimeoutTime" BU_SG_REL_ OTA_FC SG_ 977 BT_verriegelt 5000;
BA_REL_ "GenSigTimeoutTime" BU_SG_REL_ OTA_FC SG_ 977 BT_EC_Spiegel_Helligkeit 5000;
BA_REL_ "GenSigTimeoutTime" BU_SG_REL_ OTA_FC SG_ 977 BT_Tuer_Status 5000;
BA_REL_ "GenSigTimeoutTime" BU_SG_REL_ OTA_FC SG_ 977 BT_FH_Oeffnung 5000;
BA_REL_ "GenSigTimeoutTime" BU_SG_REL_ OTA_FC SG_ 977 BT_Zuziehhilfe_aktiv 5000;
BA_REL_ "GenSigTimeoutTime" BU_SG_REL_ OTA_FC SG_ 977 BT_SP_Heizung_Status 5000;
BA_REL_ "GenSigTimeoutTime" BU_SG_REL_ OTA_FC SG_ 977 BT_FH_Pos_oben 5000;
BA_REL_ "GenSigTimeoutTime" BU_SG_REL_ OTA_FC SG_ 976 FT_Tuer_geoeffnet 1000;
BA_REL_ "GenSigTimeoutTime" BU_SG_REL_ OTA_FC SG_ 976 FT_verriegelt 1000;
BA_REL_ "GenSigTimeoutTime" BU_SG_REL_ OTA_FC SG_ 976 FT_HD_Taste 1000;
BA_REL_ "GenSigTimeoutTime" BU_SG_REL_ OTA_FC SG_ 976 FT_TD_Taste 1000;
BA_REL_ "GenSigTimeoutTime" BU_SG_REL_ OTA_FC SG_ 976 FT_Sp_Heizung_Anf 1000;
BA_REL_ "GenSigTimeoutTime" BU_SG_REL_ OTA_FC SG_ 976 FT_FH_Oeffnung 1000;
BA_REL_ "GenSigTimeoutTime" BU_SG_REL_ OTA_FC SG_ 976 FT_Zuziehhilfe_aktiv 1000;
BA_REL_ "GenSigTimeoutTime" BU_SG_REL_ OTA_FC SG_ 976 FT_SP_lr_aktiv 1000;
BA_REL_ "GenSigTimeoutTime" BU_SG_REL_ OTA_FC SG_ 976 FT_SP_ht_aktiv 1000;
BA_REL_ "GenSigTimeoutTime" BU_SG_REL_ OTA_FC SG_ 976 FT_SP_Heizung_Status 1000;
BA_REL_ "GenSigTimeoutTime" BU_SG_REL_ OTA_FC SG_ 976 FT_FH_Pos_oben 1000;
BA_REL_ "GenSigTimeoutTime" BU_SG_REL_ OTA_FC SG_ 997 FT_Tuer_Status 1000;
BA_REL_ "GenSigTimeoutTime" BU_SG_REL_ OTA_FC SG_ 975 HBFS_Tuer_geoeffnet 5000;
BA_REL_ "GenSigTimeoutTime" BU_SG_REL_ OTA_FC SG_ 975 HBFS_Tuer_Status 5000;
BA_REL_ "GenSigTimeoutTime" BU_SG_REL_ OTA_FC SG_ 975 HBFS_FH_Oeffnung 5000;
BA_REL_ "GenSigTimeoutTime" BU_SG_REL_ OTA_FC SG_ 975 HBFS_Zuziehhilfe_aktiv 5000;
BA_REL_ "GenSigTimeoutTime" BU_SG_REL_ OTA_FC SG_ 974 HFS_Tuer_geoeffnet 5000;
BA_REL_ "GenSigTimeoutTime" BU_SG_REL_ OTA_FC SG_ 974 HFS_Tuer_Status 5000;
BA_REL_ "GenSigTimeoutTime" BU_SG_REL_ OTA_FC SG_ 974 HFS_FH_Oeffnung 5000;
BA_REL_ "GenSigTimeoutTime" BU_SG_REL_ OTA_FC SG_ 974 HFS_Zuziehhilfe_aktiv 5000;
BA_REL_ "GenSigTimeoutTime" BU_SG_REL_ OTA_FC SG_ 346 TSK_vMax_aktuell 1000;
BA_REL_ "GenSigTimeoutTime" BU_SG_REL_ ZR_High SG_ 1650 STH_ZZ_Monat 5000;
BA_REL_ "GenSigTimeoutTime" BU_SG_REL_ ZR_High SG_ 1650 STH_ZZ_Tag 5000;
BA_REL_ "GenSigTimeoutTime" BU_SG_REL_ ZR_High SG_ 1650 STH_ZZ_Betriebsmodus 5000;
BA_REL_ "GenSigTimeoutTime" BU_SG_REL_ ZR_High SG_ 1650 STH_ZZ_Minute 5000;
BA_REL_ "GenSigTimeoutTime" BU_SG_REL_ ZR_High SG_ 1650 STH_ZZ_Status_Timer 5000;
BA_REL_ "GenSigTimeoutTime" BU_SG_REL_ ZR_High SG_ 1650 STH_ZZ_Stunde 5000;
BA_REL_ "GenSigTimeoutTime" BU_SG_REL_ ZR_High SG_ 1650 STH_ZZ_Betriebsdauer 5000;
BA_REL_ "GenSigTimeoutTime" BU_SG_REL_ ZR_High SG_ 516 STP_Status 5000;
BA_REL_ "GenSigTimeoutTime" BU_SG_REL_ ZR_High SG_ 516 STP_Abschaltbedingung 5000;
BA_REL_ "GenSigTimeoutTime" BU_SG_REL_ ZR_High SG_ 516 STP_Freiraum 5000;
BA_REL_ "GenSigTimeoutTime" BU_SG_REL_ ZR_High SG_ 666 STP_Texte_ESK 4000;
BA_REL_ "GenSigTimeoutTime" BU_SG_REL_ ZR_High SG_ 666 STP_Status_Anzeige 4000;
BA_REL_ "GenSigTimeoutTime" BU_SG_REL_ ZR_High SG_ 666 STP_Nebenspur_links_ZA 4000;
BA_REL_ "GenSigTimeoutTime" BU_SG_REL_ ZR_High SG_ 666 STP_Nebenspur_rechts_ZA 4000;
BA_REL_ "GenSigTimeoutTime" BU_SG_REL_ ZR_High SG_ 666 STP_FBM_links_ZA 4000;
BA_REL_ "GenSigTimeoutTime" BU_SG_REL_ ZR_High SG_ 666 STP_Egokolonne_ZA 4000;
BA_REL_ "GenSigTimeoutTime" BU_SG_REL_ ZR_High SG_ 666 STP_FBM_rechts_ZA 4000;
BA_REL_ "GenSigTimeoutTime" BU_SG_REL_ ZR_High SG_ 666 STP_FAS_Fkt_Status 4000;
BA_REL_ "GenSigTimeoutTime" BU_SG_REL_ ZR_High SG_ 666 STP_Texte_ZA 4000;
BA_REL_ "GenSigTimeoutTime" BU_SG_REL_ ZR_High SG_ 666 STP_Texte_AV 4000;
BA_REL_ "GenSigTimeoutTime" BU_SG_REL_ ZR_High SG_ 666 STP_Texte 4000;
BA_REL_ "GenSigTimeoutTime" BU_SG_REL_ ZR_High SG_ 1172 STS_Door_Lock 2000;
BA_REL_ "GenSigTimeoutTime" BU_SG_REL_ ZR_High SG_ 1172 STS_Anlassersperre 2000;
BA_REL_ "GenSigTimeoutTime" BU_SG_REL_ ZR_High SG_ 1172 STS_Typencodierung 2000;
BA_REL_ "GenSigTimeoutTime" BU_SG_REL_ ZR_High SG_ 1172 STS_Spiegel_Anklappen 2000;
BA_REL_ "GenSigTimeoutTime" BU_SG_REL_ ZR_High SG_ 783 SWA_Anzeigen 2000;
BA_REL_ "GenSigTimeoutTime" BU_SG_REL_ ZR_High SG_ 783 SWA_rel_Fehler 2000;
BA_REL_ "GenSigTimeoutTime" BU_SG_REL_ ZR_High SG_ 783 SWA_Sta_aktiv 2000;
BA_REL_ "GenSigTimeoutTime" BU_SG_REL_ ZR_High SG_ 783 SWA_Sta_passiv 2000;
BA_REL_ "GenSigTimeoutTime" BU_SG_REL_ ZR_High SG_ 783 SWA_FT_RueckLED 2000;
BA_REL_ "GenSigTimeoutTime" BU_SG_REL_ ZR_High SG_ 783 ASW_Status 2000;
BA_REL_ "GenSigTimeoutTime" BU_SG_REL_ ZR_High SG_ 783 SWA_Standziele_li 2000;
BA_REL_ "GenSigTimeoutTime" BU_SG_REL_ ZR_High SG_ 783 SWA_Infostufe_SWA_li 2000;
BA_REL_ "GenSigTimeoutTime" BU_SG_REL_ ZR_High SG_ 783 SWA_Warnung_SWA_li 2000;
BA_REL_ "GenSigTimeoutTime" BU_SG_REL_ ZR_High SG_ 783 ASW_Warnung_FS 2000;
BA_REL_ "GenSigTimeoutTime" BU_SG_REL_ ZR_High SG_ 783 ASW_Warnung_BFS 2000;
BA_REL_ "GenSigTimeoutTime" BU_SG_REL_ ZR_High SG_ 783 ASW_Kombitexte 2000;
BA_REL_ "GenSigTimeoutTime" BU_SG_REL_ ZR_High SG_ 783 ASW_Modus 2000;
BA_REL_ "GenSigTimeoutTime" BU_SG_REL_ ZR_High SG_ 783 SWA_Modus 2000;
BA_REL_ "GenSigTimeoutTime" BU_SG_REL_ ZR_High SG_ 783 SWA_Infostufe_SWA_re 2000;
BA_REL_ "GenSigTimeoutTime" BU_SG_REL_ ZR_High SG_ 783 SWA_Warnung_SWA_re 2000;
BA_REL_ "GenSigTimeoutTime" BU_SG_REL_ ZR_High SG_ 783 Heckradar_Kombitexte 2000;
BA_REL_ "GenSigTimeoutTime" BU_SG_REL_ ZR_High SG_ 783 RCTA_Kombitexte 2000;
BA_REL_ "GenSigTimeoutTime" BU_SG_REL_ ZR_High SG_ 1413 SI_Diagnose_Aktiv 5000;
BA_REL_ "GenSigTimeoutTime" BU_SG_REL_ ZR_High SG_ 1413 SI_QRS_Mode 5000;
BA_REL_ "GenSigTimeoutTime" BU_SG_REL_ ZR_High SG_ 1413 SI_T_Mode 5000;
BA_REL_ "GenSigTimeoutTime" BU_SG_REL_ ZR_High SG_ 1413 SI_NWDF 5000;
BA_REL_ "GenSigTimeoutTime" BU_SG_REL_ ZR_High SG_ 1413 SI_NWDF_gueltig 5000;
BA_REL_ "GenSigTimeoutTime" BU_SG_REL_ ZR_High SG_ 1413 SI_BUS_01 5000;
BA_REL_ "GenSigTimeoutTime" BU_SG_REL_ ZR_High SG_ 1413 SI_BUS_02 5000;
BA_REL_ "GenSigTimeoutTime" BU_SG_REL_ ZR_High SG_ 1413 SI_BUS_03 5000;
BA_REL_ "GenSigTimeoutTime" BU_SG_REL_ ZR_High SG_ 1413 SI_BUS_06 5000;
BA_REL_ "GenSigTimeoutTime" BU_SG_REL_ ZR_High SG_ 1413 SI_BUS_07 5000;
BA_REL_ "GenSigTimeoutTime" BU_SG_REL_ ZR_High SG_ 1413 SI_BUS_08 5000;
BA_REL_ "GenSigTimeoutTime" BU_SG_REL_ ZR_High SG_ 1447 TM_Spiegel_Anklappen 5000;
BA_REL_ "GenSigTimeoutTime" BU_SG_REL_ ZR_High SG_ 1447 TM_Nur_Hupen 5000;
BA_REL_ "GenSigTimeoutTime" BU_SG_REL_ ZR_High SG_ 1447 TM_Warnblinken 5000;
BA_REL_ "GenSigTimeoutTime" BU_SG_REL_ ZR_High SG_ 1447 TM_Panik_Alarm 5000;
BA_REL_ "GenSigTimeoutTime" BU_SG_REL_ ZR_High SG_ 977 BT_Tuer_geoeffnet 5000;
BA_REL_ "GenSigTimeoutTime" BU_SG_REL_ ZR_High SG_ 977 BT_verriegelt 5000;
BA_REL_ "GenSigTimeoutTime" BU_SG_REL_ ZR_High SG_ 977 BT_gesafet 5000;
BA_REL_ "GenSigTimeoutTime" BU_SG_REL_ ZR_High SG_ 977 BT_Schluesselschalter_auf 5000;
BA_REL_ "GenSigTimeoutTime" BU_SG_REL_ ZR_High SG_ 977 BT_Schluesselschalter_zu 5000;
BA_REL_ "GenSigTimeoutTime" BU_SG_REL_ ZR_High SG_ 977 BT_Unlock_Taster 5000;
BA_REL_ "GenSigTimeoutTime" BU_SG_REL_ ZR_High SG_ 977 BT_Lock_Taster 5000;
BA_REL_ "GenSigTimeoutTime" BU_SG_REL_ ZR_High SG_ 977 BT_TAG_betaetigt 5000;
BA_REL_ "GenSigTimeoutTime" BU_SG_REL_ ZR_High SG_ 977 BT_TIG_betaetigt 5000;
BA_REL_ "GenSigTimeoutTime" BU_SG_REL_ ZR_High SG_ 977 BT_EC_Spiegel_Helligkeit 5000;
BA_REL_ "GenSigTimeoutTime" BU_SG_REL_ ZR_High SG_ 977 BT_Sp_Heizung_Anf 5000;
BA_REL_ "GenSigTimeoutTime" BU_SG_REL_ ZR_High SG_ 977 BT_Tuer_Status 5000;
BA_REL_ "GenSigTimeoutTime" BU_SG_REL_ ZR_High SG_ 977 BT_TSG_hinten_verbaut 5000;
BA_REL_ "GenSigTimeoutTime" BU_SG_REL_ ZR_High SG_ 977 BT_Sp_Blk_def 5000;
BA_REL_ "GenSigTimeoutTime" BU_SG_REL_ ZR_High SG_ 977 BT_FH_S_ManHoch 5000;
BA_REL_ "GenSigTimeoutTime" BU_SG_REL_ ZR_High SG_ 977 BT_FH_S_AutoHoch 5000;
BA_REL_ "GenSigTimeoutTime" BU_SG_REL_ ZR_High SG_ 977 BT_FH_S_ManTief 5000;
BA_REL_ "GenSigTimeoutTime" BU_SG_REL_ ZR_High SG_ 977 BT_FH_S_AutoTief 5000;
BA_REL_ "GenSigTimeoutTime" BU_SG_REL_ ZR_High SG_ 977 BT_FH_Oeffnung 5000;
BA_REL_ "GenSigTimeoutTime" BU_SG_REL_ ZR_High SG_ 977 BT_FH_Bew_hoch 5000;
BA_REL_ "GenSigTimeoutTime" BU_SG_REL_ ZR_High SG_ 977 BT_FH_Bew_tief 5000;
BA_REL_ "GenSigTimeoutTime" BU_SG_REL_ ZR_High SG_ 977 BT_FH_Fang 5000;
BA_REL_ "GenSigTimeoutTime" BU_SG_REL_ ZR_High SG_ 977 BT_FH_Block 5000;
BA_REL_ "GenSigTimeoutTime" BU_SG_REL_ ZR_High SG_ 977 BT_FH_Thermo 5000;
BA_REL_ "GenSigTimeoutTime" BU_SG_REL_ ZR_High SG_ 977 BT_Kisi_Fehler 5000;
BA_REL_ "GenSigTimeoutTime" BU_SG_REL_ ZR_High SG_ 977 BT_Schliesstaster 5000;
BA_REL_ "GenSigTimeoutTime" BU_SG_REL_ ZR_High SG_ 977 BT_Zuziehhilfe_aktiv 5000;
BA_REL_ "GenSigTimeoutTime" BU_SG_REL_ ZR_High SG_ 977 BT_SP_ausgerastet 5000;
BA_REL_ "GenSigTimeoutTime" BU_SG_REL_ ZR_High SG_ 977 BT_SP_lr_aktiv 5000;
BA_REL_ "GenSigTimeoutTime" BU_SG_REL_ ZR_High SG_ 977 BT_SP_ht_aktiv 5000;
BA_REL_ "GenSigTimeoutTime" BU_SG_REL_ ZR_High SG_ 977 BT_Oben_Block_erw 5000;
BA_REL_ "GenSigTimeoutTime" BU_SG_REL_ ZR_High SG_ 977 BT_Unten_Block_erw 5000;
BA_REL_ "GenSigTimeoutTime" BU_SG_REL_ ZR_High SG_ 977 BT_SP_Heizung_Status 5000;
BA_REL_ "GenSigTimeoutTime" BU_SG_REL_ ZR_High SG_ 977 ASW_Warnung_aktiv_BFS 5000;
BA_REL_ "GenSigTimeoutTime" BU_SG_REL_ ZR_High SG_ 977 BT_FH_Pos_oben 5000;
BA_REL_ "GenSigTimeoutTime" BU_SG_REL_ ZR_High SG_ 977 BT_Tuerschloss_defekt 5000;
BA_REL_ "GenSigTimeoutTime" BU_SG_REL_ ZR_High SG_ 977 BT_Lock_Taster_inv 5000;
BA_REL_ "GenSigTimeoutTime" BU_SG_REL_ ZR_High SG_ 977 BT_Schluesselschalter_zu_inv 5000;
BA_REL_ "GenSigTimeoutTime" BU_SG_REL_ ZR_High SG_ 977 BT_SWA_HMI_defekt 5000;
BA_REL_ "GenSigTimeoutTime" BU_SG_REL_ ZR_High SG_ 977 BT_ASW_HMI_defekt 5000;
BA_REL_ "GenSigTimeoutTime" BU_SG_REL_ ZR_High SG_ 1451 TSG_FlHz_BFS_NTC_A 5000;
BA_REL_ "GenSigTimeoutTime" BU_SG_REL_ ZR_High SG_ 1451 TSG_FlHz_BFS_FnAbbruchHzKreis_A 5000;
BA_REL_ "GenSigTimeoutTime" BU_SG_REL_ ZR_High SG_ 1451 TSG_FlHz_BFS_NTC_B 5000;
BA_REL_ "GenSigTimeoutTime" BU_SG_REL_ ZR_High SG_ 1451 TSG_FlHz_BFS_FnAbbruchHzKreis_B 5000;
BA_REL_ "GenSigTimeoutTime" BU_SG_REL_ ZR_High SG_ 976 FT_Tuer_geoeffnet 1000;
BA_REL_ "GenSigTimeoutTime" BU_SG_REL_ ZR_High SG_ 976 FT_verriegelt 1000;
BA_REL_ "GenSigTimeoutTime" BU_SG_REL_ ZR_High SG_ 976 FT_gesafet 1000;
BA_REL_ "GenSigTimeoutTime" BU_SG_REL_ ZR_High SG_ 976 FT_Schluesselschalter_auf 1000;
BA_REL_ "GenSigTimeoutTime" BU_SG_REL_ ZR_High SG_ 976 FT_Schluesselschalter_zu 1000;
BA_REL_ "GenSigTimeoutTime" BU_SG_REL_ ZR_High SG_ 976 FT_Unlock_Taster 1000;
BA_REL_ "GenSigTimeoutTime" BU_SG_REL_ ZR_High SG_ 976 FT_Lock_Taster 1000;
BA_REL_ "GenSigTimeoutTime" BU_SG_REL_ ZR_High SG_ 976 FT_Sperrklinke 1000;
BA_REL_ "GenSigTimeoutTime" BU_SG_REL_ ZR_High SG_ 976 FT_TAG_betaetigt 1000;
BA_REL_ "GenSigTimeoutTime" BU_SG_REL_ ZR_High SG_ 976 FT_TIG_betaetigt 1000;
BA_REL_ "GenSigTimeoutTime" BU_SG_REL_ ZR_High SG_ 976 FT_IRUE_Taste 1000;
BA_REL_ "GenSigTimeoutTime" BU_SG_REL_ ZR_High SG_ 976 FT_HD_Taste 1000;
BA_REL_ "GenSigTimeoutTime" BU_SG_REL_ ZR_High SG_ 976 FT_TD_Taste_Fehler 1000;
BA_REL_ "GenSigTimeoutTime" BU_SG_REL_ ZR_High SG_ 976 FT_TD_Taste 1000;
BA_REL_ "GenSigTimeoutTime" BU_SG_REL_ ZR_High SG_ 976 FT_Sp_Heizung_Anf 1000;
BA_REL_ "GenSigTimeoutTime" BU_SG_REL_ ZR_High SG_ 976 FT_HD_Taste_2 1000;
BA_REL_ "GenSigTimeoutTime" BU_SG_REL_ ZR_High SG_ 976 FT_TSG_hinten_verbaut 1000;
BA_REL_ "GenSigTimeoutTime" BU_SG_REL_ ZR_High SG_ 976 FT_Sp_Blk_def 1000;
BA_REL_ "GenSigTimeoutTime" BU_SG_REL_ ZR_High SG_ 976 FT_FH_S_ManHoch 1000;
BA_REL_ "GenSigTimeoutTime" BU_SG_REL_ ZR_High SG_ 976 FT_FH_S_AutoHoch 1000;
BA_REL_ "GenSigTimeoutTime" BU_SG_REL_ ZR_High SG_ 976 FT_FH_S_ManTief 1000;
BA_REL_ "GenSigTimeoutTime" BU_SG_REL_ ZR_High SG_ 976 FT_FH_S_AutoTief 1000;
BA_REL_ "GenSigTimeoutTime" BU_SG_REL_ ZR_High SG_ 976 FT_FH_Oeffnung 1000;
BA_REL_ "GenSigTimeoutTime" BU_SG_REL_ ZR_High SG_ 976 FT_FH_Bew_hoch 1000;
BA_REL_ "GenSigTimeoutTime" BU_SG_REL_ ZR_High SG_ 976 FT_FH_Bew_tief 1000;
BA_REL_ "GenSigTimeoutTime" BU_SG_REL_ ZR_High SG_ 976 FT_FH_Fang 1000;
BA_REL_ "GenSigTimeoutTime" BU_SG_REL_ ZR_High SG_ 976 FT_FH_Block 1000;
BA_REL_ "GenSigTimeoutTime" BU_SG_REL_ ZR_High SG_ 976 FT_FH_Thermo 1000;
BA_REL_ "GenSigTimeoutTime" BU_SG_REL_ ZR_High SG_ 976 FT_UEKB_aktiviert 1000;
BA_REL_ "GenSigTimeoutTime" BU_SG_REL_ ZR_High SG_ 976 ASW_HMI_defekt 1000;
BA_REL_ "GenSigTimeoutTime" BU_SG_REL_ ZR_High SG_ 976 FT_Schliesstaster 1000;
BA_REL_ "GenSigTimeoutTime" BU_SG_REL_ ZR_High SG_ 976 FT_Zuziehhilfe_aktiv 1000;
BA_REL_ "GenSigTimeoutTime" BU_SG_REL_ ZR_High SG_ 976 FT_SP_ausgerastet 1000;
BA_REL_ "GenSigTimeoutTime" BU_SG_REL_ ZR_High SG_ 976 FT_SP_lr_aktiv 1000;
BA_REL_ "GenSigTimeoutTime" BU_SG_REL_ ZR_High SG_ 976 FT_SP_ht_aktiv 1000;
BA_REL_ "GenSigTimeoutTime" BU_SG_REL_ ZR_High SG_ 976 FT_Oben_Block_erw 1000;
BA_REL_ "GenSigTimeoutTime" BU_SG_REL_ ZR_High SG_ 976 FT_Unten_Block_erw 1000;
BA_REL_ "GenSigTimeoutTime" BU_SG_REL_ ZR_High SG_ 976 FT_Kisi_li_aktiv 1000;
BA_REL_ "GenSigTimeoutTime" BU_SG_REL_ ZR_High SG_ 976 FT_Kisi_re_aktiv 1000;
BA_REL_ "GenSigTimeoutTime" BU_SG_REL_ ZR_High SG_ 976 FT_Kisi_Taster_li 1000;
BA_REL_ "GenSigTimeoutTime" BU_SG_REL_ ZR_High SG_ 976 FT_Kisi_Taster_re 1000;
BA_REL_ "GenSigTimeoutTime" BU_SG_REL_ ZR_High SG_ 976 FT_BFS_Fond_Freigabe 1000;
BA_REL_ "GenSigTimeoutTime" BU_SG_REL_ ZR_High SG_ 976 FT_Kisi_Fehler 1000;
BA_REL_ "GenSigTimeoutTime" BU_SG_REL_ ZR_High SG_ 976 FT_Daemmglas 1000;
BA_REL_ "GenSigTimeoutTime" BU_SG_REL_ ZR_High SG_ 976 FT_SP_Heizung_Status 1000;
BA_REL_ "GenSigTimeoutTime" BU_SG_REL_ ZR_High SG_ 976 ASW_Warnung_aktiv_FS 1000;
BA_REL_ "GenSigTimeoutTime" BU_SG_REL_ ZR_High SG_ 976 FT_FH_Pos_oben 1000;
BA_REL_ "GenSigTimeoutTime" BU_SG_REL_ ZR_High SG_ 976 FT_Tuerschloss_defekt 1000;
BA_REL_ "GenSigTimeoutTime" BU_SG_REL_ ZR_High SG_ 976 FT_SWA_Taster 1000;
BA_REL_ "GenSigTimeoutTime" BU_SG_REL_ ZR_High SG_ 976 SWA_HMI_Diagnose 1000;
BA_REL_ "GenSigTimeoutTime" BU_SG_REL_ ZR_High SG_ 997 FT_Tuer_Status 1000;
BA_REL_ "GenSigTimeoutTime" BU_SG_REL_ ZR_High SG_ 997 FT_Tuer_Status_QBit 1000;
BA_REL_ "GenSigTimeoutTime" BU_SG_REL_ ZR_High SG_ 997 FT_Lock_Taster_02 1000;
BA_REL_ "GenSigTimeoutTime" BU_SG_REL_ ZR_High SG_ 997 FT_Schluesselschalter_zu_02 1000;
BA_REL_ "GenSigTimeoutTime" BU_SG_REL_ ZR_High SG_ 997 FT_BFS_Tuer_Status 1000;
BA_REL_ "GenSigTimeoutTime" BU_SG_REL_ ZR_High SG_ 997 FT_HBFS_Tuer_Status 1000;
BA_REL_ "GenSigTimeoutTime" BU_SG_REL_ ZR_High SG_ 997 FT_HFS_Tuer_Status 1000;
BA_REL_ "GenSigTimeoutTime" BU_SG_REL_ ZR_High SG_ 997 FT_Kisi_Taster_li_02 1000;
BA_REL_ "GenSigTimeoutTime" BU_SG_REL_ ZR_High SG_ 997 FT_Kisi_Taster_re_02 1000;
BA_REL_ "GenSigTimeoutTime" BU_SG_REL_ ZR_High SG_ 997 FT_TD_Taste_Status 1000;
BA_REL_ "GenSigTimeoutTime" BU_SG_REL_ ZR_High SG_ 1449 TSG_FlHz_FS_NTC_A 5000;
BA_REL_ "GenSigTimeoutTime" BU_SG_REL_ ZR_High SG_ 1449 TSG_FlHz_FS_FnAbbruchHzKreis_A 5000;
BA_REL_ "GenSigTimeoutTime" BU_SG_REL_ ZR_High SG_ 1449 TSG_FlHz_FS_NTC_B 5000;
BA_REL_ "GenSigTimeoutTime" BU_SG_REL_ ZR_High SG_ 1449 TSG_FlHz_FS_FnAbbruchHzKreis_B 5000;
BA_REL_ "GenSigTimeoutTime" BU_SG_REL_ ZR_High SG_ 975 HBFS_Tuer_geoeffnet 5000;
BA_REL_ "GenSigTimeoutTime" BU_SG_REL_ ZR_High SG_ 975 HBFS_verriegelt 5000;
BA_REL_ "GenSigTimeoutTime" BU_SG_REL_ ZR_High SG_ 975 HBFS_gesafet 5000;
BA_REL_ "GenSigTimeoutTime" BU_SG_REL_ ZR_High SG_ 975 HBFS_Heckrollotaster_betaetigt 5000;
BA_REL_ "GenSigTimeoutTime" BU_SG_REL_ ZR_High SG_ 975 HBFS_Tuerschloss_defekt 5000;
BA_REL_ "GenSigTimeoutTime" BU_SG_REL_ ZR_High SG_ 975 HBFS_Unlock_Taster 5000;
BA_REL_ "GenSigTimeoutTime" BU_SG_REL_ ZR_High SG_ 975 HBFS_Lock_Taster 5000;
BA_REL_ "GenSigTimeoutTime" BU_SG_REL_ ZR_High SG_ 975 HBFS_Sperrklinke 5000;
BA_REL_ "GenSigTimeoutTime" BU_SG_REL_ ZR_High SG_ 975 HBFS_TAG_betaetigt 5000;
BA_REL_ "GenSigTimeoutTime" BU_SG_REL_ ZR_High SG_ 975 HBFS_TIG_betaetigt 5000;
BA_REL_ "GenSigTimeoutTime" BU_SG_REL_ ZR_High SG_ 975 HBFS_FH_S_HFS_AutoHoch 5000;
BA_REL_ "GenSigTimeoutTime" BU_SG_REL_ ZR_High SG_ 975 HBFS_FH_S_HFS_AutoTief 5000;
BA_REL_ "GenSigTimeoutTime" BU_SG_REL_ ZR_High SG_ 975 HBFS_FH_S_HFS_ManHoch 5000;
BA_REL_ "GenSigTimeoutTime" BU_SG_REL_ ZR_High SG_ 975 HBFS_FH_S_HFS_ManTief 5000;
BA_REL_ "GenSigTimeoutTime" BU_SG_REL_ ZR_High SG_ 975 HBFS_Tuer_Status 5000;
BA_REL_ "GenSigTimeoutTime" BU_SG_REL_ ZR_High SG_ 975 HBFS_SAD_Schalter 5000;
BA_REL_ "GenSigTimeoutTime" BU_SG_REL_ ZR_High SG_ 975 HBFS_FH_S_ManHoch 5000;
BA_REL_ "GenSigTimeoutTime" BU_SG_REL_ ZR_High SG_ 975 HBFS_FH_S_AutoHoch 5000;
BA_REL_ "GenSigTimeoutTime" BU_SG_REL_ ZR_High SG_ 975 HBFS_FH_S_ManTief 5000;
BA_REL_ "GenSigTimeoutTime" BU_SG_REL_ ZR_High SG_ 975 HBFS_FH_S_AutoTief 5000;
BA_REL_ "GenSigTimeoutTime" BU_SG_REL_ ZR_High SG_ 975 HBFS_FH_Oeffnung 5000;
BA_REL_ "GenSigTimeoutTime" BU_SG_REL_ ZR_High SG_ 975 HBFS_FH_Bew_hoch 5000;
BA_REL_ "GenSigTimeoutTime" BU_SG_REL_ ZR_High SG_ 975 HBFS_FH_Bew_tief 5000;
BA_REL_ "GenSigTimeoutTime" BU_SG_REL_ ZR_High SG_ 975 HBFS_FH_Block 5000;
BA_REL_ "GenSigTimeoutTime" BU_SG_REL_ ZR_High SG_ 975 HBFS_FH_Thermo 5000;
BA_REL_ "GenSigTimeoutTime" BU_SG_REL_ ZR_High SG_ 975 HBFS_UEKB_aktiviert 5000;
BA_REL_ "GenSigTimeoutTime" BU_SG_REL_ ZR_High SG_ 975 HBFS_FH_normiert 5000;
BA_REL_ "GenSigTimeoutTime" BU_SG_REL_ ZR_High SG_ 975 ASW_Warnung_aktiv_HBFS 5000;
BA_REL_ "GenSigTimeoutTime" BU_SG_REL_ ZR_High SG_ 975 HBFS_Zuziehhilfe_aktiv 5000;
BA_REL_ "GenSigTimeoutTime" BU_SG_REL_ ZR_High SG_ 975 HBFS_Seitenrollo_hoch 5000;
BA_REL_ "GenSigTimeoutTime" BU_SG_REL_ ZR_High SG_ 975 HBFS_Seitenrollo_tief 5000;
BA_REL_ "GenSigTimeoutTime" BU_SG_REL_ ZR_High SG_ 975 HBFS_Status_KiSi 5000;
BA_REL_ "GenSigTimeoutTime" BU_SG_REL_ ZR_High SG_ 975 SSR_HBFS_Pos_Unten 5000;
BA_REL_ "GenSigTimeoutTime" BU_SG_REL_ ZR_High SG_ 975 HBFS_Oben_Block_erw 5000;
BA_REL_ "GenSigTimeoutTime" BU_SG_REL_ ZR_High SG_ 975 HBFS_Unten_Block_erw 5000;
BA_REL_ "GenSigTimeoutTime" BU_SG_REL_ ZR_High SG_ 975 MTHBFS_M_Taste 5000;
BA_REL_ "GenSigTimeoutTime" BU_SG_REL_ ZR_High SG_ 975 MTHBFS_Pos1 5000;
BA_REL_ "GenSigTimeoutTime" BU_SG_REL_ ZR_High SG_ 975 MTHBFS_Pos2 5000;
BA_REL_ "GenSigTimeoutTime" BU_SG_REL_ ZR_High SG_ 975 MTHBFS_Pos3 5000;
BA_REL_ "GenSigTimeoutTime" BU_SG_REL_ ZR_High SG_ 975 HBFS_MRollo_Schalter 5000;
BA_REL_ "GenSigTimeoutTime" BU_SG_REL_ ZR_High SG_ 975 HBFS_Lock_Taster_inv 5000;
BA_REL_ "GenSigTimeoutTime" BU_SG_REL_ ZR_High SG_ 975 HBFS_Status_KiSi_inv 5000;
BA_REL_ "GenSigTimeoutTime" BU_SG_REL_ ZR_High SG_ 1457 TSG_FlHz_HBFS_NTC_A 5000;
BA_REL_ "GenSigTimeoutTime" BU_SG_REL_ ZR_High SG_ 1457 TSG_FlHz_HBFS_FnAbbruchHzKreis_A 5000;
BA_REL_ "GenSigTimeoutTime" BU_SG_REL_ ZR_High SG_ 1457 TSG_FlHz_HBFS_NTC_B 5000;
BA_REL_ "GenSigTimeoutTime" BU_SG_REL_ ZR_High SG_ 1457 TSG_FlHz_HBFS_FnAbbruchHzKreis_B 5000;
BA_REL_ "GenSigTimeoutTime" BU_SG_REL_ ZR_High SG_ 974 HFS_Tuer_geoeffnet 5000;
BA_REL_ "GenSigTimeoutTime" BU_SG_REL_ ZR_High SG_ 974 HFS_verriegelt 5000;
BA_REL_ "GenSigTimeoutTime" BU_SG_REL_ ZR_High SG_ 974 HFS_gesafet 5000;
BA_REL_ "GenSigTimeoutTime" BU_SG_REL_ ZR_High SG_ 974 HFS_Heckrollotaster_betaetigt 5000;
BA_REL_ "GenSigTimeoutTime" BU_SG_REL_ ZR_High SG_ 974 HFS_Tuerschloss_defekt 5000;
BA_REL_ "GenSigTimeoutTime" BU_SG_REL_ ZR_High SG_ 974 HFS_Unlock_Taster 5000;
BA_REL_ "GenSigTimeoutTime" BU_SG_REL_ ZR_High SG_ 974 HFS_Lock_Taster 5000;
BA_REL_ "GenSigTimeoutTime" BU_SG_REL_ ZR_High SG_ 974 HFS_Sperrklinke 5000;
BA_REL_ "GenSigTimeoutTime" BU_SG_REL_ ZR_High SG_ 974 HFS_TAG_betaetigt 5000;
BA_REL_ "GenSigTimeoutTime" BU_SG_REL_ ZR_High SG_ 974 HFS_TIG_betaetigt 5000;
BA_REL_ "GenSigTimeoutTime" BU_SG_REL_ ZR_High SG_ 974 HFS_FH_S_HBFS_AutoHoch 5000;
BA_REL_ "GenSigTimeoutTime" BU_SG_REL_ ZR_High SG_ 974 HFS_FH_S_HBFS_AutoTief 5000;
BA_REL_ "GenSigTimeoutTime" BU_SG_REL_ ZR_High SG_ 974 HFS_FH_S_HBFS_ManHoch 5000;
BA_REL_ "GenSigTimeoutTime" BU_SG_REL_ ZR_High SG_ 974 HFS_FH_S_HBFS_ManTief 5000;
BA_REL_ "GenSigTimeoutTime" BU_SG_REL_ ZR_High SG_ 974 HFS_Tuer_Status 5000;
BA_REL_ "GenSigTimeoutTime" BU_SG_REL_ ZR_High SG_ 974 HFS_SAD_Schalter 5000;
BA_REL_ "GenSigTimeoutTime" BU_SG_REL_ ZR_High SG_ 974 HFS_FH_S_ManHoch 5000;
BA_REL_ "GenSigTimeoutTime" BU_SG_REL_ ZR_High SG_ 974 HFS_FH_S_AutoHoch 5000;
BA_REL_ "GenSigTimeoutTime" BU_SG_REL_ ZR_High SG_ 974 HFS_FH_S_ManTief 5000;
BA_REL_ "GenSigTimeoutTime" BU_SG_REL_ ZR_High SG_ 974 HFS_FH_S_AutoTief 5000;
BA_REL_ "GenSigTimeoutTime" BU_SG_REL_ ZR_High SG_ 974 HFS_FH_Oeffnung 5000;
BA_REL_ "GenSigTimeoutTime" BU_SG_REL_ ZR_High SG_ 974 HFS_FH_Bew_hoch 5000;
BA_REL_ "GenSigTimeoutTime" BU_SG_REL_ ZR_High SG_ 974 HFS_FH_Bew_tief 5000;
BA_REL_ "GenSigTimeoutTime" BU_SG_REL_ ZR_High SG_ 974 HFS_FH_Fang 5000;
BA_REL_ "GenSigTimeoutTime" BU_SG_REL_ ZR_High SG_ 974 HFS_FH_Block 5000;
BA_REL_ "GenSigTimeoutTime" BU_SG_REL_ ZR_High SG_ 974 HFS_FH_Thermo 5000;
BA_REL_ "GenSigTimeoutTime" BU_SG_REL_ ZR_High SG_ 974 HFS_UEKB_aktiviert 5000;
BA_REL_ "GenSigTimeoutTime" BU_SG_REL_ ZR_High SG_ 974 HFS_FH_normiert 5000;
BA_REL_ "GenSigTimeoutTime" BU_SG_REL_ ZR_High SG_ 974 ASW_Warnung_aktiv_HFS 5000;
BA_REL_ "GenSigTimeoutTime" BU_SG_REL_ ZR_High SG_ 974 HFS_Zuziehhilfe_aktiv 5000;
BA_REL_ "GenSigTimeoutTime" BU_SG_REL_ ZR_High SG_ 974 HFS_Seitenrollo_hoch 5000;
BA_REL_ "GenSigTimeoutTime" BU_SG_REL_ ZR_High SG_ 974 HFS_Seitenrollo_tief 5000;
BA_REL_ "GenSigTimeoutTime" BU_SG_REL_ ZR_High SG_ 974 HFS_Status_KiSi 5000;
BA_REL_ "GenSigTimeoutTime" BU_SG_REL_ ZR_High SG_ 974 SSR_HFS_Pos_Unten 5000;
BA_REL_ "GenSigTimeoutTime" BU_SG_REL_ ZR_High SG_ 974 HFS_Oben_Block_erw 5000;
BA_REL_ "GenSigTimeoutTime" BU_SG_REL_ ZR_High SG_ 974 HFS_Unten_Block_erw 5000;
BA_REL_ "GenSigTimeoutTime" BU_SG_REL_ ZR_High SG_ 974 MTHFS_M_Taste 5000;
BA_REL_ "GenSigTimeoutTime" BU_SG_REL_ ZR_High SG_ 974 MTHFS_Pos1 5000;
BA_REL_ "GenSigTimeoutTime" BU_SG_REL_ ZR_High SG_ 974 MTHFS_Pos2 5000;
BA_REL_ "GenSigTimeoutTime" BU_SG_REL_ ZR_High SG_ 974 MTHFS_Pos3 5000;
BA_REL_ "GenSigTimeoutTime" BU_SG_REL_ ZR_High SG_ 974 HFS_MRollo_Schalter 5000;
BA_REL_ "GenSigTimeoutTime" BU_SG_REL_ ZR_High SG_ 974 HFS_Lock_Taster_inv 5000;
BA_REL_ "GenSigTimeoutTime" BU_SG_REL_ ZR_High SG_ 1458 TSG_FlHz_HFS_NTC_A 5000;
BA_REL_ "GenSigTimeoutTime" BU_SG_REL_ ZR_High SG_ 1458 TSG_FlHz_HFS_FnAbbruchHzKreis_A 5000;
BA_REL_ "GenSigTimeoutTime" BU_SG_REL_ ZR_High SG_ 1458 TSG_FlHz_HFS_NTC_B 5000;
BA_REL_ "GenSigTimeoutTime" BU_SG_REL_ ZR_High SG_ 1458 TSG_FlHz_HFS_FnAbbruchHzKreis_B 5000;
BA_REL_ "GenSigTimeoutTime" BU_SG_REL_ ZR_High SG_ 346 MO_Anforderung_HMS 1000;
BA_REL_ "GenSigTimeoutTime" BU_SG_REL_ ZR_High SG_ 346 TSK_Status_EA 1000;
BA_REL_ "GenSigTimeoutTime" BU_SG_REL_ ZR_High SG_ 346 TSK_vMax_Fahrerassistenz 1000;
BA_REL_ "GenSigTimeoutTime" BU_SG_REL_ ZR_High SG_ 346 TSK_Einheit_vMax_Fahrerassistenz 1000;
BA_REL_ "GenSigTimeoutTime" BU_SG_REL_ ZR_High SG_ 346 TSK_Status_PLA 1000;
BA_REL_ "GenSigTimeoutTime" BU_SG_REL_ ZR_High SG_ 346 TSK_aktives_System 1000;
BA_REL_ "GenSigTimeoutTime" BU_SG_REL_ ZR_High SG_ 346 TSK_erhoehter_Fahrwiderstand 1000;
BA_REL_ "GenSigTimeoutTime" BU_SG_REL_ ZR_High SG_ 346 TSK_Anf_Antriebsmoment 1000;
BA_REL_ "GenSigTimeoutTime" BU_SG_REL_ ZR_High SG_ 346 TSK_Status_ARA 1000;
BA_REL_ "GenSigTimeoutTime" BU_SG_REL_ ZR_High SG_ 346 TSK_Status_IPA 1000;
BA_REL_ "GenSigTimeoutTime" BU_SG_REL_ ZR_High SG_ 2589283609 UGDO_DoorState 5000;
BA_REL_ "GenSigTimeoutTime" BU_SG_REL_ ZR_High SG_ 1718 UH_Typ 5000;
BA_REL_ "GenSigTimeoutTime" BU_SG_REL_ ZR_High SG_ 1718 UH_DLS 5000;
BA_REL_ "GenSigTimeoutTime" BU_SG_REL_ ZR_LIMU SG_ 516 STP_Status 5000;
BA_REL_ "GenSigTimeoutTime" BU_SG_REL_ ZR_LIMU SG_ 666 STP_Texte_ESK 4000;
BA_REL_ "GenSigTimeoutTime" BU_SG_REL_ ZR_LIMU SG_ 666 STP_Texte_AV 4000;
BA_REL_ "GenSigTimeoutTime" BU_SG_REL_ ZR_LIMU SG_ 666 STP_Texte 4000;
BA_REL_ "GenSigTimeoutTime" BU_SG_REL_ ZR_LIMU SG_ 1413 SI_Sammel_SG_Fehler 5000;
BA_REL_ "GenSigTimeoutTime" BU_SG_REL_ ZR_LIMU SG_ 1413 SI_Diagnose_Aktiv 5000;
BA_REL_ "GenSigTimeoutTime" BU_SG_REL_ ZR_LIMU SG_ 1413 SI_QRS_Mode 5000;
BA_REL_ "GenSigTimeoutTime" BU_SG_REL_ ZR_LIMU SG_ 1413 SI_T_Mode 5000;
BA_REL_ "GenSigTimeoutTime" BU_SG_REL_ ZR_LIMU SG_ 1413 SI_NWDF 5000;
BA_REL_ "GenSigTimeoutTime" BU_SG_REL_ ZR_LIMU SG_ 1413 SI_NWDF_gueltig 5000;
BA_REL_ "GenSigTimeoutTime" BU_SG_REL_ ZR_LIMU SG_ 1413 SI_Sammelfehler 5000;
BA_REL_ "GenSigTimeoutTime" BU_SG_REL_ ZR_LIMU SG_ 1413 SI_T_Schutz 5000;
BA_REL_ "GenSigTimeoutTime" BU_SG_REL_ ZR_LIMU SG_ 1413 SI_BUS_01 5000;
BA_REL_ "GenSigTimeoutTime" BU_SG_REL_ ZR_LIMU SG_ 1413 SI_BUS_02 5000;
BA_REL_ "GenSigTimeoutTime" BU_SG_REL_ ZR_LIMU SG_ 1413 SI_BUS_03 5000;
BA_REL_ "GenSigTimeoutTime" BU_SG_REL_ ZR_LIMU SG_ 1413 SI_BUS_04 5000;
BA_REL_ "GenSigTimeoutTime" BU_SG_REL_ ZR_LIMU SG_ 1413 SI_BUS_05 5000;
BA_REL_ "GenSigTimeoutTime" BU_SG_REL_ ZR_LIMU SG_ 1413 SI_BUS_06 5000;
BA_REL_ "GenSigTimeoutTime" BU_SG_REL_ ZR_LIMU SG_ 1413 SI_BUS_07 5000;
BA_REL_ "GenSigTimeoutTime" BU_SG_REL_ ZR_LIMU SG_ 1413 SI_BUS_08 5000;
BA_REL_ "GenSigTimeoutTime" BU_SG_REL_ ZR_LIMU SG_ 1413 SI_BUS_09 5000;
BA_REL_ "GenSigTimeoutTime" BU_SG_REL_ ZR_LIMU SG_ 1413 SI_BUS_10 5000;
BA_REL_ "GenSigTimeoutTime" BU_SG_REL_ ZR_LIMU SG_ 1413 SI_BUS_11 5000;
BA_REL_ "GenSigTimeoutTime" BU_SG_REL_ ZR_LIMU SG_ 1413 SI_BUS_12 5000;
BA_REL_ "GenSigTimeoutTime" BU_SG_REL_ ZR_LIMU SG_ 1413 SI_BUS_13 5000;
BA_REL_ "GenSigTimeoutTime" BU_SG_REL_ ZR_LIMU SG_ 1413 SI_BUS_14 5000;
BA_REL_ "GenSigTimeoutTime" BU_SG_REL_ ZR_LIMU SG_ 1413 SI_BUS_15 5000;
BA_REL_ "GenSigTimeoutTime" BU_SG_REL_ ZR_LIMU SG_ 1413 SI_Bus_Identifikation 5000;
BA_REL_ "GenSigTimeoutTime" BU_SG_REL_ ZR_LIMU SG_ 1413 SI_CAB 5000;
BA_REL_ "GenSigTimeoutTime" BU_SG_REL_ ZR_LIMU SG_ 977 BT_Tuer_geoeffnet 5000;
BA_REL_ "GenSigTimeoutTime" BU_SG_REL_ ZR_LIMU SG_ 977 BT_FH_Oeffnung 5000;
BA_REL_ "GenSigTimeoutTime" BU_SG_REL_ ZR_LIMU SG_ 976 FT_Tuer_geoeffnet 1000;
BA_REL_ "GenSigTimeoutTime" BU_SG_REL_ ZR_LIMU SG_ 976 FT_FH_Oeffnung 1000;
BA_REL_ "GenSigTimeoutTime" BU_SG_REL_ ZR_LIMU SG_ 976 FT_Kisi_li_aktiv 1000;
BA_REL_ "GenSigTimeoutTime" BU_SG_REL_ ZR_LIMU SG_ 976 FT_Kisi_re_aktiv 1000;
BA_REL_ "GenSigTimeoutTime" BU_SG_REL_ ZR_LIMU SG_ 975 HBFS_Tuer_geoeffnet 5000;
BA_REL_ "GenSigTimeoutTime" BU_SG_REL_ ZR_LIMU SG_ 975 HBFS_FH_Oeffnung 5000;
BA_REL_ "GenSigTimeoutTime" BU_SG_REL_ ZR_LIMU SG_ 974 HFS_Tuer_geoeffnet 5000;
BA_REL_ "GenSigTimeoutTime" BU_SG_REL_ ZR_LIMU SG_ 974 HFS_FH_Oeffnung 5000;
BA_REL_ "GenSigTimeoutTime" BU_SG_REL_ ZR_MIB_TOP_ab_Gen3 SG_ 516 STP_Status 5000;
BA_REL_ "GenSigTimeoutTime" BU_SG_REL_ ZR_MIB_TOP_ab_Gen3 SG_ 666 STP_Texte_ESK 4000;
BA_REL_ "GenSigTimeoutTime" BU_SG_REL_ ZR_MIB_TOP_ab_Gen3 SG_ 666 STP_Texte_AV 4000;
BA_REL_ "GenSigTimeoutTime" BU_SG_REL_ ZR_MIB_TOP_ab_Gen3 SG_ 666 STP_Texte 4000;
BA_REL_ "GenSigTimeoutTime" BU_SG_REL_ ZR_MIB_TOP_ab_Gen3 SG_ 1413 SI_Sammel_SG_Fehler 5000;
BA_REL_ "GenSigTimeoutTime" BU_SG_REL_ ZR_MIB_TOP_ab_Gen3 SG_ 1413 SI_Diagnose_Aktiv 5000;
BA_REL_ "GenSigTimeoutTime" BU_SG_REL_ ZR_MIB_TOP_ab_Gen3 SG_ 1413 SI_QRS_Mode 5000;
BA_REL_ "GenSigTimeoutTime" BU_SG_REL_ ZR_MIB_TOP_ab_Gen3 SG_ 1413 SI_T_Mode 5000;
BA_REL_ "GenSigTimeoutTime" BU_SG_REL_ ZR_MIB_TOP_ab_Gen3 SG_ 1413 SI_NWDF 5000;
BA_REL_ "GenSigTimeoutTime" BU_SG_REL_ ZR_MIB_TOP_ab_Gen3 SG_ 1413 SI_NWDF_gueltig 5000;
BA_REL_ "GenSigTimeoutTime" BU_SG_REL_ ZR_MIB_TOP_ab_Gen3 SG_ 1413 SI_Sammelfehler 5000;
BA_REL_ "GenSigTimeoutTime" BU_SG_REL_ ZR_MIB_TOP_ab_Gen3 SG_ 1413 SI_T_Schutz 5000;
BA_REL_ "GenSigTimeoutTime" BU_SG_REL_ ZR_MIB_TOP_ab_Gen3 SG_ 1413 SI_BUS_01 5000;
BA_REL_ "GenSigTimeoutTime" BU_SG_REL_ ZR_MIB_TOP_ab_Gen3 SG_ 1413 SI_BUS_02 5000;
BA_REL_ "GenSigTimeoutTime" BU_SG_REL_ ZR_MIB_TOP_ab_Gen3 SG_ 1413 SI_BUS_03 5000;
BA_REL_ "GenSigTimeoutTime" BU_SG_REL_ ZR_MIB_TOP_ab_Gen3 SG_ 1413 SI_BUS_04 5000;
BA_REL_ "GenSigTimeoutTime" BU_SG_REL_ ZR_MIB_TOP_ab_Gen3 SG_ 1413 SI_BUS_05 5000;
BA_REL_ "GenSigTimeoutTime" BU_SG_REL_ ZR_MIB_TOP_ab_Gen3 SG_ 1413 SI_BUS_06 5000;
BA_REL_ "GenSigTimeoutTime" BU_SG_REL_ ZR_MIB_TOP_ab_Gen3 SG_ 1413 SI_BUS_07 5000;
BA_REL_ "GenSigTimeoutTime" BU_SG_REL_ ZR_MIB_TOP_ab_Gen3 SG_ 1413 SI_BUS_08 5000;
BA_REL_ "GenSigTimeoutTime" BU_SG_REL_ ZR_MIB_TOP_ab_Gen3 SG_ 1413 SI_BUS_09 5000;
BA_REL_ "GenSigTimeoutTime" BU_SG_REL_ ZR_MIB_TOP_ab_Gen3 SG_ 1413 SI_BUS_10 5000;
BA_REL_ "GenSigTimeoutTime" BU_SG_REL_ ZR_MIB_TOP_ab_Gen3 SG_ 1413 SI_BUS_11 5000;
BA_REL_ "GenSigTimeoutTime" BU_SG_REL_ ZR_MIB_TOP_ab_Gen3 SG_ 1413 SI_BUS_12 5000;
BA_REL_ "GenSigTimeoutTime" BU_SG_REL_ ZR_MIB_TOP_ab_Gen3 SG_ 1413 SI_BUS_13 5000;
BA_REL_ "GenSigTimeoutTime" BU_SG_REL_ ZR_MIB_TOP_ab_Gen3 SG_ 1413 SI_BUS_14 5000;
BA_REL_ "GenSigTimeoutTime" BU_SG_REL_ ZR_MIB_TOP_ab_Gen3 SG_ 1413 SI_BUS_15 5000;
BA_REL_ "GenSigTimeoutTime" BU_SG_REL_ ZR_MIB_TOP_ab_Gen3 SG_ 1413 SI_Bus_Identifikation 5000;
BA_REL_ "GenSigTimeoutTime" BU_SG_REL_ ZR_MIB_TOP_ab_Gen3 SG_ 1413 SI_CAB 5000;
BA_REL_ "GenSigTimeoutTime" BU_SG_REL_ ZR_MIB_TOP_ab_Gen3 SG_ 977 BT_Tuer_geoeffnet 5000;
BA_REL_ "GenSigTimeoutTime" BU_SG_REL_ ZR_MIB_TOP_ab_Gen3 SG_ 977 BT_FH_Oeffnung 5000;
BA_REL_ "GenSigTimeoutTime" BU_SG_REL_ ZR_MIB_TOP_ab_Gen3 SG_ 976 FT_Tuer_geoeffnet 1000;
BA_REL_ "GenSigTimeoutTime" BU_SG_REL_ ZR_MIB_TOP_ab_Gen3 SG_ 976 FT_FH_Oeffnung 1000;
BA_REL_ "GenSigTimeoutTime" BU_SG_REL_ ZR_MIB_TOP_ab_Gen3 SG_ 976 FT_Kisi_li_aktiv 1000;
BA_REL_ "GenSigTimeoutTime" BU_SG_REL_ ZR_MIB_TOP_ab_Gen3 SG_ 976 FT_Kisi_re_aktiv 1000;
BA_REL_ "GenSigTimeoutTime" BU_SG_REL_ ZR_MIB_TOP_ab_Gen3 SG_ 975 HBFS_Tuer_geoeffnet 5000;
BA_REL_ "GenSigTimeoutTime" BU_SG_REL_ ZR_MIB_TOP_ab_Gen3 SG_ 975 HBFS_FH_Oeffnung 5000;
BA_REL_ "GenSigTimeoutTime" BU_SG_REL_ ZR_MIB_TOP_ab_Gen3 SG_ 974 HFS_Tuer_geoeffnet 5000;
BA_REL_ "GenSigTimeoutTime" BU_SG_REL_ ZR_MIB_TOP_ab_Gen3 SG_ 974 HFS_FH_Oeffnung 5000;
BA_REL_ "GenSigTimeoutTime" BU_SG_REL_ ZR_Standard SG_ 516 STP_Status 5000;
BA_REL_ "GenSigTimeoutTime" BU_SG_REL_ ZR_Standard SG_ 1413 SI_QRS_Mode 5000;
BA_REL_ "GenSigTimeoutTime" BU_SG_REL_ ZR_Standard SG_ 1413 SI_T_Mode 5000;
BA_REL_ "GenSigTimeoutTime" BU_SG_REL_ ZR_Standard SG_ 1413 SI_NWDF 5000;
BA_REL_ "GenSigTimeoutTime" BU_SG_REL_ ZR_Standard SG_ 1413 SI_NWDF_gueltig 5000;
BA_REL_ "GenSigTimeoutTime" BU_SG_REL_ ZR_Standard SG_ 1413 SI_BUS_01 5000;
BA_REL_ "GenSigTimeoutTime" BU_SG_REL_ ZR_Standard SG_ 1413 SI_BUS_02 5000;
BA_REL_ "GenSigTimeoutTime" BU_SG_REL_ ZR_Standard SG_ 1413 SI_BUS_03 5000;
BA_REL_ "GenSigTimeoutTime" BU_SG_REL_ ZR_Standard SG_ 1413 SI_BUS_06 5000;
BA_REL_ "GenSigTimeoutTime" BU_SG_REL_ ZR_Standard SG_ 1413 SI_BUS_07 5000;
BA_REL_ "GenSigTimeoutTime" BU_SG_REL_ ZR_Standard SG_ 1413 SI_BUS_08 5000;
BA_REL_ "GenSigTimeoutTime" BU_SG_REL_ ZR_Standard SG_ 976 FT_Kisi_li_aktiv 1000;
BA_REL_ "GenSigTimeoutTime" BU_SG_REL_ ZR_Standard SG_ 976 FT_Kisi_re_aktiv 1000;
VAL_ 1650 STH_ZZ_Monat 0 "Init" ;
VAL_ 1650 STH_ZZ_Tag 0 "Init" ;
VAL_ 1650 STH_ZZ_Betriebsmodus 0 "Don_t Care" 1 "ECO" 2 "Standard" 3 "Standard plus" 4 "Comfort" ;
VAL_ 1650 STH_ZZ_Status_Timer 0 "Don_t Care" 1 "Timer n.aktiv bzw loeschen" 2 "Timer aktiv/bzw aktivieren" ;
VAL_ 516 STP_Status 0 "STP_Init" 1 "STP_Deaktiviert" 2 "Vorhalt" 3 "STP_Nicht_Aktivierbar" 4 "Vorhalt" 5 "STP_Aktivierbar" 6 "STP_Aktiv" 7 "STP_Aktivierung" 8 "STP_Aktiv_ESK0" 9 "STP_Aktiv_ESK1" 10 "STP_Aktiv_ESK2" 11 "STP_Aktiv_ESK3" 12 "STP_Aktiv_Notlauf" 13 "STP_Aktiv_Stabiler_Zustand" 14 "STP_Aktiv_Uebernahme" 15 "STP_Fehler" ;
VAL_ 516 STP_Abschaltbedingung 0 "AB_liegt_an" 1 "AB_liegt_nicht_an_oder_init" ;
VAL_ 516 STP_Aktivierverhinderung 0 "AV_liegt_an_oder_init" 1 "AV_liegt_nicht_an" ;
VAL_ 516 STP_Freiraum 0 "Freiraum_um_das_Fahrzeug_vorhanden" 1 "Freiraum_vorne_nicht_vorhanden" 2 "Freiraum_rechts_nicht_vorhanden" 3 "Freiraum_rechts_und_vorne_nicht_vorhanden" 4 "Freiraum_links_nicht_vorhanden" 5 "Freiraum_links_und_vorne_nicht_vorhanden" 6 "Freiraum_links_und_rechts_nicht_vorhanden" 7 "Freiraum_vorne_links_und_rechts_nicht_vorhanden" ;
VAL_ 516 ACA_HF_LRR_Abschaltbedingung 0 "AB_liegt_nicht_an" 1 "AB_Uebernahme_1" 2 "AB_Uebernahme_2" 3 "AB_Uebernahme_3" 7 "Init" ;
VAL_ 516 ACA_HF_LRR_Status 0 "Init" 1 "Bereit" 6 "Reversibler_Fehler" 7 "Irreversibler_Fehler" ;
VAL_ 516 ACA_HF_LRR_Aktivierverhinderung 0 "AV_liegt_nicht_an" 1 "AV_liegt_an_oder_init" ;
VAL_ 516 ACC_Pilot_Verz_Anf 1022 "Neutralwert" 1023 "Init" ;
VAL_ 516 STP_DAF_Code 0 "Init" ;
VAL_ 666 STP_Abstand_Zielobjekt 0 "keine_Anzeige_oder_init" ;
VAL_ 666 STP_Texte_ESK 0 "keine_Anzeige" 1 "STP_ESK_keine_Laenderverfuegbarkeit" 2 "STP_ESK_Abfahrt_erkannt" 3 "STP_ESK_falsche_Strassenkat" 4 "STP_ESK_Delta_v_zu_hoch" 5 "STP_ESK_Stabilisierungsys_aktiv" 6 "STP_ESK_keine_Trennung_zum_Gv" 7 "STP_ESK_Fussgaenger_erkannt" 8 "STP_ESK_kein_Stau_auf_Nachbars" 9 "STP_ESK_V_Streckenabsch_unplaus" 10 "STP_ESK_pACC_nicht_verfuegbar" 11 "STP_ESK_Rettungsg_stark_versetzt" 12 "STP_ESK_Baustelle" 13 "STP_ESK_Sicherheitskor_verletzt" ;
VAL_ 666 STP_Status_Anzeige 0 "STP_INIT" 1 "STP_AUS" 2 "STP_PASSIV" 3 "STP_AKTIV_1" 4 "STP_AKTIV_2" 5 "STP_Eskalationsstufe_1" 6 "STP_Eskalationsstufe_2" 7 "STP_Eskalationsstufe_3" 8 "STP_Eskalationsstufe_4" 9 "STP_Fehler" ;
VAL_ 666 STP_Nebenspur_links_ZA 0 "keine_Anzeige_oder_init" 1 "Nachbarkolonne" 2 "Randbebauung" ;
VAL_ 666 STP_Nebenspur_rechts_ZA 0 "keine_Anzeige_oder_init" 1 "Nachbarkolonne" 2 "Randbebauung" ;
VAL_ 666 STP_FBM_links_ZA 0 "keine_Anzeige_oder_init" 1 "FBM_an" ;
VAL_ 666 STP_Geschw_Egofahrzeug_ZA 0 "statisch_init" 1 "dynamisch" ;
VAL_ 666 STP_Egokolonne_ZA 0 "keine_Anzeige_oder_init" 1 "eng" 2 "weit" 3 "Warnung" ;
VAL_ 666 STP_FBM_rechts_ZA 0 "keine_Anzeige_oder_init" 1 "FBM_an" ;
VAL_ 666 STP_FAS_Fkt_Status 0 "Init" 1 "Funktion_Ist_Ein" 2 "Funktion_Ist_Aus" 3 "Fehler" 4 "Pilot_Aktiv" ;
VAL_ 666 STP_Texte_ZA 0 "keine_Anzeige" 1 "STP_Uebernahme_1" 2 "STP_Uebernahme_2" 3 "Unklare_Verkehrssituation" 4 "Kurvenradius" 5 "Gurt_offen" 6 "Stauende" 7 "Wegfall_Fahrspur" 8 "STP_Car_Pool_Lane" 9 "Fahrer_nicht_erkannt" 10 "STP_unzulaessige_Fahrspur" ;
VAL_ 666 STP_Texte_AV 0 "keine_Anzeige" 1 "STP_AV_CarMenue_aus" 2 "STP_AV_Anhaengerbetrieb" 3 "STP_AV_Wegfall_Fahrspur" 4 "STP_AV_Kurvenradius" 5 "STP_AV_Abfahrt_erkannt" 6 "STP_AV_Unklare_Verkehrssituation" 7 "STP_AV_Delta_v_zu_hoch" 8 "STP_AV_Stabilisierungssys_aktiv" 9 "STP_AV_Gangstufe_nicht_erlaubt" 10 "STP_AV_keine_Trennung_zum_Gv" 11 "STP_AV_Fussgaenger_erkannt" 12 "STP_AV_kein_Stau_auf_Nachbarstr" 13 "STP_AV_Rettungsg_stark_versetzt" 14 "STP_AV_Baustelle" 15 "STP_AV_Sicherheitskor_verletzt" ;
VAL_ 666 STP_Texte 0 "keine_Anzeige" 1 "STP_nicht_verfuegbar" 2 "STP_Stoerung" 3 "STP_Uebernahme_1" 4 "STP_Uebernahme_2" 5 "STP_Lenkung_Pedalerie_freigeben" 6 "STP_Pilottaste_druecken" 7 "STP_Aktivierverhinderung" 8 "STP_Eskalationsstufe_2" 9 "STP_Eskalationsstufe_3" 10 "STP_Eskalationsstufe_4" 11 "STP_deaktiviert" 12 "STP_Bremsung_1" 13 "STP_Bremsung_2" 14 "STP_Fahrer_nicht_erkannt" 15 "STP_aktiv" 16 "STP_keine_Laenderverfuegbarkeit" 17 "STP_unzulaessige_Fahrspur" 18 "STP_Baustelle_voraus" 19 "STP_Rampe_voraus" 20 "STP_Autobahnende_voraus" ;
VAL_ 666 STP_Primaeranz_02 0 "keine_Anzeige" 1 "Verfuegbar" 2 "Aktiv" 3 "Uebernahme" 4 "Aktiv_Warnung" 5 "Nicht_Verfuegbar" ;
VAL_ 666 STP_Nebenspur_Geschw_links_ZA 255 "keine_Anzeige" ;
VAL_ 666 STP_Nebenspur_Geschw_rechts_ZA 255 "keine_Anzeige" ;
VAL_ 1172 STS_Car_not_under_theft 0 "false" 1 "true" ;
VAL_ 1172 STS_Car_under_theft 0 "false" 1 "true" ;
VAL_ 1172 STS_Door_Lock 0 "Init" 1 "door_lock" ;
VAL_ 1172 STS_Anlassersperre 0 "inaktiv" 1 "aktiv" ;
VAL_ 1172 STS_Typencodierung 0 "Basis" 1 "E-Gas" 4 "Sonderschutz" ;
VAL_ 1172 STS_Spiegel_Anklappen 0 "Init" 1 "Spiegel_anklappen" ;
VAL_ 1172 GW_STS2_Privatsphaere 0 "Aus" 1 "Ein" ;
VAL_ 1172 STS_Standlicht 0 "inaktiv" 1 "aktiv" ;
VAL_ 1172 STS_Fahrlicht 0 "inaktiv" 1 "aktiv" ;
VAL_ 1172 STS_Alarm_still 0 "inaktiv" 1 "aktiv" ;
VAL_ 1172 STS_Texte 0 "kein_Text" 1 "Text_01" 2 "Text_02" 3 "Text_03" 4 "Text_04" 5 "Text_05" 6 "Text_06" 7 "Text_07" 8 "Text_08" 9 "Text_09" 10 "Text_10" 11 "Text_11" 12 "Text_12" 13 "Text_13" 14 "Init" 15 "Fehler" ;
VAL_ 1172 STS_Laderelais 0 "Relais_offen" 1 "Relais_geschlossen" ;
VAL_ 1172 STS_Summer 0 "inaktiv" 1 "aktiv" ;
VAL_ 1172 STS_Notstart 0 "kein_Notstart" 1 "Notstart" ;
VAL_ 1172 STS_Signalhorn 0 "inaktiv" 1 "aktiv" ;
VAL_ 1172 STS_Leerlaufschaltung 0 "inaktiv" 1 "aktiv" ;
VAL_ 783 SWA_Anzeigen 0 "keine_Anzeige" 1 "Text_1_SWA_zurzeit_nicht_verfuegbar" 2 "Text_2_SWA_Systemstoerung" 3 "Text_3_SWA_zurzeit_nicht_verfuegbar_Keine_Sensorsicht" 4 "Text_4_SWA_zurzeit_nicht_verfuegbar_Anhaengerbetrieb" ;
VAL_ 783 SWA_Blindheit_erkannt 0 "nicht erkannt" 1 "erkannt" ;
VAL_ 783 SWA_rel_Nichtverf 0 "verfuegbar" 1 "nicht verfuegbar" ;
VAL_ 783 SWA_rel_Fehler 0 "kein Fehler" 1 "Fehler" ;
VAL_ 783 SWA_Sta_aktiv 0 "Aus" 1 "Ein" ;
VAL_ 783 SWA_Sta_passiv 0 "Aus" 1 "Ein" ;
VAL_ 783 SWA_FT_RueckLED 0 "inaktiv" 1 "aktiv" ;
VAL_ 783 ASW_Status 0 "Passiv" 1 "Aktiv" 2 "Fehler" 3 "AUS" ;
VAL_ 783 SWA_Standziele_li 0 "Abstand i.O." 1 "Abstand zu gering" ;
VAL_ 783 SWA_Kolonne_li 0 "zwei_oder_weniger_Fahrzeuge_auf_der_Spur" 1 "mehr_als_zwei_Fahrzeuge_auf_der_Spur" ;
VAL_ 783 SWA_Infostufe_SWA_li 0 "keine_Aktion" 1 "Aktion" ;
VAL_ 783 SWA_Warnung_SWA_li 0 "keine Warnung" 1 "Warnung aktiv" ;
VAL_ 783 ASW_Warnung_FS 0 "inaktiv" 1 "aktiv" ;
VAL_ 783 ASW_Warnung_BFS 0 "inaktiv" 1 "aktiv" ;
VAL_ 783 ASW_Kombitexte 0 "keine Anzeige.    //    Prio 5" 1 "Text_1_ASW_zur_Zeit_nicht_verfuegbar_und_Akustik    //    Prio 2" 2 "Text_2_ASW_Systemfehler_und_Akustik    //    Prio 1" 3 "Text_3_ASW_Sensor_blockiert_und_Akustik    //    Prio 3" 4 "Text_4_ASW_im_Anhaengerbetrieb_nicht_verfuegbar_und_Akustik    //    Prio 4" 5 "Text_5_ASW_Warnung_FS_und_Akustik" 6 "Text_6_ASW_Warnung_BFS_und_Akustik" 7 "Text_7_ASW_aus" ;
VAL_ 783 SWA_Kolonne_mi 0 "zwei_oder_weniger_Fahrzeuge_auf_der_Spur" 1 "mehr_als_zwei_Fahrzeuge_auf_der_Spur" ;
VAL_ 783 ASW_Modus 0 "kein_Fehler_KL15" 1 "kein_Fehler_KL30" 2 "reserve" 3 "Anhaengerbetrieb" 4 "Init_nicht_codiert" 5 "keine_Sensorsicht_blindheit" 6 "Zur_zeit_nicht_verfuegbar_temp_Fehler" 7 "Systemstoerung_dauer_fehler" ;
VAL_ 783 SWA_Modus 0 "kein_Fehler_verfuegbar" 1 "reserve" 2 "reserve" 3 "Anhaengerbetrieb" 4 "Init_nicht_codiert" 5 "keine_Sensorsicht_blindheit" 6 "Zur_zeit_nicht_verfuegbar_temp_Fehler" 7 "Systemstoerung_dauer_fehler" ;
VAL_ 783 SWA_Standziele_re 0 "Abstand i.O." 1 "Abstand zu gering" ;
VAL_ 783 SWA_Kolonne_re 0 "zwei_oder_weniger_Fahrzeuge_auf_der_Spur" 1 "mehr_als_zwei_Fahrzeuge_auf_der_Spur" ;
VAL_ 783 SWA_Infostufe_SWA_re 0 "keine_Aktion" 1 "Aktion" ;
VAL_ 783 SWA_Warnung_SWA_re 0 "keine Warnung" 1 "Warnung aktiv" ;
VAL_ 783 HRE_Anzeigetexte 0 "keine_Anzeige" 1 "BSD_RTA_zZt_nicht_verfuegbar" 2 "BSD_RTA_Systemfehler" 3 "BSD_RTA_Sensor_blockiert" 4 "BSD_RTA_Anhaengerbetrieb" 5 "RTA_Warnung" 6 "BSD_Warnung" 7 "Fahreruebernahme_Notbremsung" 8 "RTA_nicht_verfuegbar" 9 "BSD_RTA_ASW_zZt_nicht_verfuegbar" 10 "BSD_RTA_ASW_Systemfehler" 11 "BSD_RTA_ASW_Sensor_blockiert" 12 "BSD_RTA_ASW_Anhaengerbetrieb" ;
VAL_ 783 SWA_Status_02 0 "aus" 1 "passiv" 2 "aktiv" 3 "Fehler" ;
VAL_ 783 Heckradar_Kombitexte 0 "keine Anzeige.    //    Prio 5" 1 "Text_1_SWA_und_ASW_zur_Zeit_nicht_verfuegbar_und_Akustik    //    Prio 2" 2 "Text_2_SWA_und_ASW_Systemfehler_und_Akustik    //    Prio 1" 3 "Text_3_SWA_und_ASW_Sensor_blockiert_und_Akustik    //    Prio 3" 4 "Text_4_SWA_und_ASW_im_Anhaengerbetrieb_nicht_verfuegbar_und_Akustik    //    Prio 4" 5 "Text_1_SWA_und_RCTA_zur_Zeit_nicht_verfuegbar_und_Akustik // Prio 2" 6 "Text_2_SWA_und_RCTA_Systemfehler_und_Akustik // Prio 1" 7 "		Text_3_SWA_und_RCTA_Sensor_blockiert_und_Akustik // Prio 3" 8 "Text_4_SWA_und_RCTA_im_Anhaengerbetrieb_nicht_verfuegbar_und_Akustik // Prio 4" 9 "Text_1_ASW_und_RCTA_zur_Zeit_nicht_verfuegbar_und_Akustik // Prio 2" 10 "Text_2_ASW_und_RCTA_Systemfehler_und_Akustik // Prio 1" 11 "Text_3_ASW_und_RCTA_Sensor_blockiert_und_Akustik // Prio 3" 12 "Text_4_ASW_und_RCTA_im_Anhaengerbetrieb_nicht_verfuegbar_und_Akustik // Prio 4" 13 "Text_1_SWA_und_ASW_und_RCTA_zur_Zeit_nicht_verfuegbar_und_Akustik // Prio 2" 14 "Text_2_SWA_und_ASW_und_RCTA_Systemfehler_und_Akustik // Prio 1" 15 "Text_3_SWA_und_ASW_und_RCTA_Sensor_blockiert_und_Akustik // Prio 3" 16 "Text_4_SWA_und_ASW_und_RCTA_im_Anhaengerbetrieb_nicht_verfuegbar_und_Akustik // Prio 4" 17 "reserviert" 18 "reserviert" 19 "reserviert" 20 "reserviert" 21 "reserviert" 22 "reserviert" 23 "reserviert" 24 "reserviert" 25 "reserviert" 26 "reserviert" 27 "reserviert" 28 "reserviert" 29 "reserviert" ;
VAL_ 783 RCTA_Kombitexte 0 "keine_Anzeige" 1 "RCTA_zur_Zeit_nicht_verfuegbar" 2 "RCTA_Systemfehler" 3 "RCTA_Sensor_blockiert" 4 "RCTA_im_Anhaengerbetrieb" 5 "RTA_Warnung" 6 "Fahreruebernahme_Notbremsung" 7 "Eingeschraenkt_verfuegbar_ESCaus" ;
VAL_ 1413 SI_Sammel_SG_Fehler 61 "Reserviert" 62 "Overflow" 63 "ungueltig" ;
VAL_ 1413 SI_Diagnose_Aktiv 0 "inaktiv" 1 "aktiv" ;
VAL_ 1413 SI_QRS_Mode 0 "QRS_Messmodus_nicht_aktiv" 1 "QRS_Messmodus_aktiv" ;
VAL_ 1413 SI_T_Mode 0 "Transportmodus_nicht_aktiv" 1 "Transportmodus_aktiv" ;
VAL_ 1413 SI_NWDF 0 "Ueberwachung_nicht_freigegeben" 1 "Ueberwachung_freigegeben" ;
VAL_ 1413 SI_NWDF_gueltig 0 "NWDF_wird_nicht_unterstuetzt" 1 "NWDF_wird_unterstuetzt" ;
VAL_ 1413 SI_Sammelfehler 0 "kein_Sammelfehler" 1 "Sammelfehler" ;
VAL_ 1413 GW_KD_Fehler 0 "kein_KD_Fehler" 1 "KD_Fehler" ;
VAL_ 1413 SI_T_Schutz 0 "Transportschutz_nicht_aktiv" 1 "Transportschutz_aktiv" ;
VAL_ 1413 SI_BUS_01 0 "keine_Busruhe" 1 "Busruhe" ;
VAL_ 1413 SI_BUS_02 0 "keine_Busruhe" 1 "Busruhe" ;
VAL_ 1413 SI_BUS_03 0 "keine_Busruhe" 1 "Busruhe" ;
VAL_ 1413 SI_BUS_04 0 "keine_Busruhe" 1 "Busruhe" ;
VAL_ 1413 SI_BUS_05 0 "keine_Busruhe" 1 "Busruhe" ;
VAL_ 1413 SI_BUS_06 0 "keine_Busruhe" 1 "Busruhe" ;
VAL_ 1413 SI_BUS_07 0 "keine_Busruhe" 1 "Busruhe" ;
VAL_ 1413 SI_BUS_08 0 "keine_Busruhe" 1 "Busruhe" ;
VAL_ 1413 SI_BUS_09 0 "keine_Busruhe" 1 "Busruhe" ;
VAL_ 1413 SI_BUS_10 0 "keine_Busruhe" 1 "Busruhe" ;
VAL_ 1413 SI_BUS_11 0 "keine_Busruhe" 1 "Busruhe" ;
VAL_ 1413 SI_BUS_12 0 "keine_Busruhe" 1 "Busruhe" ;
VAL_ 1413 SI_BUS_13 0 "keine_Busruhe" 1 "Busruhe" ;
VAL_ 1413 SI_BUS_14 0 "keine_Busruhe" 1 "Busruhe" ;
VAL_ 1413 SI_BUS_15 0 "keine_Busruhe" 1 "Busruhe" ;
VAL_ 1413 SI_Bus_Identifikation 16 "CAN_Diagnose" 17 "CAN_Antrieb" 18 "CAN_Komfort" 19 "CAN_Infotainment" 20 "CAN_Fahrwerk" 21 "CAN_Extended" 22 "CAN_Hybrid" 23 "CAN_Lade" 24 "CAN_Kombi" 25 "CAN_Komfort_2" 26 "CAN_AFS" 33 "CAN_FahrerAssistenzSysteme" 34 "CAN_Migration" 35 "CAN_Connect" 36 "CAN_AnzeigeBedienung" 37 "CAN_ElectricalVehicle" 40 "CAN_Telematik" 41 "CAN_MFL" 48 "FlexRay_A" 49 "FlexRay_B" 97 "VLAN_FAS" 98 "VLAN_Infotainment" 99 "VLAN_Connect" 100 "VLAN_Komfort" 101 "VLAN_Antrieb" 102 "VLAN_Diagnose" 103 "VLAN_Internet" 104 "VLAN_Gateway" 105 "VLAN_Remote_FC" 106 "VLAN_Connect_2" ;
VAL_ 1413 SI_CAB 0 "inaktiv" 1 "CAB_01__Tueren" 2 "CAB_02__Anhaenger" 4 "CAB_03__Nightvision" 8 "CAB_04__Sitzverstellung" 16 "CAB_05__Klappen" 32 "CAB_06__Infotainment" 64 "CAB_07__Sub_Infotainment" 128 "CAB_08__Anzeige" 256 "CAB_09__Laden" 512 "CAB_10__Klima" 1024 "CAB_11__FlexRay" 262144 "CAB_19_VLAN_Remote_FC" 524288 "CAB_20_VLAN_Komfort" 1048576 "CAB_21_VLAN_Internet" 2097152 "CAB_22_VLAN_Connect" 4194304 "CAB_23_VLAN_Infotainment" 8388608 "CAB_24_VLAN_FAS" ;
VAL_ 2589283622 TLO_LSA1_Zeit1_Pred 0 "Init" ;
VAL_ 2589283622 TLO_LSA1_Zeit1_Status 0 "UNAVAILABLE" 1 "STOP_THEN_PROCEED" 2 "STOP_AND_REMAIN" 3 "PRE_MOVEMENT" 4 "PERMISSIVE_MOVEMENT_ALLOWED" 5 "PROTECTED_MOVEMENT_ALLOWED" 6 "PERMISSIVE_CLEARANCE" 7 "PROTECTED_CLEARANCE" 8 "CAUTION_CONFLICTING_TRAFFIC" ;
VAL_ 2589283622 TLO_LSA1_Zeit2_Pred 0 "Init" ;
VAL_ 2589283622 TLO_LSA1_Zeit2_Status 0 "UNAVAILABLE" 1 "STOP_THEN_PROCEED" 2 "STOP_AND_REMAIN" 3 "PRE_MOVEMENT" 4 "PERMISSIVE_MOVEMENT_ALLOWED" 5 "PROTECTED_MOVEMENT_ALLOWED" 6 "PERMISSIVE_CLEARANCE" 7 "PROTECTED_CLEARANCE" 8 "CAUTION_CONFLICTING_TRAFFIC" ;
VAL_ 2589283622 TLO_HMI_Status 0 "Init" 1 "Active__Funktion_Verbindung_iO" 2 "Standby_Normal_Mode__Warten_auf_neue_Daten" 3 "SwitchedOff__Durch_Fahrer_deaktiviert" 4 "FilteredOut__Nicht_angezeigter_Hinweis" 5 "ActiveFunktionVerbindung_iO_A_Gl" 6 "ActiveFunktionVerbindung_iO_A_Tg" ;
VAL_ 2589283622 TLO_LSA1_PSD_Segment_ID 0 "Init" ;
VAL_ 2589283622 TLO_StartStoppInfo 0 "Motorlauf_nicht_notwendig_(Stoppfreigabe)" 1 "Motoranlauf_nicht_zwingend_notwendig_(Stoppverbot,keine_Startanforderung)" 2 "Motoranlauf_zwingend_notwendig_(Startanforderung)" 3 "Systemfehler" ;
VAL_ 2589283622 TLO_LSA1_PSD_Seg_Offset 255 "Init" ;
VAL_ 2589283623 TLO_LSA2_Zeit1_Pred 0 "Init" ;
VAL_ 2589283623 TLO_LSA2_Zeit1_Status 0 "UNAVAILABLE" 1 "STOP_THEN_PROCEED" 2 "STOP_AND_REMAIN" 3 "PRE_MOVEMENT" 4 "PERMISSIVE_MOVEMENT_ALLOWED" 5 "PROTECTED_MOVEMENT_ALLOWED" 6 "PERMISSIVE_CLEARANCE" 7 "PROTECTED_CLEARANCE" 8 "CAUTION_CONFLICTING_TRAFFIC" ;
VAL_ 2589283623 TLO_LSA2_Zeit2_Pred 0 "Init" ;
VAL_ 2589283623 TLO_LSA2_Zeit2_Status 0 "UNAVAILABLE" 1 "STOP_THEN_PROCEED" 2 "STOP_AND_REMAIN" 3 "PRE_MOVEMENT" 4 "PERMISSIVE_MOVEMENT_ALLOWED" 5 "PROTECTED_MOVEMENT_ALLOWED" 6 "PERMISSIVE_CLEARANCE" 7 "PROTECTED_CLEARANCE" 8 "CAUTION_CONFLICTING_TRAFFIC" ;
VAL_ 2589283623 TLO_LSA1_Layout 0 "vertical_layout_red_top" 1 "horizontal_layout_red_left" 2 "horizontal_layout_red_right" 3 "reserved" ;
VAL_ 2589283623 TLO_LSA2_PSD_Segment_ID 0 "Init" ;
VAL_ 2589283623 TLO_LSA2_PSD_Seg_Offset 255 "Init" ;
VAL_ 1447 TM_Spiegel_Anklappen 0 "Init" 1 "Spiegel_anklappen" ;
VAL_ 1447 TM_Nur_Hupen 0 "inaktiv" 1 "aktiv" ;
VAL_ 1447 TM_Door_Lock 0 "Init" 1 "door_lock" ;
VAL_ 1447 TM_Door_Unlock 0 "Init" 1 "door_unlock" ;
VAL_ 1447 TM_Warnblinken 0 "Init" 1 "Warnblinken_on" ;
VAL_ 1447 TM_Panik_Alarm 0 "Init" 1 "panik_alarm_on" ;
VAL_ 1447 TM_ZV_Signatur 0 "Init" ;
VAL_ 977 BT_Tuer_geoeffnet 0 "geschlossen" 1 "offen" ;
VAL_ 977 BT_verriegelt 0 "Init" 1 "verriegelt" ;
VAL_ 977 BT_gesafet 0 "Init" 1 "gesafet" ;
VAL_ 977 BT_Schluesselschalter_auf 0 "Init" 1 "Schluesselschalter_auf_betaetigt" ;
VAL_ 977 BT_Schluesselschalter_zu 0 "Init" 1 "Schluesselschalter_zu_betaetigt" ;
VAL_ 977 BT_Unlock_Taster 0 "Init" 1 "Unlock_Taster_betaetigt" ;
VAL_ 977 BT_Lock_Taster 0 "Init" 1 "Lock_Taster_betaetigt" ;
VAL_ 977 BT_Sperrklinke 0 "Schloss_in_Vorraste_und_Hauptraste" 1 "Tuer_auf_oder_Tuer_Position_zwischen_Vor_und_Hauptraste" ;
VAL_ 977 BT_TAG_betaetigt 0 "Init" 1 "Tuerinnengriff_betaetigt" ;
VAL_ 977 BT_TIG_betaetigt 0 "Init" 1 "Tuerinnengriff_betaetigt" ;
VAL_ 977 BT_Tuer_Status 0 "Init" 1 "Tuer geschlossen" 2 "Tuer offen" 3 "Fehler" ;
VAL_ 977 BT_TSG_hinten_verbaut 0 "nicht verbaut" 1 "verbaut" ;
VAL_ 977 BT_Sp_Blk_def 0 "iO" 1 "Spiegel_Blinker_defekt" ;
VAL_ 977 BT_FH_S_ManHoch 0 "Init" 1 "FH_Schalter_man_hoch_gedrueckt" ;
VAL_ 977 BT_FH_S_AutoHoch 0 "Init" 1 "FH_Schalter_auto_hoch_gedrueckt" ;
VAL_ 977 BT_FH_S_ManTief 0 "Init" 1 "FH_Schalter_man_tief_gedrueckt" ;
VAL_ 977 BT_FH_S_AutoTief 0 "Init" 1 "FH_Schalter_auto_tief_gedrueckt" ;
VAL_ 977 BT_FH_Bew_hoch 0 "Init" 1 "FH_ist_in_Bewegung_hoch" ;
VAL_ 977 BT_FH_Bew_tief 0 "Init" 1 "FH_ist_in_Bewegung_tief" ;
VAL_ 977 BT_FH_Fang 0 "ausserhalb_Fangbereich" 1 "innerhalb_Fangbereich" ;
VAL_ 977 BT_FH_Block 0 "Init" 1 "Fensterheber_Block" ;
VAL_ 977 BT_FH_Thermo 0 "Init" 1 "Thermoschutz_aktiv" ;
VAL_ 977 BT_UEKB_aktiviert 0 "Init" 1 "aktiv" ;
VAL_ 977 BT_Kisi_Fehler 0 "kein_Fehler" 1 "Fehler" ;
VAL_ 977 BT_FH_normiert 1 "Fenster_normiert" ;
VAL_ 977 BT_Schliesstaster 1 "betaetigt" ;
VAL_ 977 BT_Zuziehhilfe_aktiv 1 "Zuziehhilfe_aktiv" ;
VAL_ 977 BT_SP_ausgerastet 0 "Init" 1 "Spiegel_ausgerastet" ;
VAL_ 977 BT_SP_lr_aktiv 0 "Init" 1 "Spiegel_xAchse_aktiv" ;
VAL_ 977 BT_SP_ht_aktiv 0 "Init" 1 "Spiegel_yAchse_aktiv" ;
VAL_ 977 BT_SP_Heizung_aktiv 1 "BF Spiegelheizung ein" ;
VAL_ 977 BT_Oben_Block_erw 0 "Fensterheber_nicht_in_Blockerwar" 1 "Fensterheber_in_Blockerwartung_o" ;
VAL_ 977 BT_Unten_Block_erw 0 "Fensterheber_nicht_in_Blockerwar" 1 "Fensterheber_in_Blockerwartung_u" ;
VAL_ 977 BT_Tuer_Status_QBit 0 "Status_Tuerkontakt_sicher" 1 "Status_Tuerkontakt_unsicher" ;
VAL_ 977 BFS_Status_eTAG 0 "Init" 1 "Griff_ausgefahren" 2 "Griff_eingefahren" 3 "Fehler" ;
VAL_ 977 BT_TCR_Mode_aktiv 0 "TCR_Mode_deaktiv" 1 "TCR_Mode_aktiv" ;
VAL_ 977 BT_SP_Heizung_Status 0 "Init" 1 "Status_Spiegelheizung_ein" ;
VAL_ 977 ASW_Warnung_aktiv_BFS 0 "nicht_angefordert" 1 "angefordert" ;
VAL_ 977 BT_FH_Pos_oben 1 "Scheibe oben (nach Absenken auf Position) " ;
VAL_ 977 BT_Tuerschloss_defekt 0 "Tuerschloss_funktionsfaehig" 1 "Tuerschloss_defekt" ;
VAL_ 977 BT_Tueroeffnen_Warnung 0 "Tuerwarnung_nicht_aktiv" 1 "Tuerwarnung_aktiv" ;
VAL_ 977 BT_Lock_Taster_inv 0 "Lock Taster betätigt" 1 "Lock Taster nicht betätigt" ;
VAL_ 977 BT_Schluesselschalter_zu_inv 0 "Schlüsselschalter betätigt" 1 "Schlüsselschalter nicht betätigt" ;
VAL_ 977 BT_SWA_HMI_defekt 0 "SWA_kein_Fehler" 1 "SWA_Fehler" ;
VAL_ 977 BT_ASW_HMI_defekt 0 "ASW_kein_Fehler" 1 "ASW_Fehler" ;
VAL_ 1451 TSG_FlHz_BFS_NTC_A 125 "Fehler_NTC_OpenLoad__KS_Plus" 126 "Fehler_NTC_Overload__KS_Minus" 127 "Init" ;
VAL_ 1451 TSG_FlHz_BFS_FnAbbruchHzKreis_A 0 "OK" 1 "FunktionsAbbruch" ;
VAL_ 1451 TSG_FlHz_BFS_NTC_B 125 "Fehler_NTC_OpenLoad__KS_Plus" 126 "Fehler_NTC_Overload__KS_Minus" 127 "Init" ;
VAL_ 1451 TSG_FlHz_BFS_FnAbbruchHzKreis_B 0 "OK" 1 "FunktionsAbbruch" ;
VAL_ 976 FT_Tuer_geoeffnet 0 "Init" 1 "Tuer offen" ;
VAL_ 976 FT_verriegelt 0 "Init" 1 "verriegelt" ;
VAL_ 976 FT_gesafet 0 "Init" 1 "gesafet" ;
VAL_ 976 FT_Schluesselschalter_auf 0 "Init" 1 "Schluesselschalter_auf_betaetigt" ;
VAL_ 976 FT_Schluesselschalter_zu 1 "Schluesselschalter zu betaetigt" ;
VAL_ 976 FT_Unlock_Taster 0 "Init" 1 "Unlock_Taster_betaetigt" ;
VAL_ 976 FT_Lock_Taster 0 "Init" 1 "Lock_Taster_betaetigt" ;
VAL_ 976 FT_Sperrklinke 0 "Schloss_in_Vorraste_und_Hauptraste" 1 "Tuer_auf_oder_Tuer_Position_zwischen_Vor_und_Hauptraste" ;
VAL_ 976 FT_TAG_betaetigt 0 "nicht_betaetigt" 1 "betaetigt" ;
VAL_ 976 FT_TIG_betaetigt 0 "nicht_betaetigt" 1 "betaetigt" ;
VAL_ 976 FT_IRUE_Taste 0 "Init" 1 "IRUE_Taste_betaetigt" ;
VAL_ 976 FT_HD_Taste 0 "Init" 1 "Heckdeckel_oeffnen" ;
VAL_ 976 FT_TD_Taste_Fehler 0 "iO" 1 "defekt" ;
VAL_ 976 FT_TD_Taste 1 "Tankdeckelentriegelungs Taster gedrückt" ;
VAL_ 976 SSR_Temp_Freigabe 0 "SSR_Deaktiviert" 1 "SSR_Freigegeben" ;
VAL_ 976 FT_HD_Taste_2 0 "Taste_nicht_gedrueckt" 1 "Taste_gedrueckt" ;
VAL_ 976 FT_TSG_hinten_verbaut 0 "nicht verbaut" 1 "verbaut" ;
VAL_ 976 FT_Sp_Blk_def 0 "iO" 1 "defekt" ;
VAL_ 976 FT_FH_S_ManHoch 0 "Init" 1 "FH_Schalter_man_hoch_betaetigt" ;
VAL_ 976 FT_FH_S_AutoHoch 0 "Init" 1 "FH_Schalter_auto_hoch_betaetigt" ;
VAL_ 976 FT_FH_S_ManTief 0 "Init" 1 "FH_Schalter_man_tief_betaetigt" ;
VAL_ 976 FT_FH_S_AutoTief 0 "Init" 1 "FH_Schalter_auto_tief_betaetigt" ;
VAL_ 976 FT_FH_Bew_hoch 0 "Init" 1 "FH_in_Bewegung_hoch" ;
VAL_ 976 FT_FH_Bew_tief 0 "Init" 1 "FH_in_Bewegung_tief" ;
VAL_ 976 FT_FH_Fang 0 "ausserhalb_Fangbereich" 1 "innerhalb_Fangbereich" ;
VAL_ 976 FT_FH_Block 0 "Init" 1 "Fenster_Block" ;
VAL_ 976 FT_FH_Thermo 0 "Init" 1 "Thermoschutz_aktiv" ;
VAL_ 976 FT_UEKB_aktiviert 0 "Init" 1 "UEKB_aktiv" ;
VAL_ 976 ASW_HMI_defekt 0 "iO" 1 "defekt" ;
VAL_ 976 FT_FH_normiert 1 "Fenster_normiert" ;
VAL_ 976 FT_Schliesstaster 1 "Schliesstaster_betaetigt" ;
VAL_ 976 FT_Zuziehhilfe_aktiv 0 "Init" 1 "Zuziehilfe_aktiv" ;
VAL_ 976 FT_SP_ausgerastet 0 "Init" 1 "Spiegel_ausgerastet" ;
VAL_ 976 FT_SP_lr_aktiv 0 "Init" 1 "Spiegel_xAchse_aktiv" ;
VAL_ 976 FT_SP_ht_aktiv 0 "Init" 1 "Spiegel_yAchse_aktiv" ;
VAL_ 976 ASW_wakeup 0 "Sleep" 1 "Wakeup" ;
VAL_ 976 FT_Oben_Block_erw 0 "Fensterheber_nicht_in_Blockerwar" 1 "Fensterheber_in_Blockerwartung_o" ;
VAL_ 976 FT_Unten_Block_erw 0 "Fensterheber_nicht_in_Blockerwar" 1 "Fensterheber_in_Blockerwartung_u" ;
VAL_ 976 FT_Kisi_li_aktiv 0 "inaktiv" 1 "aktiv" ;
VAL_ 976 FT_Kisi_re_aktiv 0 "inaktiv" 1 "aktiv" ;
VAL_ 976 FT_Kisi_Taster_li 0 "nicht_betaetigt" 1 "betaetigt" ;
VAL_ 976 FT_Kisi_Taster_re 0 "nicht_betaetigt" 1 "betaetigt" ;
VAL_ 976 FT_BFS_Fond_Freigabe 0 "Init" 1 "Freigabe_fuer_Fondbedienung_BFS" ;
VAL_ 976 FT_Kisi_Fehler 0 "kein_Fehler" 1 "Fehler" ;
VAL_ 976 FT_Daemmglas 0 "Normalglas_verbaut" 1 "Daemmglas_verbaut" ;
VAL_ 976 FT_SP_Heizung_Status 0 "Init" 1 "Status_Spiegelheizung_ein" ;
VAL_ 976 ASW_Warnung_aktiv_FS 0 "nicht_angefordert" 1 "angefordert" ;
VAL_ 976 FT_FH_Pos_oben 1 "Scheibe oben (nach Absenken auf Position) " ;
VAL_ 976 FT_Tuerschloss_defekt 0 "Tuerschloss_funktionsfaehig" 1 "Tuerschloss_defekt" ;
VAL_ 976 FT_SWA_Taster 0 "Taster_nicht_betaetigt" 1 "Taster_betaetigt" ;
VAL_ 976 SWA_HMI_Diagnose 0 "kein_Fehler_erkannt" 1 "Fehler_Taster_erkannt" 2 "Fehler_LED_erkannt" 3 "Fehler_LED_und_Taster_erkannt" ;
VAL_ 976 FS_Status_eTAG 0 "Init" 1 "Griff_ausgefahren" 2 "Griff_eingefahren" 3 "Fehler" ;
VAL_ 997 FT_Tuer_Status 0 "Init" 1 "Tuer_geschlossen" 2 "Tuer_offen" 3 "Fehler" ;
VAL_ 997 FT_Tuer_Status_QBit 0 "Status_Tuerkontakt_sicher" 1 "Status_Tuerkontakt_unsicher" ;
VAL_ 997 FT_Lock_Taster_02 0 "nicht_betaetigt" 1 "betaetigt" ;
VAL_ 997 FT_Schluesselschalter_zu_02 0 "nicht_betaetigt" 1 "betaetigt" ;
VAL_ 997 FT_BFS_Tuer_Status 0 "Init" 1 "Tuer_geschlossen" 2 "Tuer_offen" 3 "Fehler" ;
VAL_ 997 FT_HBFS_Tuer_Status 0 "Init" 1 "Tuer_geschlossen" 2 "Tuer_offen" 3 "Fehler" ;
VAL_ 997 FT_HFS_Tuer_Status 0 "Init" 1 "Tuer_geschlossen" 2 "Tuer_offen" 3 "Fehler" ;
VAL_ 997 FT_Tueroeffnen_Warnung 0 "Tuerwarnung_nicht_aktiv" 1 "Tuerwarnung_aktiv" ;
VAL_ 997 FT_SP_Heizung_ein 0 "Aus" 1 "Ein" ;
VAL_ 997 FT_Kisi_Taster_li_02 0 "nicht_betaetigt" 1 "betaetigt" ;
VAL_ 997 FT_Kisi_Taster_re_02 0 "nicht_betaetigt" 1 "betaetigt" ;
VAL_ 997 FT_TD_Taste_Status 0 "kein_Fehler" 1 "Kurzschluss_nach_Minus" 2 "Kurzschluss_nach_Plus" 3 "Leitungsunterbrechung" ;
VAL_ 997 FT_TCR_Mode_aktiv 0 "TCR_Mode_deaktiv" 1 "TCR_Mode_aktiv" ;
VAL_ 997 FS_Push_Tuergriff 0 "nicht_erkannt" 1 "erkannt" ;
VAL_ 1449 TSG_FlHz_FS_NTC_A 125 "Fehler_NTC_OpenLoad__KS_Plus" 126 "Fehler_NTC_Overload__KS_Minus" 127 "Init" ;
VAL_ 1449 TSG_FlHz_FS_FnAbbruchHzKreis_A 0 "OK" 1 "FunktionsAbbruch" ;
VAL_ 1449 TSG_FlHz_FS_NTC_B 125 "Fehler_NTC_OpenLoad__KS_Plus" 126 "Fehler_NTC_Overload__KS_Minus" 127 "Init" ;
VAL_ 1449 TSG_FlHz_FS_FnAbbruchHzKreis_B 0 "OK" 1 "FunktionsAbbruch" ;
VAL_ 975 HBFS_Tuer_geoeffnet 0 "geschlossen" 1 "offen" ;
VAL_ 975 HBFS_verriegelt 0 "nicht_verriegelt" 1 "verriegelt" ;
VAL_ 975 HBFS_gesafet 0 "nicht_gesafet" 1 "gesafet" ;
VAL_ 975 HBFS_Heckrollotaster_betaetigt 0 "keine_Verfahranweisung_in_Richtung_Hoch" 1 "In_Richtung_Hoch_Verfahren" ;
VAL_ 975 HBFS_Tuerschloss_defekt 0 "Tuerschloss_funktionsfaehig" 1 "Tuerschloss_defekt" ;
VAL_ 975 HBFS_Unlock_Taster 0 "nicht_betaetigt" 1 "betaetigt" ;
VAL_ 975 HBFS_Lock_Taster 0 "nicht_betaetigt" 1 "betaetigt" ;
VAL_ 975 HBFS_Sperrklinke 0 "Schloss_in_Vorraste_und_Hauptraste" 1 "Tuer_auf_oder_Tuer_Position_zwischen_Vor_und_Hauptraste" ;
VAL_ 975 HBFS_TAG_betaetigt 0 "nicht_betaetigt" 1 "betaetigt" ;
VAL_ 975 HBFS_TIG_betaetigt 0 "nicht_betaetigt" 1 "betaetigt" ;
VAL_ 975 HBFS_FH_S_HFS_AutoHoch 0 "keine_Bedienung" 1 "Automatiklauf_Angefordert" ;
VAL_ 975 HBFS_FH_S_HFS_AutoTief 0 "keine_Bedienung" 1 "Automatiklauf_Angefordert" ;
VAL_ 975 HBFS_FH_S_HFS_ManHoch 0 "keine_Bedienung" 1 "Manueller_Lauf_Angefordert" ;
VAL_ 975 HBFS_FH_S_HFS_ManTief 0 "keine_Bedienung" 1 "Manueller_Lauf_Angefordert" ;
VAL_ 975 HBFS_Tuer_Status 0 "Init" 1 "Tuer geschlossen" 2 "Tuer offen" 3 "Fehler" ;
VAL_ 975 HBFS_SAD_Schalter 0 "nicht_betaetigt" 5 "AUF_manuell" 6 "AUF_automatik" 7 "ZU_manuell" 8 "ZU_automatik" 13 "nicht_verfuegbar" 14 "Init" 15 "Fehler" ;
VAL_ 975 HBFS_FH_S_ManHoch 0 "nicht_betaetigt" 1 "betaetigt" ;
VAL_ 975 HBFS_FH_S_AutoHoch 0 "nicht_betaetigt" 1 "betaetigt" ;
VAL_ 975 HBFS_FH_S_ManTief 0 "nicht_betaetigt" 1 "betaetigt" ;
VAL_ 975 HBFS_FH_S_AutoTief 0 "nicht_betaetigt" 1 "betaetigt" ;
VAL_ 975 HBFS_FH_Bew_hoch 0 "inaktiv" 1 "aktiv" ;
VAL_ 975 HBFS_FH_Bew_tief 0 "inaktiv" 1 "aktiv" ;
VAL_ 975 HBFS_FH_Fang 0 "ausserhalb_Fangbereich" 1 "innerhalb_Fangbereich" ;
VAL_ 975 HBFS_FH_Block 0 "inaktiv" 1 "aktiv" ;
VAL_ 975 HBFS_FH_Thermo 0 "inaktiv" 1 "aktiv" ;
VAL_ 975 HBFS_UEKB_aktiviert 0 "inaktiv" 1 "aktiv" ;
VAL_ 975 HBFS_Tueroeffnen_Warnung 0 "Tuerwarnung_nicht_aktiv" 1 "Tuerwarnung_aktiv" ;
VAL_ 975 HBFS_FH_normiert 0 "inaktiv" 1 "aktiv" ;
VAL_ 975 ASW_Warnung_aktiv_HBFS 0 "nicht_angefordert" 1 "angefordert" ;
VAL_ 975 HBFS_Zuziehhilfe_aktiv 0 "Init" 1 "Zuziehhilfe_aktiv" ;
VAL_ 975 HBFS_Seitenrollo_hoch 1 "Seitenrollo_in_Bewegung_hoch" ;
VAL_ 975 HBFS_Seitenrollo_tief 1 "Seitenrollo_in_Bewegung_tief" ;
VAL_ 975 HBFS_Status_KiSi 0 "inaktiv" 1 "aktiv" ;
VAL_ 975 SSR_HBFS_Pos_Unten 0 "SSR_Oben" 1 "SSR_Unten" ;
VAL_ 975 HBFS_Oben_Block_erw 0 "Fensterheber_nicht_in_Blockerwar" 1 "Fensterheber_in_Blockerwartung_o" ;
VAL_ 975 HBFS_Unten_Block_erw 0 "Fensterheber_nicht_in_Blockerwar" 1 "Fensterheber_in_Blockerwartung_u" ;
VAL_ 975 MTHBFS_M_Taste 0 "nicht_betaetigt" 1 "betaetigt" ;
VAL_ 975 MTHBFS_Pos1 0 "nicht_betaetigt" 1 "betaetigt" ;
VAL_ 975 MTHBFS_Pos2 0 "nicht_betaetigt" 1 "betaetigt" ;
VAL_ 975 MTHBFS_Pos3 0 "nicht_betaetigt" 1 "betaetigt" ;
VAL_ 975 HBFS_MRollo_Schalter 0 "nicht_betaetigt" 1 "ZU_manuell" 2 "ZU_automatik" 3 "AUF_manuell" 4 "AUF_automatik" 5 "nicht_verfuegbar" 6 "Init" 7 "Fehler" ;
VAL_ 975 HBFS_Lock_Taster_inv 0 "Lock Taster betätgit" 1 "Lock Taster nicht betätigt" ;
VAL_ 975 HBFS_Status_KiSi_inv 0 "aktiv" 1 "inaktiv" ;
VAL_ 975 HBFS_Status_eTAG 0 "Init" 1 "Griff_ausgefahren" 2 "Griff_eingefahren" 3 "Fehler" ;
VAL_ 975 HBFS_Tuer_Status_QBit 0 "Status_Tuerkontakt_sicher" 1 "Status_Tuerkontakt_unsicher" ;
VAL_ 975 HBFS_TIG_betaetigt_schliessen 0 "nicht_betaetigt" 1 "betaetigt" ;
VAL_ 1457 TSG_FlHz_HBFS_NTC_A 125 "Fehler_NTC_OpenLoad__KS_Plus" 126 "Fehler_NTC_Overload__KS_Minus" 127 "Init" ;
VAL_ 1457 TSG_FlHz_HBFS_FnAbbruchHzKreis_A 0 "OK" 1 "FunktionsAbbruch" ;
VAL_ 1457 TSG_FlHz_HBFS_NTC_B 125 "Fehler_NTC_OpenLoad__KS_Plus" 126 "Fehler_NTC_Overload__KS_Minus" 127 "Init" ;
VAL_ 1457 TSG_FlHz_HBFS_FnAbbruchHzKreis_B 0 "OK" 1 "FunktionsAbbruch" ;
VAL_ 974 HFS_Tuer_geoeffnet 0 "geschlossen" 1 "offen" ;
VAL_ 974 HFS_verriegelt 0 "nicht_verriegelt" 1 "verriegelt" ;
VAL_ 974 HFS_gesafet 0 "nicht_gesafet" 1 "gesafet" ;
VAL_ 974 HFS_Heckrollotaster_betaetigt 0 "keine_Verfahranweisung_in_Richtung_Hoch" 1 "In_Richtung_Hoch_Verfahren" ;
VAL_ 974 HFS_Tuerschloss_defekt 0 "Tuerschloss_funktionsfaehig" 1 "Tuerschloss_defekt" ;
VAL_ 974 HFS_Unlock_Taster 0 "nicht_betaetigt" 1 "betaetigt" ;
VAL_ 974 HFS_Lock_Taster 0 "nicht_betaetigt" 1 "betaetigt" ;
VAL_ 974 HFS_Sperrklinke 0 "Schloss_in_Vorraste_und_Hauptraste" 1 "Tuer_auf_oder_Tuer_Position_zwischen_Vor_und_Hauptraste" ;
VAL_ 974 HFS_TAG_betaetigt 0 "nicht_betaetigt" 1 "betaetigt" ;
VAL_ 974 HFS_TIG_betaetigt 0 "nicht_betaetigt" 1 "betaetigt" ;
VAL_ 974 HFS_FH_S_HBFS_AutoHoch 0 "keine_Bedienung" 1 "Automatiklauf_Angefordert" ;
VAL_ 974 HFS_FH_S_HBFS_AutoTief 0 "keine_Bedienung" 1 "Automatiklauf_Angefordert" ;
VAL_ 974 HFS_FH_S_HBFS_ManHoch 0 "keine_Bedienung" 1 "Manueller_Lauf_Angefordert" ;
VAL_ 974 HFS_FH_S_HBFS_ManTief 0 "keine_Bedienung" 1 "Manueller_Lauf_Angefordert" ;
VAL_ 974 HFS_Tuer_Status 0 "Init" 1 "Tuer geschlossen" 2 "Tuer offen" 3 "Fehler" ;
VAL_ 974 HFS_SAD_Schalter 0 "nicht_betaetigt" 5 "AUF_manuell" 6 "AUF_automatik" 7 "ZU_manuell" 8 "ZU_automatik" 13 "nicht_verfuegbar" 14 "Init" 15 "Fehler" ;
VAL_ 974 HFS_FH_S_ManHoch 0 "nicht_betaetigt" 1 "betaetigt" ;
VAL_ 974 HFS_FH_S_AutoHoch 0 "nicht_betaetigt" 1 "betaetigt" ;
VAL_ 974 HFS_FH_S_ManTief 0 "nicht_betaetigt" 1 "betaetigt" ;
VAL_ 974 HFS_FH_S_AutoTief 0 "nicht_betaetigt" 1 "betaetigt" ;
VAL_ 974 HFS_FH_Bew_hoch 0 "inaktiv" 1 "aktiv" ;
VAL_ 974 HFS_FH_Bew_tief 0 "inaktiv" 1 "aktiv" ;
VAL_ 974 HFS_FH_Fang 0 "ausserhalb_Fangbereich" 1 "innerhalb_Fangbereich" ;
VAL_ 974 HFS_FH_Block 0 "inaktiv" 1 "aktiv" ;
VAL_ 974 HFS_FH_Thermo 0 "inaktiv" 1 "aktiv" ;
VAL_ 974 HFS_UEKB_aktiviert 0 "inaktiv" 1 "aktiv" ;
VAL_ 974 HFS_Tueroeffnen_Warnung 0 "Tuerwarnung_nicht_aktiv" 1 "Tuerwarnung_aktiv" ;
VAL_ 974 HFS_FH_normiert 0 "inaktiv" 1 "aktiv" ;
VAL_ 974 ASW_Warnung_aktiv_HFS 0 "nicht_angefordert" 1 "angefordert" ;
VAL_ 974 HFS_Zuziehhilfe_aktiv 0 "Init" 1 "Zuziehhilfe_aktiv" ;
VAL_ 974 HFS_Seitenrollo_hoch 1 "Seitenrollo_in_Bewegung_hoch" ;
VAL_ 974 HFS_Seitenrollo_tief 1 "Seitenrollo_in_Bewegung_tief" ;
VAL_ 974 HFS_Status_KiSi 0 "inaktiv" 1 "aktiv" ;
VAL_ 974 SSR_HFS_Pos_Unten 0 "SSR_Oben" 1 "SSR_Unten" ;
VAL_ 974 HFS_Oben_Block_erw 0 "Fensterheber_nicht_in_Blockerwar" 1 "Fensterheber_in_Blockerwartung_o" ;
VAL_ 974 HFS_Unten_Block_erw 0 "Fensterheber_nicht_in_Blockerwar" 1 "Fensterheber_in_Blockerwartung_u" ;
VAL_ 974 MTHFS_M_Taste 0 "nicht_betaetigt" 1 "betaetigt" ;
VAL_ 974 MTHFS_Pos1 0 "nicht_betaetigt" 1 "betaetigt" ;
VAL_ 974 MTHFS_Pos2 0 "nicht_betaetigt" 1 "betaetigt" ;
VAL_ 974 MTHFS_Pos3 0 "nicht_betaetigt" 1 "betaetigt" ;
VAL_ 974 HFS_MRollo_Schalter 0 "nicht_betaetigt" 1 "ZU_manuell" 2 "ZU_automatik" 3 "AUF_manuell" 4 "AUF_automatik" 5 "nicht_verfuegbar" 6 "Init" 7 "Fehler" ;
VAL_ 974 HFS_Lock_Taster_inv 0 "Lock Taster betätgit" 1 "Lock Taster nicht betätigt" ;
VAL_ 974 HFS_Status_eTAG 0 "Init" 1 "Griff_ausgefahren" 2 "Griff_eingefahren" 3 "Fehler" ;
VAL_ 974 HFS_Tuer_Status_QBit 0 "Status_Tuerkontakt_sicher" 1 "Status_Tuerkontakt_unsicher" ;
VAL_ 974 HFS_TCR_Mode_aktiv 0 "TCR_Mode_deaktiv" 1 "TCR_Mode_aktiv" ;
VAL_ 1458 TSG_FlHz_HFS_NTC_A 125 "Fehler_NTC_OpenLoad__KS_Plus" 126 "Fehler_NTC_Overload__KS_Minus" 127 "Init" ;
VAL_ 1458 TSG_FlHz_HFS_FnAbbruchHzKreis_A 0 "OK" 1 "FunktionsAbbruch" ;
VAL_ 1458 TSG_FlHz_HFS_NTC_B 125 "Fehler_NTC_OpenLoad__KS_Plus" 126 "Fehler_NTC_Overload__KS_Minus" 127 "Init" ;
VAL_ 1458 TSG_FlHz_HFS_FnAbbruchHzKreis_B 0 "OK" 1 "FunktionsAbbruch" ;
VAL_ 346 MO_Anforderung_HMS 0 "keine_Anforderung" 1 "halten" 2 "parken" 3 "halten_Standby" 4 "anfahren" 5 "Loesen_ueber_Rampe" 7 "HMS_uebernehmen" ;
VAL_ 346 TSK_vMax_aktuell 254 "kein_Limit_aktiv" 255 "Init" ;
VAL_ 346 TSK_Status_EA 0 "Aus" 1 "Init_oder_nicht_verbaut" 3 "Aktiv" 4 "Uebertreten" 5 "Abschaltung_laeuft" 6 "Reversibel_aus" 7 "Fehler" ;
VAL_ 346 TSK_vMax_Fahrerassistenz 511 "Init_ungueltig_keine_Beschraenkung" ;
VAL_ 346 TSK_Einheit_vMax_Fahrerassistenz 0 "kmh" 1 "mph" ;
VAL_ 346 TSK_Status_PLA 0 "Aus_Funktionsbereit" 1 "Init_oder_nicht_verbaut" 2 "aktivierbar" 3 "aktiv" 5 "Abschaltung_laeuft" 6 "reversibel_aus" 7 "Fehler" ;
VAL_ 346 TSK_aktives_System 0 "keine_Funktion_aktiv" 1 "GRA_ACC" 2 "ARA" 3 "Speedlimiter" 4 "IPA" 5 "PLA" 6 "PEA_Ausrollassistent" 7 "EA" ;
VAL_ 346 TSK_erhoehter_Fahrwiderstand 0 "kein_erhoehter_Fahrwiderstand" 1 "erhoehter_Fahrwiderstand" ;
VAL_ 346 TSK_Anf_Antriebsmoment 0 "keine_Anforderung" 1 "Anforderung_aktiv" ;
VAL_ 346 TSK_Status_ARA 0 "Aus" 1 "Init_oder_nicht_verbaut" 2 "aktivierbar" 3 "aktiv" 5 "abschaltung_laeuft" 6 "reversibel_aus" 7 "Fehler" ;
VAL_ 346 TSK_Status_IPA 0 "Aus_Funktionsbereit" 1 "Init_oder_nicht_verbaut" 2 "aktivierbar" 3 "aktiv" 4 "Fahreruebernahme_angefordert" 5 "Abschaltung_laueft" 6 "reversibel_aus" 7 "Fehler" ;
VAL_ 2589283609 UGDO_LED_Code_01 0 "Init" 1 "LED_green_on" 2 "LED_yellow_on" 3 "LED_red_on" 4 "LED_green_flashing_with_10_Hz" 5 "LED_yellow_flashing_with_1_Hz" 16 "LED_flashing_off" 17 "LED_green_flashing_1_x_1_Hz" 18 "LED_green_flashing_2_x_1_Hz" 19 "LED_green_flashing_3_x_1_Hz" 20 "LED_green_flashing_4_x_1_Hz" 21 "LED_green_flashing_5_x_1_Hz" 22 "LED_green_flashing_6_x_1_Hz" 23 "LED_green_flashing_7_x_1_Hz" 24 "LED_green_flashing_8_x_1_Hz" 25 "LED_green_flashing_9_x_1_Hz" 26 "LED_green_flashing_10_x_1_Hz" 27 "LED_green_flashing_11_x_1_Hz" 28 "LED_green_flashing_12_x_1_Hz" 29 "LED_green_flashing_13_x_1_Hz" 30 "LED_green_flashing_14_x_1_Hz" ;
VAL_ 2589283609 UGDO_Function_01 0 "LED Function" 1 "Transceiver locked" 2 "reserviert" 3 "reserviert" 4 "Successful learned" 5 "reserviert" 6 "Timeout learning" 7 "Fehler" ;
VAL_ 2589283609 UGDO_Failure_Antenne 0 "normal" 1 "Fehler" ;
VAL_ 2589283609 UGDO_Failure_Codierung 0 "normal" 1 "Fehler" ;
VAL_ 2589283609 UGDO_Failure_Hardware 0 "normal" 1 "Fehler" ;
VAL_ 2589283609 UGDO_ResponseError 0 "normal" 1 "Fehler" ;
VAL_ 2589283609 UGDO_Channel_1 0 "not_trained" 1 "trained" ;
VAL_ 2589283609 UGDO_Channel_2 0 "not_trained" 1 "trained" ;
VAL_ 2589283609 UGDO_Channel_3 0 "not_trained" 1 "trained" ;
VAL_ 2589283609 UGDO_Channel_4 0 "not_trained" 1 "trained" ;
VAL_ 2589283609 UGDO_Channel_5 0 "not_trained" 1 "trained" ;
VAL_ 2589283609 UGDO_Channel_6 0 "not_trained" 1 "trained" ;
VAL_ 2589283609 UGDO_Channel_7 0 "not_trained" 1 "trained" ;
VAL_ 2589283609 UGDO_Channel_8 0 "not_trained" 1 "trained" ;
VAL_ 2589283609 UGDO_Channel_9 0 "not_trained" 1 "trained" ;
VAL_ 2589283609 UGDO_Channel_10 0 "not_trained" 1 "trained" ;
VAL_ 2589283609 UGDO_Channel_11 0 "not_trained" 1 "trained" ;
VAL_ 2589283609 UGDO_Channel_12 0 "not_trained" 1 "trained" ;
VAL_ 2589283609 UGDO_Channel_13 0 "not_trained" 1 "trained" ;
VAL_ 2589283609 UGDO_Channel_14 0 "not_trained" 1 "trained" ;
VAL_ 2589283609 UGDO_Channel_15 0 "not_trained" 1 "trained" ;
VAL_ 2589283609 UGDO_DoorState 0 "idle" 1 "move" 2 "open" 3 "close" 4 "movement_stopped_stop_movement" 5 "no_com_door_out_of_reach" 6 "communication_error" ;
VAL_ 1718 UH_Typ 0 "undefiniert" 1 "Quarzuhr" 2 "DCF" 3 "GPS" ;
VAL_ 1718 UH_DLS 0 "Winterzeit" 1 "Sommerzeit" ;
VAL_ 1718 UH_Monat 0 "Init" 14 "Relatives_Datum" 15 "Fehler" ;
VAL_ 1718 UH_Tag 0 "Init" ;
